VERSION ""

NS_ :

BS_:

BU_: OLDC EWP2 iBAU PSB EWP ESC EVP2 Dummy EVP1 SCU AAF eCALL H_U AEB IBOX LCA MCU SPAS CGW OBC TMU EPB SMK BCF MDPS CPD vDCM ACU vBDM AAF_2 CCM AAF_3 CLU ICSC LVR LDC CDM VCMS FCA IBU SCC PLC VCRM TCU EMS TPMS BMS NEMS LDW_LKA AAF_Tester DATC eCall VESS VCU ODS

BO_ 1301 CLU14: 8 CGW
 SG_ CF_Clu_ADrUNValueSet : 0|3@1+ (1,0) [0|7] ""  Dummy,vBDM
 SG_ CF_Clu_ADrLNValueSet : 3|3@1+ (1,0) [0|7] ""  Dummy
 SG_ CF_Clu_EscortHLNValueSet : 6|2@1+ (1,0) [0|3] ""  Dummy
 SG_ CF_Clu_DoorLSNValueSet : 8|3@1+ (1,0) [0|7] ""  Dummy
 SG_ CF_Clu_PSMNValueSet : 11|3@1+ (1,0) [0|7] ""  Dummy
 SG_ CF_Clu_TTUnlockNValueSet : 14|2@1+ (1,0) [0|3] ""  Dummy
 SG_ CF_Clu_ATTurnNValueSet : 16|2@1+ (1,0) [0|3] ""  Dummy
 SG_ CF_Clu_SCMNValueSet : 18|2@1+ (1,0) [0|3] ""  Dummy
 SG_ CF_Clu_WlightNValueSet : 20|2@1+ (1,0) [0|3] ""  Dummy
 SG_ CF_Clu_TempUnitNValueSet : 22|2@1+ (1,0) [0|3] ""  DATC,TMU
 SG_ CF_Clu_TrfChgSet : 27|2@1+ (1,0) [0|3] ""  Dummy
 SG_ CF_Clu_OTTurnNValueSet : 29|3@1+ (1,0) [0|7] ""  Dummy
 SG_ CF_Clu_LcaNValueSet : 32|2@1+ (1,0) [0|3] ""  Dummy
 SG_ CF_Clu_RctaNValueSet : 34|2@1+ (1,0) [0|3] ""  Dummy
 SG_ CF_Clu_RcwNValueSet : 36|2@1+ (1,0) [0|3] ""  Dummy
 SG_ CF_Clu_EcsOffNValueSet : 38|3@1+ (1,0) [0|3] ""  iBAU
 SG_ CF_Clu_SccNaviCrvNValueSet : 41|2@1+ (1,0) [0|3] ""  Dummy
 SG_ CF_Clu_SccNaviCamNValueSet : 43|2@1+ (1,0) [0|3] ""  Dummy
 SG_ CF_Clu_SccAebNValueSet : 45|2@1+ (1,0) [0|3] ""  Dummy
 SG_ CF_Clu_LkasModeNValueSet : 47|2@1+ (1,0) [0|3] ""  Dummy
 SG_ CF_Clu_FcwNValueSet : 51|2@1+ (1,0) [0|3] ""  Dummy
 SG_ CF_Clu_PasSpkrLvNValueSet : 53|3@1+ (1,0) [0|7] ""  Dummy
 SG_ CF_Clu_SccDrvModeNValueSet : 56|3@1+ (1,0) [0|7] ""  Dummy
 SG_ CF_Clu_HAnBNValueSet : 59|2@1+ (1,0) [0|3] ""  Dummy
 SG_ CF_Clu_HfreeTrunkTgNValueSet : 61|3@1+ (1,0) [0|7] ""  Dummy

BO_ 1031 VCMS12: 8 VCMS
 SG_ CR_Cms_EVmaxPower : 48|16@1+ (10,0) [0|655350] "W"  BMS

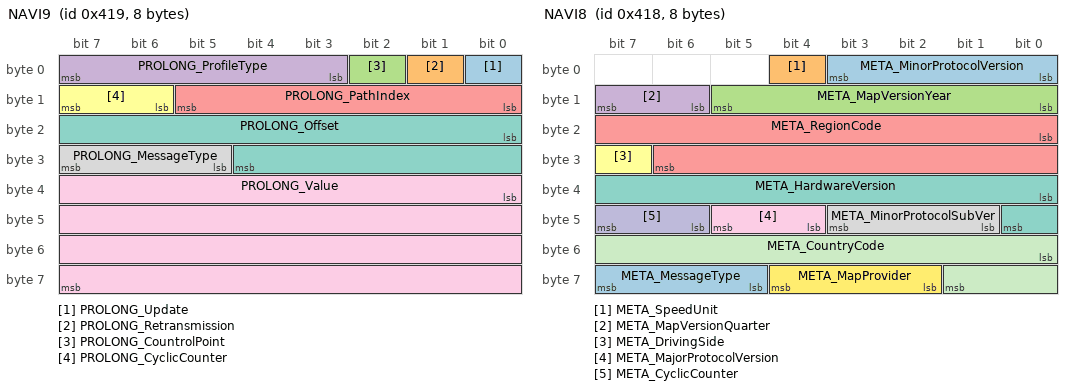
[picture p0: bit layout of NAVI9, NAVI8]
BO_ 1049 NAVI9: 8 CGW
 SG_ PROLONG_Update : 0|1@1+ (1,0) [0|1] ""  VCU
 SG_ PROLONG_Retransmission : 1|1@1+ (1,0) [0|1] ""  VCU
 SG_ PROLONG_CountrolPoint : 2|1@1+ (1,0) [0|1] ""  VCU
 SG_ PROLONG_ProfileType : 3|5@1+ (1,0) [0|31] ""  VCU
 SG_ PROLONG_PathIndex : 8|6@1+ (1,0) [0|63] ""  VCU
 SG_ PROLONG_CyclicCounter : 14|2@1+ (1,0) [0|3] ""  VCU
 SG_ PROLONG_Offset : 16|13@1+ (1,0) [0|8191] ""  VCU
 SG_ PROLONG_MessageType : 29|3@1+ (1,0) [0|7] ""  VCU
 SG_ PROLONG_Value : 32|32@1+ (1,0) [0|4294967295] ""  VCU

BO_ 1048 NAVI8: 8 CGW
 SG_ META_MinorProtocolVersion : 0|4@1+ (1,0) [0|0] ""  VCU
 SG_ META_SpeedUnit : 4|1@1+ (1,0) [0|0] ""  VCU
 SG_ META_MapVersionYear : 8|6@1+ (1,0) [0|0] ""  VCU
 SG_ META_MapVersionQuarter : 14|2@1+ (1,0) [0|0] ""  VCU
 SG_ META_RegionCode : 16|15@1+ (1,0) [0|0] ""  VCU
 SG_ META_DrivingSide : 31|1@1+ (1,0) [0|0] ""  VCU
 SG_ META_HardwareVersion : 32|9@1+ (1,0) [0|0] ""  VCU
 SG_ META_MinorProtocolSubVer : 41|3@1+ (1,0) [0|0] ""  VCU
 SG_ META_MajorProtocolVersion : 44|2@1+ (1,0) [0|0] ""  VCU
 SG_ META_CyclicCounter : 46|2@1+ (1,0) [0|0] ""  VCU
 SG_ META_CountryCode : 48|10@1+ (1,0) [0|0] ""  VCU
 SG_ META_MapProvider : 58|3@1+ (1,0) [0|0] ""  VCU
 SG_ META_MessageType : 61|3@1+ (1,0) [0|0] ""  VCU

BO_ 1051 NAVI11: 8 CGW
 SG_ SEG_DirectionLanes : 0|3@1+ (1,0) [0|7] ""  VCU
 SG_ SEG_OppositeLanes : 3|2@1+ (1,0) [0|3] ""  VCU
 SG_ SEG_DividedRoad : 5|2@1+ (1,0) [0|3] ""  VCU
 SG_ SEG_SpeedLimitType : 8|3@1+ (1,0) [0|7] ""  VCU
 SG_ SEG_SpeedLimit : 11|5@1+ (1,0) [0|31] ""  VCU
 SG_ SEG_FormOfWay : 16|4@1+ (1,0) [0|15] ""  VCU
 SG_ SEG_ComplexIntersection : 20|2@1+ (1,0) [0|3] ""  VCU
 SG_ SEG_CalculatedRoute : 22|2@1+ (1,0) [0|3] ""  VCU
 SG_ SEG_FunctionalRoadClass : 24|3@1+ (1,0) [0|7] ""  VCU
 SG_ SEG_RelativeProbability : 27|5@1+ (3.333,0) [0|31] ""  VCU
 SG_ SEG_Update : 32|1@1+ (1,0) [0|1] ""  VCU
 SG_ SEG_Retransmission : 33|1@1+ (1,0) [0|1] ""  VCU
 SG_ SEG_BuiltUpArea : 34|2@1+ (1,0) [0|3] ""  VCU
 SG_ SEG_Bridge : 36|2@1+ (1,0) [0|3] ""  VCU
 SG_ SEG_Tunnel : 38|2@1+ (1,0) [0|3] ""  VCU
 SG_ SEG_PathIndex : 40|6@1+ (1,0) [0|63] ""  VCU
 SG_ SEG_CyclicCounter : 46|2@1+ (1,0) [0|3] ""  VCU
 SG_ SEG_Offset : 48|13@1+ (1,0) [0|8191] ""  VCU
 SG_ SEG_MessageType : 61|3@1+ (1,0) [0|7] ""  VCU

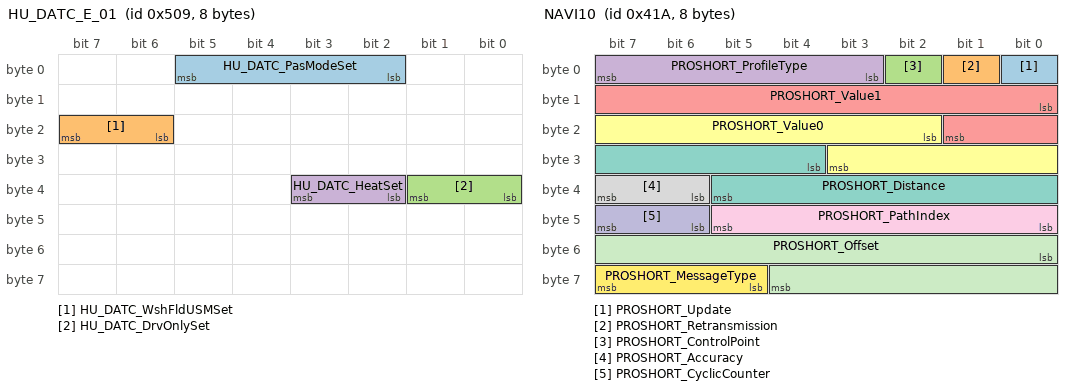
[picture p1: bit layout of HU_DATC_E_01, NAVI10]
BO_ 1289 HU_DATC_E_01: 8 CGW
 SG_ HU_DATC_PasModeSet : 2|4@1+ (1,0) [0|0] ""  DATC
 SG_ HU_DATC_WshFldUSMSet : 22|2@1+ (1,0) [0|3] ""  DATC
 SG_ HU_DATC_DrvOnlySet : 32|2@1+ (1,0) [0|0] ""  DATC
 SG_ HU_DATC_HeatSet : 34|2@1+ (1,0) [0|0] ""  DATC

BO_ 1050 NAVI10: 8 CGW
 SG_ PROSHORT_Update : 0|1@1+ (1,0) [0|1] ""  VCU
 SG_ PROSHORT_Retransmission : 1|1@1+ (1,0) [0|1] ""  VCU
 SG_ PROSHORT_ControlPoint : 2|1@1+ (1,0) [0|1] ""  VCU
 SG_ PROSHORT_ProfileType : 3|5@1+ (1,0) [0|31] ""  VCU
 SG_ PROSHORT_Value1 : 8|10@1+ (1,0) [0|1023] ""  VCU
 SG_ PROSHORT_Value0 : 18|10@1+ (1,0) [0|1023] ""  VCU
 SG_ PROSHORT_Distance : 28|10@1+ (1,0) [0|1023] ""  VCU
 SG_ PROSHORT_Accuracy : 38|2@1+ (1,0) [0|3] ""  VCU
 SG_ PROSHORT_PathIndex : 40|6@1+ (1,0) [0|63] ""  VCU
 SG_ PROSHORT_CyclicCounter : 46|2@1+ (1,0) [0|3] ""  VCU
 SG_ PROSHORT_Offset : 48|13@1+ (1,0) [0|8191] ""  VCU
 SG_ PROSHORT_MessageType : 61|3@1+ (1,0) [0|7] ""  VCU

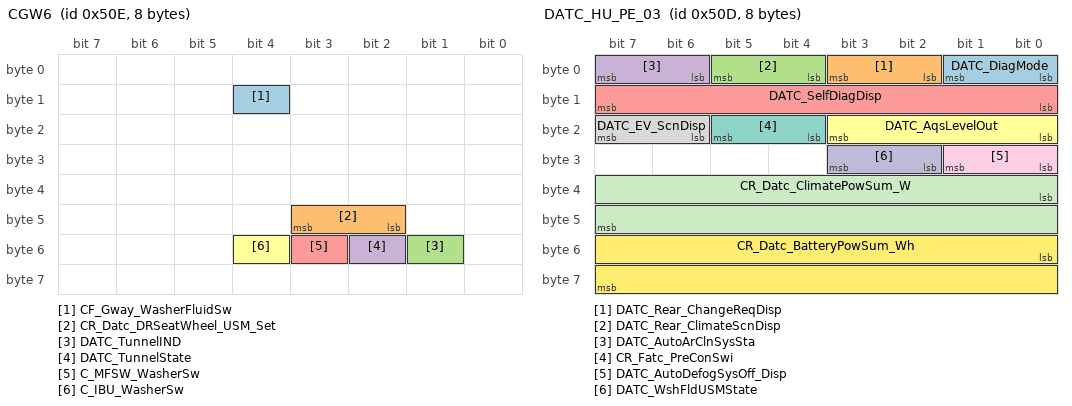
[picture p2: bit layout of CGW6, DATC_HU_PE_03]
BO_ 1294 CGW6: 8 CGW
 SG_ CF_Gway_WasherFluidSw : 12|1@1+ (1,0) [0|1] ""  H_U,vBDM
 SG_ CR_Datc_DRSeatWheel_USM_Set : 42|2@1+ (1,0) [0|3] ""  DATC
 SG_ DATC_TunnelIND : 49|1@1+ (1,0) [0|1] ""  DATC
 SG_ DATC_TunnelState : 50|1@1+ (1,0) [0|1] ""  DATC
 SG_ C_MFSW_WasherSw : 51|1@1+ (1,0) [0|1] ""  DATC
 SG_ C_IBU_WasherSw : 52|1@1+ (1,0) [0|1] ""  DATC

BO_ 1052 NAVI12: 8 CGW
 SG_ STUB_DirectionLanes : 0|3@1+ (1,0) [0|7] ""  VCU
 SG_ STUB_OppositeLanes : 3|2@1+ (1,0) [0|3] ""  VCU
 SG_ STUB_RightOfWay : 5|2@1+ (1,0) [0|3] ""  VCU
 SG_ STUB_LastStubAtOffset : 7|1@1+ (1,0) [0|1] ""  VCU
 SG_ STUB_TurnAngle : 8|8@1+ (1.417,0) [0|255] ""  VCU
 SG_ STUB_FormOfWay : 16|4@1+ (1,0) [0|15] ""  VCU
 SG_ STUB_ComplexIntersection : 20|2@1+ (1,0) [0|3] ""  VCU
 SG_ STUB_CalculatedRoute : 22|2@1+ (1,0) [0|3] ""  VCU
 SG_ STUB_FunctionalRoadClass : 24|3@1+ (1,0) [0|7] ""  VCU
 SG_ STUB_RelativeProbability : 27|5@1+ (3.333,0) [0|31] ""  VCU
 SG_ STUB_Update : 32|1@1+ (1,0) [0|1] ""  VCU
 SG_ STUB_Retransmission : 33|1@1+ (1,0) [0|1] ""  VCU
 SG_ STUB_SubPathIndex : 34|6@1+ (1,0) [0|63] ""  VCU
 SG_ STUB_PathIndex : 40|6@1+ (1,0) [0|63] ""  VCU
 SG_ STUB_CyclicCounter : 46|2@1+ (1,0) [0|3] ""  VCU
 SG_ STUB_Offset : 48|13@1+ (1,0) [0|8191] ""  VCU
 SG_ STUB_MessageType : 61|3@1+ (1,0) [0|7] ""  VCU

BO_ 1293 DATC_HU_PE_03: 8 DATC
 SG_ DATC_DiagMode : 0|2@1+ (1,0) [0|3] "flag"  CGW,TMU
 SG_ DATC_Rear_ChangeReqDisp : 2|2@1+ (1,0) [0|3] "flag"  CGW,TMU
 SG_ DATC_Rear_ClimateScnDisp : 4|2@1+ (1,0) [0|3] "flag"  CGW,TMU
 SG_ DATC_AutoArClnSysSta : 6|2@1+ (1,0) [0|3] ""  CGW
 SG_ DATC_SelfDiagDisp : 8|8@1+ (1,-1) [0|254] "flag"  CGW,TMU
 SG_ DATC_AqsLevelOut : 16|4@1+ (1,0) [0|3] "flag"  CGW,TMU
 SG_ CR_Fatc_PreConSwi : 20|2@1+ (1,0) [0|3] ""  CGW,TMU
 SG_ DATC_EV_ScnDisp : 22|2@1+ (1,0) [0|3] ""  CGW
 SG_ DATC_AutoDefogSysOff_Disp : 24|2@1+ (1,0) [0|3] ""  CGW
 SG_ DATC_WshFldUSMState : 26|2@1+ (1,0) [0|3] ""  CGW
 SG_ CR_Datc_ClimatePowSum_W : 32|16@1+ (1,0) [0|65534] "Wh"  CGW,TMU
 SG_ CR_Datc_BatteryPowSum_Wh : 48|16@1+ (1,0) [0|65534] "Wh"  CGW,TMU

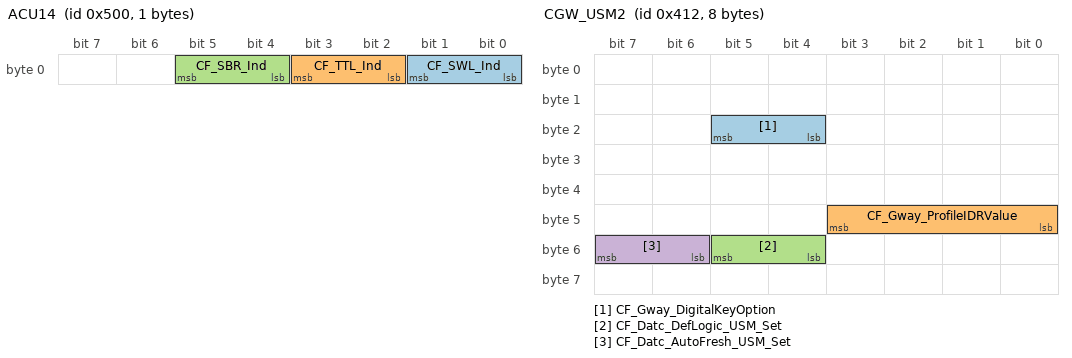
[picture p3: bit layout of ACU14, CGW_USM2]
BO_ 1280 ACU14: 1 ACU
 SG_ CF_SWL_Ind : 0|2@1+ (1,0) [0|3] ""  BMS
 SG_ CF_TTL_Ind : 2|2@1+ (1,0) [0|3] ""  BMS
 SG_ CF_SBR_Ind : 4|2@1+ (1,0) [0|3] ""  BMS

BO_ 1042 CGW_USM2: 8 CGW
 SG_ CF_Gway_DigitalKeyOption : 20|2@1+ (1,0) [0|0] ""  DATC
 SG_ CF_Gway_ProfileIDRValue : 40|4@1+ (1,0) [1|15] ""  DATC
 SG_ CF_Datc_DefLogic_USM_Set : 52|2@1+ (1,0) [0|3] ""  DATC
 SG_ CF_Datc_AutoFresh_USM_Set : 54|2@1+ (1,0) [0|3] ""  DATC

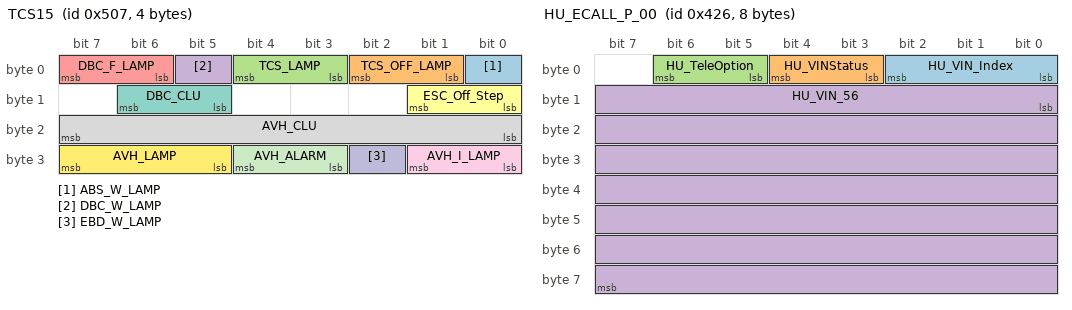
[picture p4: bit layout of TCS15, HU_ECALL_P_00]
BO_ 1287 TCS15: 4 iBAU
 SG_ ABS_W_LAMP : 0|1@1+ (1,0) [0|1] ""  CGW,H_U,NEMS,TMU,vBDM
 SG_ TCS_OFF_LAMP : 1|2@1+ (1,0) [0|1] ""  ACU,Dummy
 SG_ TCS_LAMP : 3|2@1+ (1,0) [0|3] ""  ACU,CGW,H_U,TMU,VCU
 SG_ DBC_W_LAMP : 5|1@1+ (1,0) [0|1] ""  CGW,H_U,TMU
 SG_ DBC_F_LAMP : 6|2@1+ (1,0) [0|3] ""  Dummy
 SG_ ESC_Off_Step : 8|2@1+ (1,0) [0|3] ""  Dummy
 SG_ DBC_CLU : 13|2@1+ (1,0) [0|3] ""  Dummy
 SG_ AVH_CLU : 16|8@1+ (1,0) [0|255] ""  Dummy
 SG_ AVH_I_LAMP : 24|2@1+ (1,0) [0|3] ""  Dummy
 SG_ EBD_W_LAMP : 26|1@1+ (1,0) [0|1] ""  CGW,H_U,TMU
 SG_ AVH_ALARM : 27|2@1+ (1,0) [0|3] ""  Dummy
 SG_ AVH_LAMP : 29|3@1+ (1,0) [0|7] ""  Dummy

BO_ 1044 MM_CGW1: 8 CGW
 SG_ CF_TMU_ICCB_InCurModeState : 0|2@1+ (1,0) [0|3] ""  OBC
 SG_ CF_TMU_EVSE_InCurModeState : 2|2@1+ (1,0) [0|3] ""  OBC

BO_ 852 LVR1: 8 LVR
 SG_ CF_Lvr_PButtonStatus : 0|2@1+ (1,0) [0|3] ""  CGW,VCU,vBDM
 SG_ CF_Lvr_RButtonStatus : 2|2@1+ (1,0) [0|3] ""  VCU
 SG_ CF_Lvr_NButtonStatus : 4|2@1+ (1,0) [0|3] ""  VCU
 SG_ CF_Lvr_DButtonStatus : 6|2@1+ (1,0) [0|3] ""  VCU
 SG_ CF_Lvr_UnLockButtonStatus : 8|2@1+ (1,0) [0|3] ""  VCU
 SG_ CF_Lvr_PRelStat : 10|2@1+ (1,0) [0|3] ""  SMK,VCU
 SG_ CF_Lvr_PosInf : 12|4@1+ (1,0) [0|15] ""  VCU
 SG_ CF_Lvr_PButtonStatus_Reversed : 16|2@1+ (1,0) [0|3] ""  VCU
 SG_ CF_Lvr_RButtonStatus_Reversed : 18|2@1+ (1,0) [0|3] ""  VCU
 SG_ CF_Lvr_NButtonStatus_Reversed : 20|2@1+ (1,0) [0|3] ""  VCU
 SG_ CF_Lvr_DButtonStatus_Reversed : 22|2@1+ (1,0) [0|3] ""  VCU
 SG_ CF_Lvr_UnLkButStatus_Reversed : 24|2@1+ (1,0) [0|3] ""  VCU
 SG_ CF_Lvr_PRelButStatus_Reversed : 26|2@1+ (1,0) [0|3] ""  VCU
 SG_ CF_Lvr_PosCpl : 28|4@1+ (1,0) [0|15] ""  VCU
 SG_ CF_Lvr_UnitStatus : 32|4@1+ (1,0) [0|0] ""  VCU
 SG_ CF_MoodLpColorRValue : 36|4@1+ (1,0) [0|0] ""  CGW
 SG_ CF_Lvr_IndicatorStatus : 40|8@1+ (1,0) [0|0] ""  VCU
 SG_ CF_Lvr_Wrn : 48|4@1+ (1,0) [0|7] ""  CGW,VCU
 SG_ CF_MoodLpBrightValue : 53|3@1+ (1,0) [0|0] ""  CGW
 SG_ CF_But_AC : 56|4@1+ (1,0) [0|15] ""  VCU
 SG_ CF_But_CS : 60|4@1+ (1,0) [0|15] ""  VCU

BO_ 1062 HU_ECALL_P_00: 8 CGW
 SG_ HU_VIN_Index : 0|3@1+ (1,0) [0|0] ""  BMS
 SG_ HU_VINStatus : 3|2@1+ (1,0) [0|0] ""  BMS
 SG_ HU_TeleOption : 5|2@1+ (1,0) [0|0] ""  BMS
 SG_ HU_VIN_56 : 8|56@1+ (1,0) [0|0] ""  BMS

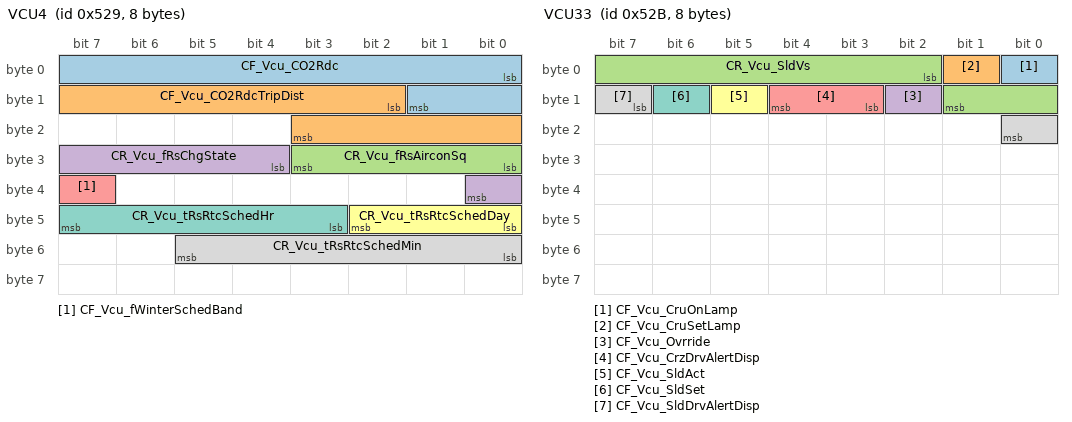
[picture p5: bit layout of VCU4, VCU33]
BO_ 1321 VCU4: 8 VCU
 SG_ CF_Vcu_CO2Rdc : 0|10@1+ (100,0) [0|102300] "g"  CGW
 SG_ CF_Vcu_CO2RdcTripDist : 10|10@1+ (1,0) [0|1023] "km"  CGW
 SG_ CR_Vcu_fRsAirconSq : 24|4@1+ (1,0) [0|0] ""  Dummy
 SG_ CR_Vcu_fRsChgState : 28|5@1+ (1,0) [0|0] ""  Dummy
 SG_ CF_Vcu_fWinterSchedBand : 39|1@1+ (1,0) [0|1] "flag"  BMS
 SG_ CR_Vcu_tRsRtcSchedDay : 40|3@1+ (1,0) [0|0] ""  Dummy
 SG_ CR_Vcu_tRsRtcSchedHr : 43|5@1+ (1,0) [0|0] ""  Dummy
 SG_ CR_Vcu_tRsRtcSchedMin : 48|6@1+ (1,0) [0|0] ""  Dummy

BO_ 1323 VCU33: 8 VCU
 SG_ CF_Vcu_CruOnLamp : 0|1@1+ (1,0) [0|1] ""  CGW,TMU,iBAU
 SG_ CF_Vcu_CruSetLamp : 1|1@1+ (1,0) [0|1] ""  CGW,TMU,iBAU
 SG_ CR_Vcu_SldVs : 2|8@1+ (1,0) [0|255] "km/h"  CGW,TMU,iBAU
 SG_ CF_Vcu_Ovrride : 10|1@1+ (1,0) [0|1] ""  CGW,TMU,iBAU
 SG_ CF_Vcu_CrzDrvAlertDisp : 11|2@1+ (1,0) [0|3] ""  CGW,TMU,iBAU
 SG_ CF_Vcu_SldAct : 13|1@1+ (1,0) [0|1] ""  CGW,TMU,iBAU
 SG_ CF_Vcu_SldSet : 14|1@1+ (1,0) [0|0] ""  CGW,TMU,iBAU
 SG_ CF_Vcu_SldDrvAlertDisp : 15|2@1+ (1,0) [0|3] ""  CGW,TMU,iBAU

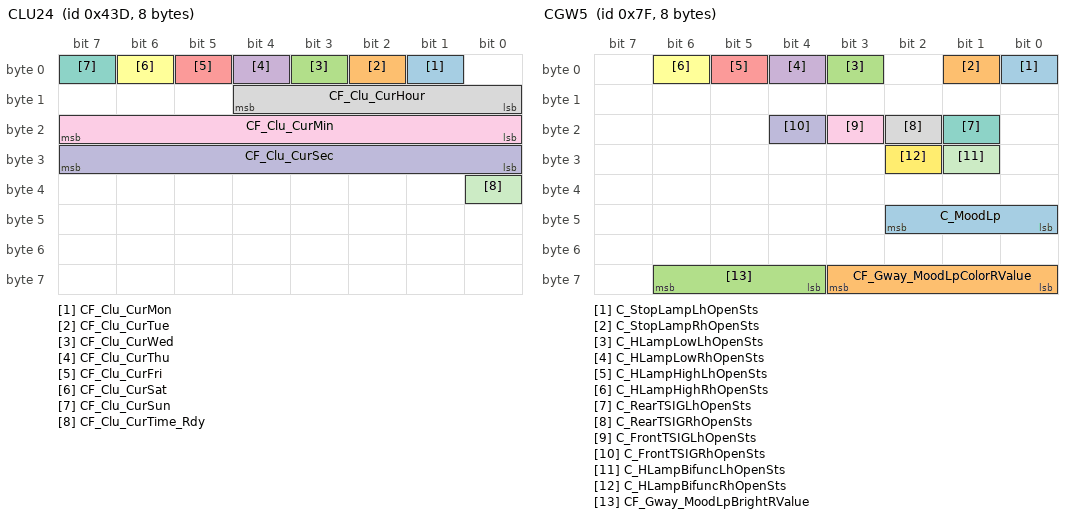
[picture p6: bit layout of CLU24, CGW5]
BO_ 1085 CLU24: 8 CGW
 SG_ CF_Clu_CurMon : 1|1@1+ (1,0) [0|1] ""  VCU
 SG_ CF_Clu_CurTue : 2|1@1+ (1,0) [0|1] ""  VCU
 SG_ CF_Clu_CurWed : 3|1@1+ (1,0) [0|1] ""  VCU
 SG_ CF_Clu_CurThu : 4|1@1+ (1,0) [0|1] ""  VCU
 SG_ CF_Clu_CurFri : 5|1@1+ (1,0) [0|1] ""  VCU
 SG_ CF_Clu_CurSat : 6|1@1+ (1,0) [0|1] ""  VCU
 SG_ CF_Clu_CurSun : 7|1@1+ (1,0) [0|1] ""  VCU
 SG_ CF_Clu_CurHour : 8|5@1+ (1,0) [0|23] "Hour"  VCU
 SG_ CF_Clu_CurMin : 16|8@1+ (1,0) [0|59] "min"  VCU
 SG_ CF_Clu_CurSec : 24|8@1+ (1,0) [0|59] "Sec"  VCU
 SG_ CF_Clu_CurTime_Rdy : 32|1@1+ (1,0) [0|1] "flag"  VCU

BO_ 1084 CLU23: 8 CGW
 SG_ CF_Clu_SchedChargNValueSet : 0|2@1+ (1,0) [0|2] ""  VCU
 SG_ CF_Clu_SchedClmtNValueSet : 2|2@1+ (1,0) [0|2] ""  VCU
 SG_ CF_Clu_SchedClmtDfrNValueSet : 4|2@1+ (1,0) [0|2] ""  VCU
 SG_ CF_Clu_BatteryHeatNValueSet : 6|2@1+ (1,0) [0|0] ""  VCU
 SG_ CF_Clu_DepartSunNValueSet : 8|2@1+ (1,0) [0|2] ""  VCU
 SG_ CF_Clu_DepartMonNValueSet : 10|2@1+ (1,0) [0|2] ""  VCU
 SG_ CF_Clu_SchedClmtTempNValueSet : 12|6@1+ (0.5,14) [15|32] "¡É"  VCU
 SG_ CF_Clu_DepartTueNValueSet : 18|2@1+ (1,0) [0|2] ""  VCU
 SG_ CF_Clu_DepartWedNValueSet : 20|2@1+ (1,0) [0|2] ""  VCU
 SG_ CF_Clu_DepartThuNValueSet : 22|2@1+ (1,0) [0|2] ""  VCU
 SG_ CF_Clu_DepartFriNValueSet : 24|2@1+ (1,0) [0|2] ""  VCU
 SG_ CF_Clu_DepartSatNValueSet : 26|2@1+ (1,0) [0|2] ""  VCU
 SG_ CF_Clu_DepartHourNValueSet : 28|5@1+ (1,0) [0|23] "Hour"  VCU
 SG_ CF_Clu_DepartMinNValueSet : 33|3@1+ (10,0) [0|50] "Min"  VCU
 SG_ CF_Clu_EVSE_InCurNValueSet : 36|2@1+ (1,0) [0|3] ""  OBC
 SG_ CF_Clu_ICCB_InCurNValueSet : 38|2@1+ (1,0) [0|3] ""  OBC
 SG_ CF_Clu_EcoRegenLvNValueSet : 40|2@1+ (1,0) [0|3] ""  VCU
 SG_ CF_Clu_NormalRegenLvNValueSet : 42|2@1+ (1,0) [0|3] ""  VCU
 SG_ CF_Clu_EconSTHourNValueSet : 44|5@1+ (1,0) [0|23] "Hour"  VCU
 SG_ CF_Clu_EconENDHourNValueSet : 49|5@1+ (1,0) [0|23] "Hour"  VCU

BO_ 127 CGW5: 8 CGW
 SG_ C_StopLampLhOpenSts : 0|1@1+ (1,0) [0|1] ""  H_U,vBDM
 SG_ C_StopLampRhOpenSts : 1|1@1+ (1,0) [0|1] ""  H_U,vBDM
 SG_ C_HLampLowLhOpenSts : 3|1@1+ (1,0) [0|1] ""  H_U,vBDM
 SG_ C_HLampLowRhOpenSts : 4|1@1+ (1,0) [0|1] ""  H_U,vBDM
 SG_ C_HLampHighLhOpenSts : 5|1@1+ (1,0) [0|1] ""  H_U,vBDM
 SG_ C_HLampHighRhOpenSts : 6|1@1+ (1,0) [0|1] ""  H_U,vBDM
 SG_ C_RearTSIGLhOpenSts : 17|1@1+ (1,0) [0|1] ""  H_U,vBDM
 SG_ C_RearTSIGRhOpenSts : 18|1@1+ (1,0) [0|1] ""  H_U,vBDM
 SG_ C_FrontTSIGLhOpenSts : 19|1@1+ (1,0) [0|1] ""  H_U,vBDM
 SG_ C_FrontTSIGRhOpenSts : 20|1@1+ (1,0) [0|1] ""  H_U,vBDM
 SG_ C_HLampBifuncLhOpenSts : 25|1@1+ (1,0) [0|1] ""  H_U,vBDM
 SG_ C_HLampBifuncRhOpenSts : 26|1@1+ (1,0) [0|1] ""  H_U,vBDM
 SG_ C_MoodLp : 40|3@1+ (1,0) [0|0] ""  LVR
 SG_ CF_Gway_MoodLpColorRValue : 56|4@1+ (1,0) [0|15] ""  LVR
 SG_ CF_Gway_MoodLpBrightRValue : 60|3@1+ (1,0) [0|7] ""  LVR

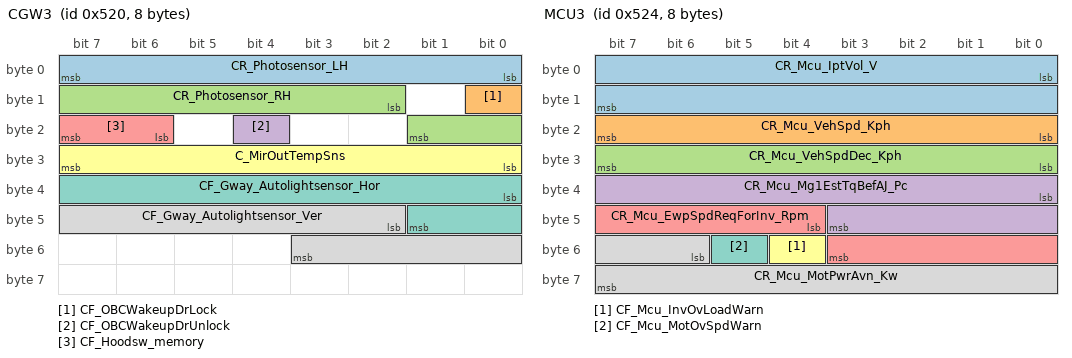
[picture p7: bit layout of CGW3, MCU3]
BO_ 1312 CGW3: 8 CGW
 SG_ CR_Photosensor_LH : 0|8@1+ (78.125,0) [0|19921.875] ""  DATC
 SG_ CF_OBCWakeupDrLock : 8|1@1+ (1,0) [0|1] ""  OBC
 SG_ CR_Photosensor_RH : 10|8@1+ (78.125,0) [0|19921.875] ""  DATC
 SG_ CF_OBCWakeupDrUnlock : 20|1@1+ (1,0) [0|1] ""  OBC
 SG_ CF_Hoodsw_memory : 22|2@1+ (1,0) [0|3] ""  Dummy
 SG_ C_MirOutTempSns : 24|8@1+ (0.5,-40) [-40|60] "¡É"  AAF,DATC
 SG_ CF_Gway_Autolightsensor_Hor : 32|10@1+ (1,0) [0|1023] ""  Dummy
 SG_ CF_Gway_Autolightsensor_Ver : 42|10@1+ (1,0) [0|1023] ""  Dummy

BO_ 1315 MCU2: 8 MCU
 SG_ CF_Mcu_Mg1Flt : 0|1@1+ (1,0) [0|1] ""  CGW,DATC,NEMS,TMU,VCU,iBAU
 SG_ CF_Mcu_Mg1Wrm : 1|1@1+ (1,0) [0|1] ""  CGW,TMU,VCU
 SG_ CF_Mcu_Mg1Ctrl : 2|1@1+ (1,0) [0|1] ""  CGW,NEMS,TMU,VCU
 SG_ CF_Mcu_Mg1Rdy : 3|1@1+ (1,0) [0|1] ""  AAF,AAF_2,AAF_3,ACU,BCF,BMS,CCM,CDM,CGW,CPD,DATC,Dummy,EWP,EWP2,H_U,IBU,LDC,LVR,OBC,ODS,PLC,SCU,SMK,TMU,VCU,VESS,eCall,iBAU,vBDM
 SG_ CF_Mcu_Mg1SvcLmp : 4|1@1+ (1,0) [0|1] ""  CGW,NEMS,TMU
 SG_ CF_Mcu_EwpOpReqToBMS : 5|1@1+ (1,0) [0|1] ""  BMS
 SG_ CF_Mcu_Mg1ActTest : 6|1@1+ (1,0) [0|1] ""  VCU
 SG_ CF_Mcu_Mg1AjActivate : 7|1@1+ (1,0) [0|1] ""  CGW,TMU,VCU
 SG_ CF_Mcu_Mg1RlyOffReq : 8|1@1+ (1,0) [0|1] ""  BMS,CGW,LDC,TMU,VCU
 SG_ CF_Mcu_HvIntlockReq : 9|1@1+ (1,0) [0|1] ""  BMS,DATC,LDC,OBC,VCU
 SG_ CF_Mcu_MotPwmOn : 10|1@1+ (1,0) [0|1] ""  BMS
 SG_ CF_Mcu_Mg1RsvCalReq : 11|1@1+ (1,0) [0|1] ""  VCU
 SG_ CF_Mcu_Mg1RsvCalStat : 12|3@1+ (1,0) [0|4] ""  VCU
 SG_ CF_Mcu_Mg1RsvCalNeeded : 15|1@1+ (1,0) [0|1] ""  CGW,TMU,VCU
 SG_ CR_Mcu_RotorTemp_C : 16|8@1+ (1,-40) [-40|215] "¡É"  VCU,iBAU
 SG_ CR_Mcu_Mg1IgbtTemp_C : 24|8@1+ (1,-40) [-40|215] "¡É"  AAF,CGW,LDC,TMU,VCU
 SG_ CR_Mcu_Mg1InvTemp_C : 32|8@1+ (1,-40) [-40|215] "¡É"  AAF,CGW,NEMS,OBC,TMU,VCU
 SG_ CR_Mcu_Mg1Temp_C : 40|8@1+ (1,-40) [-40|215] "¡É"  AAF,CGW,NEMS,TMU,VCU
 SG_ CR_Mcu_EwpSpdReq_Rpm : 48|8@1+ (20,0) [0|5000] "rpm"  BMS,CGW,EWP,OBC,TMU,VCU
 SG_ CF_Mcu_FatcLpChgInh : 56|1@1+ (1,0) [0|1] ""  BMS,DATC
 SG_ CF_Mcu_RadFanOprSts : 57|2@1+ (1,0) [0|2] ""  CGW,DATC,LDC,OBC,TMU
 SG_ CF_Mcu_EwpForcedOpSts : 59|1@1+ (1,0) [0|1] "flag"  BMS,DATC
 SG_ CF_Mcu_EwpCoolantDiagEnb : 60|1@1+ (1,0) [0|1] "flag"  BMS,EWP,EWP2,LDC
 SG_ CF_Mcu_EwpCoolantCluDisp : 61|1@1+ (1,0) [0|1] "flag"  BMS,CGW,LDC,TMU
 SG_ CF_Mcu_PgmRun2 : 62|2@1+ (1,0) [0|3] ""  VCU

BO_ 1316 MCU3: 8 MCU
 SG_ CR_Mcu_IptVol_V : 0|16@1+ (1,0) [0|65535] "V"  BMS,CGW,LDC,NEMS,OBC,TMU,VCU
 SG_ CR_Mcu_VehSpd_Kph : 16|8@1+ (1,0) [0|255] "kph"  AAF,ACU,BMS,CDM,CGW,DATC,IBU,LDC,OBC,ODS,SMK,TMU,VCU,VESS,vBDM
 SG_ CR_Mcu_VehSpdDec_Kph : 24|8@1+ (0.0078125,0) [0|0.99] "kph"  CDM,CGW,TMU,VESS
 SG_ CR_Mcu_Mg1EstTqBefAJ_Pc : 32|12@1- (0.048828125,0) [-100|99.951171875] "%"  VCU
 SG_ CR_Mcu_EwpSpdReqForInv_Rpm : 44|8@1+ (20,0) [0|5000] "rpm"  VCU
 SG_ CF_Mcu_InvOvLoadWarn : 52|1@1+ (1,0) [0|1] ""  CGW
 SG_ CF_Mcu_MotOvSpdWarn : 53|1@1+ (1,0) [0|1] ""  VCU
 SG_ CR_Mcu_MotPwrAvn_Kw : 54|10@1- (1,0) [-512|511] "kW"  AAF,CGW,LDC,TMU

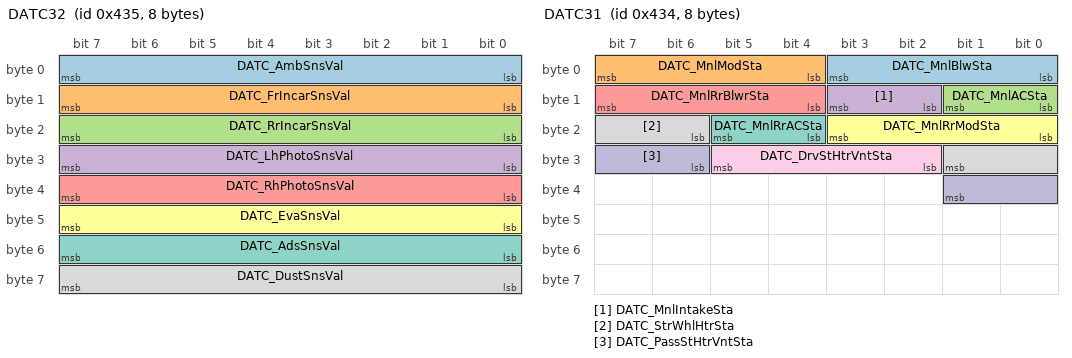
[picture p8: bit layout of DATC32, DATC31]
BO_ 1077 DATC32: 8 DATC
 SG_ DATC_AmbSnsVal : 0|8@1+ (0.5,-41) [-40|86.5] "¡É"  CGW,VCRM,vBDM
 SG_ DATC_FrIncarSnsVal : 8|8@1+ (0.5,-40) [-39.5|60] "¡É"  CGW,VCRM,vBDM
 SG_ DATC_RrIncarSnsVal : 16|8@1+ (0.5,-41) [-40|60] ""  CGW,VCRM,vBDM
 SG_ DATC_LhPhotoSnsVal : 24|8@1+ (0.02,0) [0|5] "V"  CGW,VCRM,vBDM
 SG_ DATC_RhPhotoSnsVal : 32|8@1+ (0.02,0) [0|5] "V"  CGW,VCRM,vBDM
 SG_ DATC_EvaSnsVal : 40|8@1+ (0.5,-40) [-40|60] "¡É"  CGW,VCRM,vBDM
 SG_ DATC_AdsSnsVal : 48|8@1+ (0.5,0) [0|5] ""  CGW,VCRM,vBDM
 SG_ DATC_DustSnsVal : 56|8@1+ (1,0) [0|250] ""  CGW,VCRM,vBDM

BO_ 1076 DATC31: 8 DATC
 SG_ DATC_MnlBlwSta : 0|4@1+ (1,0) [0|0] ""  CGW,VCRM,vBDM
 SG_ DATC_MnlModSta : 4|4@1+ (1,0) [0|0] ""  CGW,VCRM,vBDM
 SG_ DATC_MnlACSta : 8|2@1+ (1,0) [0|0] ""  CGW,VCRM,vBDM
 SG_ DATC_MnlIntakeSta : 10|2@1+ (1,0) [0|0] ""  CGW,VCRM,vBDM
 SG_ DATC_MnlRrBlwrSta : 12|4@1+ (1,0) [0|0] ""  CGW,VCRM,vBDM
 SG_ DATC_MnlRrModSta : 16|4@1+ (1,0) [0|0] ""  CGW,VCRM,vBDM
 SG_ DATC_MnlRrACSta : 20|2@1+ (1,0) [0|0] ""  CGW,VCRM,vBDM
 SG_ DATC_StrWhlHtrSta : 22|4@1+ (1,0) [0|0] ""  CGW,VCRM,vBDM
 SG_ DATC_DrvStHtrVntSta : 26|4@1+ (1,0) [0|0] ""  CGW,VCRM,vBDM
 SG_ DATC_PassStHtrVntSta : 30|4@1+ (1,0) [0|0] ""  CGW,VCRM,vBDM

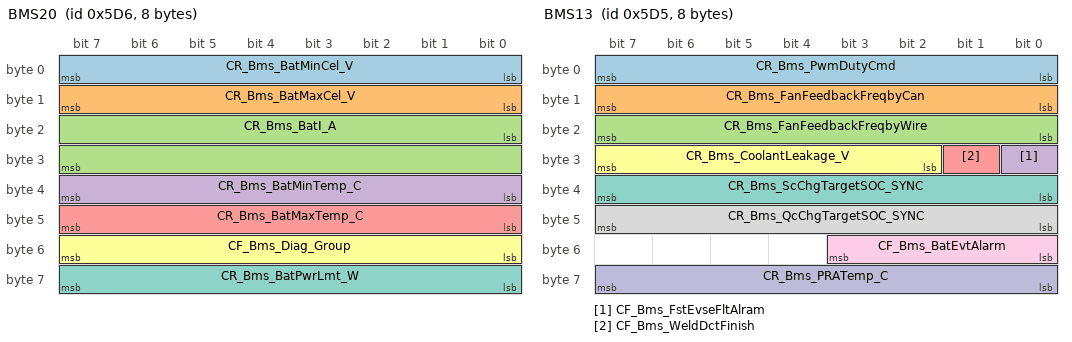
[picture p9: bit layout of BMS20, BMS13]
BO_ 1494 BMS20: 8 BMS
 SG_ CR_Bms_BatMinCel_V : 0|8@1+ (0.02,0) [0|5] "V"  CGW,TMU,vBDM
 SG_ CR_Bms_BatMaxCel_V : 8|8@1+ (0.02,0) [0|5] "V"  TMU
 SG_ CR_Bms_BatI_A : 16|16@1- (0.1,0) [-500|500] "A"  TMU
 SG_ CR_Bms_BatMinTemp_C : 32|8@1- (1,0) [-128|126] "¡É"  TMU
 SG_ CR_Bms_BatMaxTemp_C : 40|8@1- (1,0) [-128|126] "¡É"  TMU
 SG_ CF_Bms_Diag_Group : 48|8@1+ (1,0) [0|255] ""  TMU
 SG_ CR_Bms_BatPwrLmt_W : 56|8@1- (1,0) [-128|127] "W"  TMU

BO_ 1495 BMS21: 8 BMS
 SG_ CF_Bms_EvReady : 0|1@1+ (1,0) [0|1] "flag"  TMU
 SG_ CF_Bms_NoError : 1|1@1+ (1,0) [0|1] "flag"  TMU
 SG_ CF_Bms_Fail_Temp : 2|1@1+ (1,0) [0|1] "flag"  TMU
 SG_ CF_Bms_FAILED_EVShiftPosition : 3|1@1+ (1,0) [0|1] "flag"  TMU
 SG_ CF_Bms_Fail_Conlock : 4|1@1+ (1,0) [0|1] "flag"  TMU
 SG_ CF_Bms_Fail_Evmalf : 5|1@1+ (1,0) [0|1] "flag"  TMU
 SG_ CF_Bms_Fail_CurrDiff : 6|1@1+ (1,0) [0|1] "flag"  TMU
 SG_ CF_Bms_Fail_VoltRange : 7|1@1+ (1,0) [0|1] "flag"  TMU
 SG_ CF_Bms_Fail_ChgSysIncom : 8|1@1+ (1,0) [0|1] "flag"  TMU
 SG_ CF_Bms_ReadyToCharge : 9|1@1+ (1,0) [0|1] "flag"  TMU
 SG_ CF_Bms_ChgFinished : 10|1@1+ (1,0) [0|1] "flag"  CGW,H_U,TMU
 SG_ CF_Bms_PreparationStatusForPLC : 11|1@1+ (1,0) [0|1] "flag"  TMU
 SG_ CF_Bms_ReadyForCurDem : 12|1@1+ (1,0) [0|1] "flag"  TMU
 SG_ CF_Bms_IG3RlyOffEnable : 13|1@1+ (1,0) [0|1] "flag"  TMU
 SG_ CF_Bms_Charging_ST : 14|1@1+ (1,0) [0|1] ""  OBC,TMU
 SG_ CF_Bms_Lamp_Req : 15|1@1+ (1,0) [0|1] ""  CGW,H_U,TMU,vBDM
 SG_ CR_Bms_EVTargetCurrent : 16|16@1+ (0.1,0) [0|6553.5] "A"  TMU
 SG_ CF_Bms_BulkRemTime_Always : 32|16@1+ (1,0) [0|65535] "Sec"  CCM,CGW,vBDM
 SG_ CR_Bms_PLCChgFaultSubCode : 48|8@1+ (1,0) [1|255] ""  TMU
 SG_ CR_Bms_Chg_Curr_Req_Cha : 56|8@1+ (1,0) [0|255] "A"  TMU

BO_ 1492 IBOX_GW_PE_01: 8 CGW
 SG_ IBOX_IVRActivity : 0|2@1+ (1,0) [0|3] ""  DATC
 SG_ IBOX_PhoneActivity : 2|2@1+ (1,0) [0|3] ""  DATC

BO_ 1493 BMS13: 8 BMS
 SG_ CR_Bms_PwmDutyCmd : 0|8@1+ (1,0) [0|100] "%"  BCF
 SG_ CR_Bms_FanFeedbackFreqbyCan : 8|8@1+ (1,0) [0|255] ""  BCF
 SG_ CR_Bms_FanFeedbackFreqbyWire : 16|8@1+ (1,0) [0|255] ""  BCF
 SG_ CF_Bms_FstEvseFltAlram : 24|1@1+ (1,0) [0|1] "flag"  CLU
 SG_ CF_Bms_WeldDctFinish : 25|1@1+ (1,0) [0|1] "flag"  CCM
 SG_ CR_Bms_CoolantLeakage_V : 26|6@1+ (0.1,0) [0|6.3] "V"  Dummy
 SG_ CR_Bms_ScChgTargetSOC_SYNC : 32|8@1+ (0.5,0) [0|100] "%"  CGW,TMU,VCU
 SG_ CR_Bms_QcChgTargetSOC_SYNC : 40|8@1+ (0.5,0) [0|100] "%"  CGW,TMU
 SG_ CF_Bms_BatEvtAlarm : 48|4@1+ (1,0) [0|15] ""  CGW,H_U,MCU,VCU
 SG_ CR_Bms_PRATemp_C : 56|8@1- (2,0) [-256|252] "¡É"  CGW,Dummy,vBDM

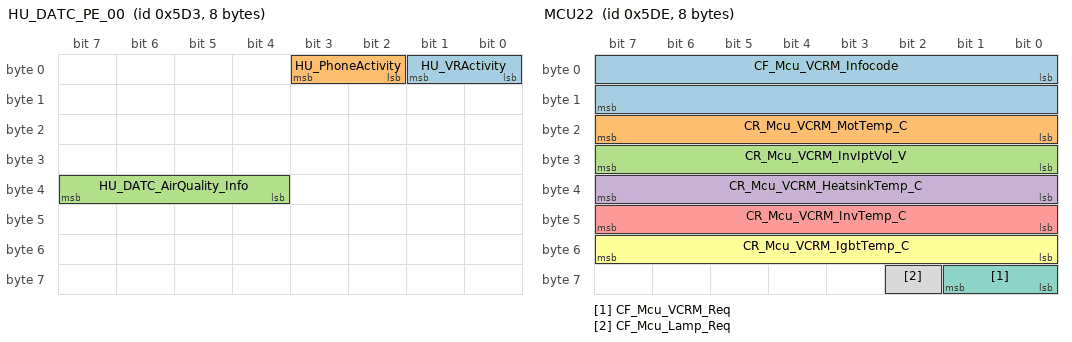
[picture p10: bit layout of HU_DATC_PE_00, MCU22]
BO_ 1491 HU_DATC_PE_00: 8 CGW
 SG_ HU_VRActivity : 0|2@1+ (1,0) [0|3] ""  DATC
 SG_ HU_PhoneActivity : 2|2@1+ (1,0) [0|3] ""  DATC
 SG_ HU_DATC_AirQuality_Info : 36|4@1+ (1,0) [0|0] ""  DATC

BO_ 1488 EV_CP1: 8 CGW
 SG_ CF_Clu_Odometer : 0|24@1+ (0.1,0) [0|1677721.5] "km"  AAF,BMS,H_U,IBU,LDC,MCU,NEMS,OBC,TMU,VCU,eCall
 SG_ CF_LKA_Opt_USM : 24|3@1+ (1,0) [0|7] ""  DATC

BO_ 1502 MCU22: 8 MCU
 SG_ CF_Mcu_VCRM_Infocode : 0|16@1+ (1,0) [0|65535] ""  TMU
 SG_ CR_Mcu_VCRM_MotTemp_C : 16|8@1+ (1,-40) [-40|215] "¡É"  TMU
 SG_ CR_Mcu_VCRM_InvIptVol_V : 24|8@1+ (3,0) [0|765] "V"  TMU
 SG_ CR_Mcu_VCRM_HeatsinkTemp_C : 32|8@1+ (1,-40) [-40|215] "¡É"  TMU
 SG_ CR_Mcu_VCRM_InvTemp_C : 40|8@1+ (1,-40) [-40|215] "¡É"  TMU
 SG_ CR_Mcu_VCRM_IgbtTemp_C : 48|8@1+ (1,-40) [-40|215] "¡É"  TMU
 SG_ CF_Mcu_VCRM_Req : 56|2@1+ (1,0) [0|3] ""  CGW,H_U,TMU,vBDM
 SG_ CF_Mcu_Lamp_Req : 58|1@1+ (1,0) [0|1] ""  CGW,H_U,TMU

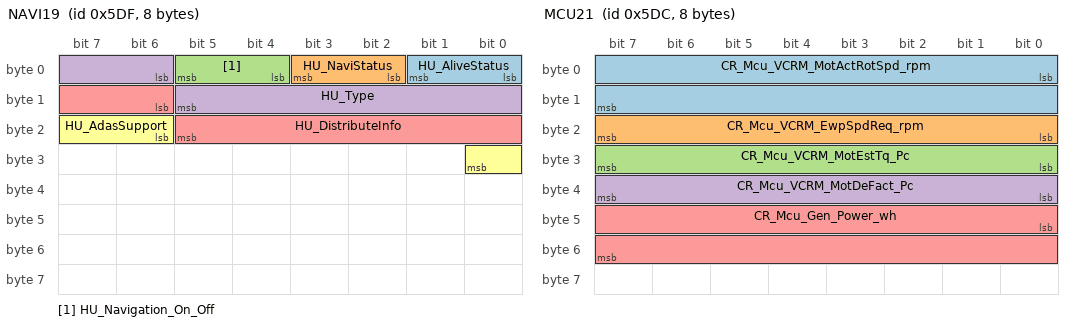
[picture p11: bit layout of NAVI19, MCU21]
BO_ 1503 NAVI19: 8 CGW
 SG_ HU_AliveStatus : 0|2@1+ (1,0) [0|1] ""  VCU
 SG_ HU_NaviStatus : 2|2@1+ (1,0) [0|0] ""  VCU
 SG_ HU_Navigation_On_Off : 4|2@1+ (1,0) [0|0] ""  VCU
 SG_ HU_Type : 6|8@1+ (1,0) [0|0] ""  OBC,VCU
 SG_ HU_DistributeInfo : 14|8@1+ (1,0) [0|0] ""  VCU
 SG_ HU_AdasSupport : 22|3@1+ (1,0) [0|0] ""  VCU

BO_ 1500 MCU21: 8 MCU
 SG_ CR_Mcu_VCRM_MotActRotSpd_rpm : 0|16@1- (1,0) [-32768|32767] "rpm"  CGW,TMU,vBDM
 SG_ CR_Mcu_VCRM_EwpSpdReq_rpm : 16|8@1+ (20,0) [0|5000] ""  TMU
 SG_ CR_Mcu_VCRM_MotEstTq_Pc : 24|8@1- (0.78125,0) [-100|99.21] "%"  TMU
 SG_ CR_Mcu_VCRM_MotDeFact_Pc : 32|8@1+ (0.3906,0) [0|99.61] "%"  TMU
 SG_ CR_Mcu_Gen_Power_wh : 40|16@1+ (1,0) [0|65534] "Wh"  CGW

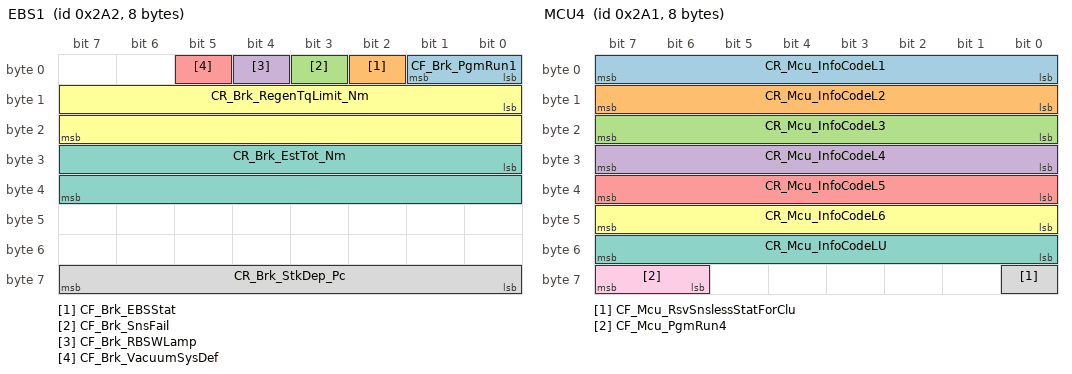
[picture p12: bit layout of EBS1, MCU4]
BO_ 674 EBS1: 8 iBAU
 SG_ CF_Brk_PgmRun1 : 0|2@1+ (1,0) [0|3] ""  TMU,VCU
 SG_ CF_Brk_EBSStat : 2|1@1+ (1,0) [0|1] ""  TMU,VCU
 SG_ CF_Brk_SnsFail : 3|1@1+ (1,0) [0|1] ""  CGW,TMU,VCU,vBDM
 SG_ CF_Brk_RBSWLamp : 4|1@1+ (1,0) [0|1] ""  CGW,TMU,VCU
 SG_ CF_Brk_VacuumSysDef : 5|1@1+ (1,0) [0|1] ""  TMU,VCU
 SG_ CR_Brk_RegenTqLimit_Nm : 8|16@1+ (1,0) [0|65535] "Nm"  TMU,VCU
 SG_ CR_Brk_EstTot_Nm : 24|16@1+ (1,0) [0|65535] "Nm"  MCU,TMU,VCU
 SG_ CR_Brk_StkDep_Pc : 56|8@1+ (0.39215,0) [0|100] "%"  CGW,MCU,NEMS,TMU,VCU

BO_ 673 MCU4: 8 MCU
 SG_ CR_Mcu_InfoCodeL1 : 0|8@1+ (1,0) [0|255] ""  CGW,VCU,vBDM
 SG_ CR_Mcu_InfoCodeL2 : 8|8@1+ (1,0) [0|255] ""  VCU
 SG_ CR_Mcu_InfoCodeL3 : 16|8@1+ (1,0) [0|255] ""  VCU
 SG_ CR_Mcu_InfoCodeL4 : 24|8@1+ (1,0) [0|255] ""  VCU
 SG_ CR_Mcu_InfoCodeL5 : 32|8@1+ (1,0) [0|255] ""  VCU
 SG_ CR_Mcu_InfoCodeL6 : 40|8@1+ (1,0) [0|255] ""  VCU
 SG_ CR_Mcu_InfoCodeLU : 48|8@1+ (1,0) [0|255] ""  VCU
 SG_ CF_Mcu_RsvSnslessStatForClu : 56|1@1+ (1,0) [0|1] "flag"  CGW
 SG_ CF_Mcu_PgmRun4 : 62|2@1+ (1,0) [0|3] ""  VCU

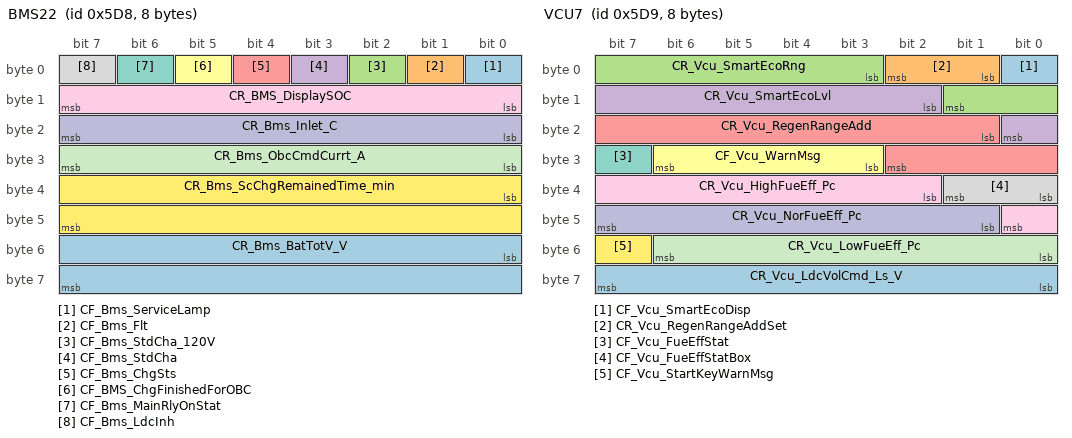
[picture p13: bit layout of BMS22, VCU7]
BO_ 1496 BMS22: 8 BMS
 SG_ CF_Bms_ServiceLamp : 0|1@1+ (1,0) [0|1] ""  TMU
 SG_ CF_Bms_Flt : 1|1@1+ (1,0) [0|1] ""  CGW,H_U,TMU,vBDM
 SG_ CF_Bms_StdCha_120V : 2|1@1+ (1,0) [0|1] "flag"  CGW,H_U,TMU
 SG_ CF_Bms_StdCha : 3|1@1+ (1,0) [0|1] ""  CGW,H_U,TMU
 SG_ CF_Bms_ChgSts : 4|1@1+ (1,0) [0|1] ""  CDM,CGW,DATC,H_U,TMU
 SG_ CF_BMS_ChgFinishedForOBC : 5|1@1+ (1,0) [0|1] ""  CGW,H_U,TMU
 SG_ CF_Bms_MainRlyOnStat : 6|1@1+ (1,0) [0|1] ""  TMU
 SG_ CF_Bms_LdcInh : 7|1@1+ (1,0) [0|1] ""  TMU
 SG_ CR_BMS_DisplaySOC : 8|8@1+ (0.5,0) [0|100] "%"  CDM,CGW,H_U,TMU
 SG_ CR_Bms_Inlet_C : 16|8@1- (1,0) [-128|127] "¡É"  TMU
 SG_ CR_Bms_ObcCmdCurrt_A : 24|8@1+ (0.1,0) [0|25] "A"  TMU
 SG_ CR_Bms_ScChgRemainedTime_min : 32|16@1+ (1,0) [0|65535] "min"  CGW,H_U,TMU
 SG_ CR_Bms_BatTotV_V : 48|16@1+ (0.1,0) [0|500] "V"  TMU

BO_ 1497 VCU7: 8 VCU
 SG_ CF_Vcu_SmartEcoDisp : 0|1@1+ (1,0) [0|1] ""  CGW,vBDM
 SG_ CR_Vcu_RegenRangeAddSet : 1|2@1+ (1,0) [0|3] ""  CGW
 SG_ CR_Vcu_SmartEcoRng : 3|7@1+ (1,0) [0|100] "%"  CGW
 SG_ CR_Vcu_SmartEcoLvl : 10|7@1+ (1,0) [0|100] "%"  CGW
 SG_ CR_Vcu_RegenRangeAdd : 17|10@1+ (10,0) [0|10230] "m"  CGW
 SG_ CF_Vcu_WarnMsg : 27|4@1+ (1,0) [0|15] ""  CGW
 SG_ CF_Vcu_FueEffStat : 31|1@1+ (1,0) [0|1] ""  CGW
 SG_ CF_Vcu_FueEffStatBox : 32|2@1+ (1,0) [0|3] ""  CGW
 SG_ CR_Vcu_HighFueEff_Pc : 34|7@1+ (1,0) [0|100] "%"  CGW
 SG_ CR_Vcu_NorFueEff_Pc : 41|7@1+ (1,0) [0|100] "%"  CGW
 SG_ CR_Vcu_LowFueEff_Pc : 48|7@1+ (1,0) [0|100] "%"  CGW
 SG_ CF_Vcu_StartKeyWarnMsg : 55|1@1+ (1,0) [0|1] ""  CGW
 SG_ CR_Vcu_LdcVolCmd_Ls_V : 56|8@1+ (0.1,0) [12.5|15.1] ""  OLDC

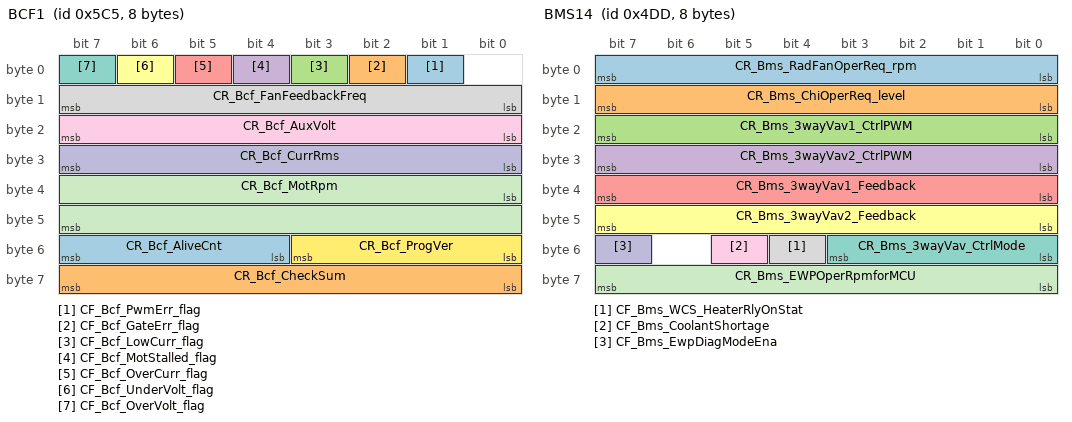
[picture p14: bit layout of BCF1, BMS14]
BO_ 1477 BCF1: 8 BCF
 SG_ CF_Bcf_PwmErr_flag : 1|1@1+ (1,0) [0|1] ""  BMS
 SG_ CF_Bcf_GateErr_flag : 2|1@1+ (1,0) [0|1] ""  BMS
 SG_ CF_Bcf_LowCurr_flag : 3|1@1+ (1,0) [0|1] ""  BMS
 SG_ CF_Bcf_MotStalled_flag : 4|1@1+ (1,0) [0|1] ""  BMS
 SG_ CF_Bcf_OverCurr_flag : 5|1@1+ (1,0) [0|1] ""  BMS
 SG_ CF_Bcf_UnderVolt_flag : 6|1@1+ (1,0) [0|1] ""  BMS
 SG_ CF_Bcf_OverVolt_flag : 7|1@1+ (1,0) [0|1] ""  BMS
 SG_ CR_Bcf_FanFeedbackFreq : 8|8@1+ (1,0) [0|255] ""  BMS
 SG_ CR_Bcf_AuxVolt : 16|8@1+ (0.1,0) [0|25.3] "V"  BMS
 SG_ CR_Bcf_CurrRms : 24|8@1+ (0.1,0) [0|25.4] "A"  BMS
 SG_ CR_Bcf_MotRpm : 32|16@1+ (1,0) [0|65534] "rpm"  BMS
 SG_ CR_Bcf_ProgVer : 48|4@1+ (1,0) [0|15] ""  BMS
 SG_ CR_Bcf_AliveCnt : 52|4@1+ (1,0) [0|15] ""  BMS
 SG_ CR_Bcf_CheckSum : 56|8@1+ (1,0) [0|255] ""  BMS

BO_ 1474 CLU22: 8 CGW
 SG_ CF_Clu_InletAutoLockNValueSet : 8|3@1+ (1,0) [0|7] ""  OBC

BO_ 1245 BMS14: 8 BMS
 SG_ CR_Bms_RadFanOperReq_rpm : 0|8@1+ (20,0) [0|5000] "rpm"  CGW,MCU,vBDM
 SG_ CR_Bms_ChiOperReq_level : 8|8@1+ (20,0) [0|5000] "rpm"  AAF,DATC
 SG_ CR_Bms_3wayVav1_CtrlPWM : 16|8@1+ (1,0) [0|100] "%"  Dummy
 SG_ CR_Bms_3wayVav2_CtrlPWM : 24|8@1+ (1,0) [0|100] "%"  Dummy
 SG_ CR_Bms_3wayVav1_Feedback : 32|8@1+ (0.1,0) [0|25.4] "V"  Dummy
 SG_ CR_Bms_3wayVav2_Feedback : 40|8@1+ (0.1,0) [0|25.4] "V"  Dummy
 SG_ CR_Bms_3wayVav_CtrlMode : 48|4@1+ (1,0) [0|1] ""  AAF,DATC,Dummy
 SG_ CF_Bms_WCS_HeaterRlyOnStat : 52|1@1+ (1,0) [0|1] ""  CGW,Dummy
 SG_ CF_Bms_CoolantShortage : 53|1@1+ (1,0) [0|1] ""  CGW
 SG_ CF_Bms_EwpDiagModeEna : 55|1@1+ (1,0) [0|1] "flag"  Dummy,EWP2
 SG_ CR_Bms_EWPOperRpmforMCU : 56|8@1+ (20,0) [0|5000] "rpm"  MCU,VCU

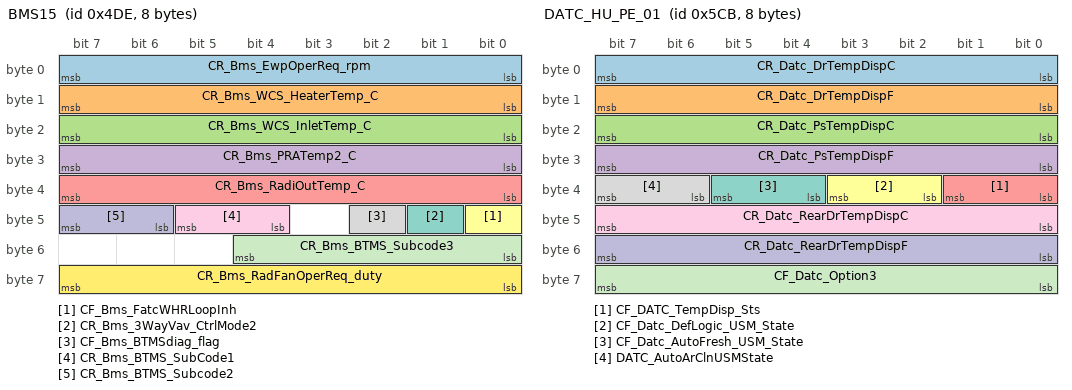
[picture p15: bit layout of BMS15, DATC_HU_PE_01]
BO_ 1246 BMS15: 8 BMS
 SG_ CR_Bms_EwpOperReq_rpm : 0|8@1+ (20,0) [0|5000] "rpm"  EWP2
 SG_ CR_Bms_WCS_HeaterTemp_C : 8|8@1- (1,0) [-128|126] "¡É"  Dummy
 SG_ CR_Bms_WCS_InletTemp_C : 16|8@1- (1,0) [-128|126] "¡É"  CGW,Dummy,vBDM
 SG_ CR_Bms_PRATemp2_C : 24|8@1- (2,0) [-256|252] "¡É"  Dummy
 SG_ CR_Bms_RadiOutTemp_C : 32|8@1- (1,0) [-128|126] "¡É"  DATC,Dummy
 SG_ CF_Bms_FatcWHRLoopInh : 40|1@1+ (1,0) [0|1] "flag"  DATC
 SG_ CR_Bms_3WayVav_CtrlMode2 : 41|1@1+ (1,0) [0|1] ""  Dummy,MCU,OBC
 SG_ CF_Bms_BTMSdiag_flag : 42|1@1+ (1,0) [0|1] "flag"  MCU,VCU
 SG_ CR_Bms_BTMS_SubCode1 : 44|2@1+ (1,0) [0|3] ""  Dummy
 SG_ CR_Bms_BTMS_Subcode2 : 46|2@1+ (1,0) [0|3] ""  Dummy
 SG_ CR_Bms_BTMS_Subcode3 : 48|5@1+ (1,0) [0|31] ""  Dummy
 SG_ CR_Bms_RadFanOperReq_duty : 56|8@1+ (1,0) [0|100] "%"  MCU,VCU

BO_ 1484 DATC_HU_PE_02: 8 DATC
 SG_ DATC_ModeDisp : 0|4@1+ (1,0) [0|15] "flag"  CGW,TMU
 SG_ DATC_TempUnit : 4|2@1+ (1,0) [0|3] "flag"  CGW,H_U,TMU,VCU
 SG_ DATC_SepzoneDisp : 6|2@1+ (1,0) [0|3] "flag"  CGW,TMU
 SG_ DATC_AutoDisp : 8|2@1+ (1,0) [0|3] "flag"  CGW,TMU,VCU
 SG_ DATC_IntakeDisp : 10|2@1+ (1,0) [0|3] "flag"  CGW,TMU
 SG_ DATC_ChangeReqDisp : 12|2@1+ (1,0) [0|3] "flag"  CGW,TMU
 SG_ CF_Datc_Text_PopupReq : 14|2@1+ (1,0) [0|3] ""  CGW
 SG_ DATC_AcDisp : 16|2@1+ (1,0) [0|3] "flag"  CGW,TMU,VCU
 SG_ DATC_AqsDisp : 18|2@1+ (1,0) [0|3] "flag"  CGW,TMU
 SG_ DATC_ClimateScnDisp : 20|2@1+ (1,0) [0|3] "flag"  CGW,TMU
 SG_ DATC_AirCleaningSystemStatus : 22|2@1+ (1,0) [0|3] ""  CGW
 SG_ DATC_SyncDisp : 24|2@1+ (1,0) [0|3] "flag"  CGW,TMU
 SG_ CF_Datc_BlowerAutoDisp : 26|2@1+ (1,0) [0|3] ""  CGW
 SG_ DATC_OpSts : 28|3@1+ (1,0) [0|7] "flag"  CGW,TMU
 SG_ DATC_RearManual : 32|2@1+ (1,0) [0|3] "flag"  CGW,TMU
 SG_ DATC_HeatDisp : 34|2@1+ (1,0) [0|3] "flag"  CGW,TMU,VCU
 SG_ DATC_FrDefLed : 36|2@1+ (1,0) [0|3] "flag"  CGW,H_U,TMU,VCU
 SG_ CF_Datc_ModAutoDisp : 38|2@1+ (1,0) [0|3] ""  CGW
 SG_ DATC_AutoDefogBlink : 40|2@1+ (1,0) [0|3] "flag"  CGW,TMU
 SG_ CF_Datc_IntakeStatus : 42|2@1+ (1,0) [0|3] ""  CGW
 SG_ DATC_IonClean : 44|2@1+ (1,0) [0|3] "flag"  CGW,TMU
 SG_ DATC_CO2Warning : 46|2@1+ (1,0) [0|3] "flag"  CGW,TMU
 SG_ DATC_SubBlowerDisp : 48|4@1+ (1,0) [0|15] "flag"  CGW,TMU
 SG_ DATC_BeepReq : 52|4@1+ (1,0) [0|15] "flag"  CGW,TMU
 SG_ DATC_MainBlowerDisp : 56|4@1+ (1,0) [0|15] "flag"  CGW,H_U,TMU,VCU
 SG_ DATC_PsModeDisp : 60|4@1+ (1,0) [0|15] "flag"  CGW,TMU

BO_ 1483 DATC_HU_PE_01: 8 DATC
 SG_ CR_Datc_DrTempDispC : 0|8@1+ (0.5,14) [15|32] "¡É"  CGW,H_U,TMU,VCU,vBDM
 SG_ CR_Datc_DrTempDispF : 8|8@1+ (1,56) [58|90] "¢µ"  CGW,H_U,TMU,VCU
 SG_ CR_Datc_PsTempDispC : 16|8@1+ (0.5,14) [15|32] "¡É"  CGW,TMU
 SG_ CR_Datc_PsTempDispF : 24|8@1+ (1,56) [58|90] "¢µ"  CGW,TMU
 SG_ CF_DATC_TempDisp_Sts : 32|2@1+ (1,0) [0|3] ""  CGW,H_U,TMU
 SG_ CF_Datc_DefLogic_USM_State : 34|2@1+ (1,0) [0|3] ""  CGW
 SG_ CF_Datc_AutoFresh_USM_State : 36|2@1+ (1,0) [0|3] ""  CGW
 SG_ DATC_AutoArClnUSMState : 38|2@1+ (1,0) [0|3] ""  CGW
 SG_ CR_Datc_RearDrTempDispC : 40|8@1+ (0.5,14) [15|32] "¡É"  CGW,TMU
 SG_ CR_Datc_RearDrTempDispF : 48|8@1+ (1,56) [58|90] "¢µ"  CGW,TMU
 SG_ CF_Datc_Option3 : 56|8@1+ (1,0) [0|255] ""  CGW

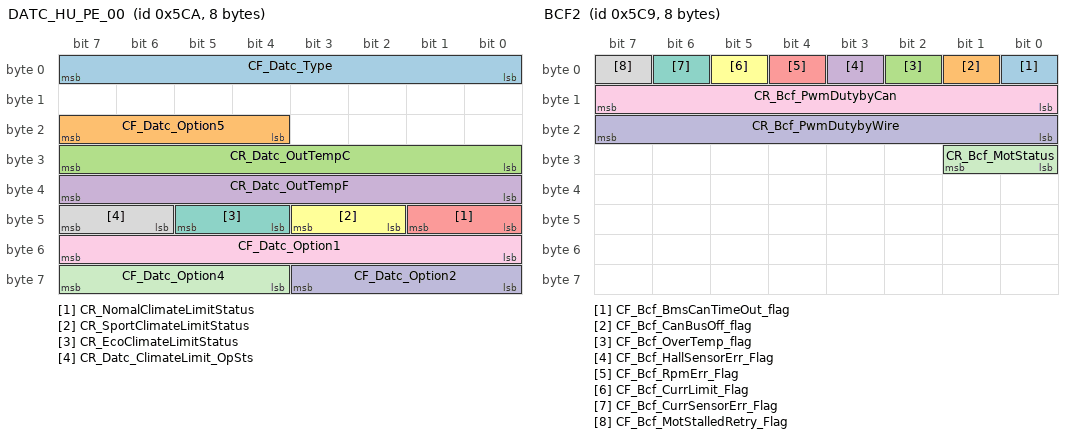
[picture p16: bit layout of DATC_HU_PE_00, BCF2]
BO_ 1482 DATC_HU_PE_00: 8 DATC
 SG_ CF_Datc_Type : 0|8@1+ (1,0) [0|255] "flag"  CGW,TMU
 SG_ CF_Datc_Option5 : 20|4@1+ (1,0) [0|0] ""  CGW
 SG_ CR_Datc_OutTempC : 24|8@1+ (0.5,-41) [-41|86.5] "¡É"  CGW,TMU
 SG_ CR_Datc_OutTempF : 32|8@1+ (1,-42) [-42|213] "¡É"  CGW,TMU
 SG_ CR_NomalClimateLimitStatus : 40|2@1+ (1,0) [0|3] ""  CGW,VCU
 SG_ CR_SportClimateLimitStatus : 42|2@1+ (1,0) [0|3] ""  CGW,VCU
 SG_ CR_EcoClimateLimitStatus : 44|2@1+ (1,0) [0|3] ""  CGW,VCU
 SG_ CR_Datc_ClimateLimit_OpSts : 46|2@1+ (1,0) [0|3] ""  CGW,VCU
 SG_ CF_Datc_Option1 : 48|8@1+ (1,0) [0|255] "flag"  CGW,TMU
 SG_ CF_Datc_Option2 : 56|4@1+ (1,0) [0|15] "flag"  CGW,TMU
 SG_ CF_Datc_Option4 : 60|4@1+ (1,0) [0|0] ""  CGW

BO_ 1481 BCF2: 8 BCF
 SG_ CF_Bcf_BmsCanTimeOut_flag : 0|1@1+ (1,0) [0|1] ""  BMS
 SG_ CF_Bcf_CanBusOff_flag : 1|1@1+ (1,0) [0|1] ""  BMS
 SG_ CF_Bcf_OverTemp_flag : 2|1@1+ (1,0) [0|1] ""  BMS
 SG_ CF_Bcf_HallSensorErr_Flag : 3|1@1+ (1,0) [0|1] ""  BMS
 SG_ CF_Bcf_RpmErr_Flag : 4|1@1+ (1,0) [0|1] ""  BMS
 SG_ CF_Bcf_CurrLimit_Flag : 5|1@1+ (1,0) [0|1] ""  BMS
 SG_ CF_Bcf_CurrSensorErr_Flag : 6|1@1+ (1,0) [0|1] ""  BMS
 SG_ CF_Bcf_MotStalledRetry_Flag : 7|1@1+ (1,0) [0|1] ""  BMS
 SG_ CR_Bcf_PwmDutybyCan : 8|8@1+ (1,0) [0|100] "%"  BMS
 SG_ CR_Bcf_PwmDutybyWire : 16|8@1+ (1,0) [0|100] "%"  BMS
 SG_ CR_Bcf_MotStatus : 24|2@1+ (1,0) [0|3] ""  BMS

BO_ 1525 DATC1: 8 DATC
 SG_ CF_Datc_AcnReqSwi : 0|1@1+ (1,0) [0|1] ""  AAF,TMU,VCU
 SG_ CF_Datc_BlrOn : 1|1@1+ (1,0) [0|1] ""  BMS,CGW,LDC,TMU,VCU,vBDM
 SG_ CF_Datc_PtcOnReq : 2|1@1+ (1,0) [0|1] ""  TMU,VCU
 SG_ CF_Datc_AcnCompOperStat : 5|1@1+ (1,0) [0|1] ""  LDC,MCU,TMU,VCU
 SG_ CF_Datc_PTCOperStat : 6|1@1+ (1,0) [0|1] ""  LDC,TMU,VCU
 SG_ CF_Datc_BlwrMax : 7|1@1+ (1,0) [0|1] ""  LDC,TMU
 SG_ CR_Datc_AcnComMaxReq_W : 8|6@1+ (200,0) [0|8000] "W"  TMU,VCU
 SG_ CR_Datc_AcnCompPwrCon_W : 14|10@1+ (10,0) [0|8000] "W"  AAF,CGW,TMU,VCU
 SG_ CR_Datc_AptVal_PSI : 24|8@1+ (2,0) [0|508] "PSI"  AAF,MCU,TMU
 SG_ CF_Datc_MsgCnt : 32|4@1+ (1,0) [0|15] ""  TMU,VCU
 SG_ CF_Datc_AcnCompFlt : 36|1@1+ (1,0) [0|1] ""  CGW,H_U,TMU,VCU
 SG_ CF_Datc_PTCFlt : 37|1@1+ (1,0) [0|1] ""  CGW,H_U,TMU,VCU
 SG_ CF_Datc_WaterValve_Status : 38|1@1+ (1,0) [0|1] ""  MCU,TMU
 SG_ CF_Datc_CompType : 40|2@1+ (1,0) [0|3] ""  TMU,VCU
 SG_ CF_Datc_HvIntlockReq : 42|1@1+ (1,0) [0|1] ""  BMS,LDC,MCU,OBC,TMU
 SG_ CF_Datc_HeatPumpType : 43|1@1+ (1,0) [0|1] ""  TMU,VCU
 SG_ CF_Datc_PTCType : 44|2@1+ (1,0) [0|3] ""  TMU,VCU
 SG_ CF_Datc_HVCompInterlock : 46|1@1+ (1,0) [0|1] ""  MCU,TMU,VCU
 SG_ CF_Datc_HVPtcInterlock : 47|1@1+ (1,0) [0|1] ""  MCU,TMU,VCU
 SG_ CR_Datc_OutTempSnr_C : 48|8@1+ (0.5,-40) [-40|60] "¡É"  BMS,CGW,LDC,OBC,TMU,iBAU
 SG_ CF_Datc_ChkSum : 56|8@1+ (1,0) [0|255] ""  TMU,VCU

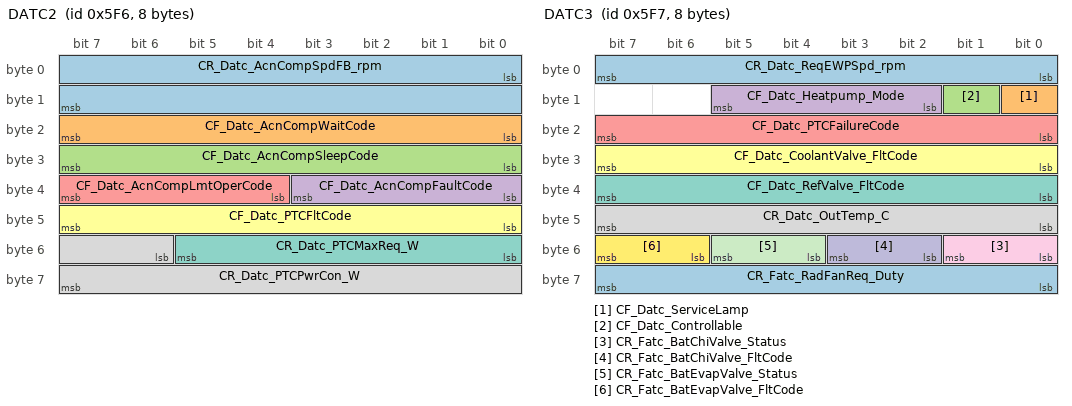
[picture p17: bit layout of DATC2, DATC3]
BO_ 1526 DATC2: 8 DATC
 SG_ CR_Datc_AcnCompSpdFB_rpm : 0|16@1+ (1,0) [0|65535] "rpm"  BMS,CGW,VCU,vBDM
 SG_ CF_Datc_AcnCompWaitCode : 16|8@1+ (1,0) [0|254] ""  VCU
 SG_ CF_Datc_AcnCompSleepCode : 24|8@1+ (1,0) [0|254] ""  VCU
 SG_ CF_Datc_AcnCompFaultCode : 32|4@1+ (1,0) [0|14] ""  VCU
 SG_ CF_Datc_AcnCompLmtOperCode : 36|4@1+ (1,0) [0|14] ""  VCU
 SG_ CF_Datc_PTCFltCode : 40|8@1+ (1,0) [0|254] ""  VCU
 SG_ CR_Datc_PTCMaxReq_W : 48|6@1+ (200,0) [0|10000] "W"  VCU
 SG_ CR_Datc_PTCPwrCon_W : 54|10@1+ (10,0) [0|10000] "W"  CGW,TMU,VCU

BO_ 1252 EWP2: 8 EWP2
 SG_ CF_Ewp_FltStatus : 0|1@1+ (1,0) [0|1] "flag"  BMS,MCU,VCU
 SG_ CF_Ewp_ProtectMode : 1|1@1+ (1,0) [0|1] "flag"  BMS
 SG_ CR_Ewp_ActRotSpd_rpm : 8|8@1+ (20,0) [0|5000] "rpm"  BMS,MCU,VCU
 SG_ CF_EWP_Version : 16|8@1+ (1,0) [0|255] ""  BMS,CGW,vBDM
 SG_ Eeprom_Pop_Up_Short : 24|1@1+ (1,0) [0|1] ""  BMS
 SG_ Eeprom_Pop_Up_Gduv : 25|1@1+ (1,0) [0|1] ""  BMS
 SG_ Eeprom_Pop_Up_Phase_Open : 26|1@1+ (1,0) [0|1] ""  BMS
 SG_ Eeprom_Pop_Up_Stalled : 27|1@1+ (1,0) [0|1] ""  BMS
 SG_ Eeprom_Pop_Up_Lc : 28|1@1+ (1,0) [0|1] ""  BMS
 SG_ Eeprom_Pop_Up_Oc : 29|1@1+ (1,0) [0|1] ""  BMS
 SG_ Eeprom_Pop_Up_Lv : 30|1@1+ (1,0) [0|1] ""  BMS
 SG_ Eeprom_Pop_Up_Hv : 31|1@1+ (1,0) [0|1] ""  BMS
 SG_ CF_PWM_Duty_Ratio : 32|8@1+ (1,0) [0|100] "%"  BMS
 SG_ CF_Current_RMS : 40|8@1+ (0.1,0) [0|25.5] "A"  BMS
 SG_ CF_Short_Ouput_Circuit : 48|1@1+ (1,0) [0|1] ""  BMS
 SG_ CF_Gduv : 49|1@1+ (1,0) [0|1] ""  BMS
 SG_ CF_Low_Current : 56|1@1+ (1,0) [0|1] ""  BMS
 SG_ CF_Over_Current : 57|1@1+ (1,0) [0|1] ""  BMS
 SG_ CF_Low_Voltage : 58|1@1+ (1,0) [0|1] ""  BMS
 SG_ CF_High_Voltage : 59|1@1+ (1,0) [0|1] ""  BMS
 SG_ CF_Speed_Error : 60|1@1+ (1,0) [0|1] "flag"  BMS

BO_ 1527 DATC3: 8 DATC
 SG_ CR_Datc_ReqEWPSpd_rpm : 0|8@1+ (30,0) [0|7620] "rpm"  EWP,MCU,TMU,VCU
 SG_ CF_Datc_ServiceLamp : 8|1@1+ (1,0) [0|1] ""  CGW,TMU
 SG_ CF_Datc_Controllable : 9|1@1+ (1,0) [0|1] ""  CGW,TMU,VCU
 SG_ CF_Datc_Heatpump_Mode : 10|4@1+ (1,0) [0|15] ""  AAF,TMU,VCU
 SG_ CF_Datc_PTCFailureCode : 16|8@1+ (1,0) [0|254] ""  TMU,VCU
 SG_ CF_Datc_CoolantValve_FltCode : 24|8@1+ (1,0) [0|254] ""  BMS,MCU,TMU,VCU
 SG_ CF_Datc_RefValve_FltCode : 32|8@1+ (1,0) [0|254] ""  TMU,VCU
 SG_ CR_Datc_OutTemp_C : 40|8@1+ (0.5,-40) [-40|60] "¡É"  AAF,CGW,EWP,MCU,TMU,VCU,iBAU,vBDM
 SG_ CR_Fatc_BatChiValve_Status : 48|2@1+ (1,0) [0|3] ""  BMS
 SG_ CR_Fatc_BatChiValve_FltCode : 50|2@1+ (1,0) [0|3] ""  BMS
 SG_ CR_Fatc_BatEvapValve_Status : 52|2@1+ (1,0) [0|3] ""  BMS
 SG_ CR_Fatc_BatEvapValve_FltCode : 54|2@1+ (1,0) [0|3] ""  BMS
 SG_ CR_Fatc_RadFanReq_Duty : 56|8@1+ (1,0) [0|100] "%"  MCU,TMU,VCU

CM_ BO_ 1301 "[E] On Event";
CM_ SG_ 1301 CF_Clu_TrfChgSet "When this signal change, the message (CLU4) is sent 3 times.";
CM_ SG_ 1301 CF_Clu_LkasModeNValueSet "Request to set LKAS control mode";
CM_ BO_ 1031 "[P] Periodic";
CM_ BO_ 1049 "[E] On Event";
CM_ BO_ 1048 "[E] On Event";
CM_ BO_ 1051 "[E] On Event";
CM_ BO_ 1289 "[E] On Event";
CM_ BO_ 1050 "[E] On Event";
CM_ BO_ 1294 "[PE] Periodic and On Event";
CM_ BO_ 1052 "[E] On Event";
CM_ BO_ 1293 "[PE] Periodic and On Event";
CM_ SG_ 1293 DATC_DiagMode "This signal is for ¡°Gateway¡± applied vehicles only.";
CM_ SG_ 1293 DATC_Rear_ChangeReqDisp "This signal is for ¡°Gateway¡± applied vehicles only.";
CM_ SG_ 1293 DATC_Rear_ClimateScnDisp "This signal is for ¡°Gateway¡± applied vehicles only.";
CM_ SG_ 1293 DATC_SelfDiagDisp "This signal is for ¡°Gateway¡± applied vehicles only.";
CM_ SG_ 1293 DATC_AqsLevelOut "This signal is for ¡°Gateway¡± applied vehicles only.";
CM_ BO_ 1280 "[P] Periodic";
CM_ BO_ 1042 "[PE] Periodic and On Event";
CM_ BO_ 1287 "[P] Periodic";
CM_ SG_ 1287 AVH_CLU "This message is for ¡°EPB (Electric Parking Brake)¡± system applied vehicle only.";
CM_ SG_ 1287 AVH_I_LAMP "This message is for ¡°EPB (Electric Parking Brake)¡± system applied vehicle only.";
CM_ SG_ 1287 AVH_ALARM "This message is for ¡°EPB (Electric Parking Brake)¡± system applied vehicle only.";
CM_ SG_ 1287 AVH_LAMP "This message is for ¡°EPB (Electric Parking Brake)¡± system applied vehicle only.";
CM_ BO_ 1044 "[PE] Periodic and On Event";
CM_ BO_ 852 "[P] Periodic";
CM_ SG_ 852 CF_But_CS "Checksum=10H-(Least significant nibbles of (Byte0 + Byte1 + Byte2 + Byte3+ Byte4 + Byte5 + Byte6 + Byte7) + Most significant nibbles of(Byte0 + Byte1 + Byte2 + Byte3 + Byte4 + Byte5 + Byte6))";
CM_ BO_ 1062 "[P] Periodic";
CM_ SG_ 1062 HU_VIN_Index "19.02.08_";
CM_ SG_ 1062 HU_VINStatus "19.02.08_";
CM_ SG_ 1062 HU_TeleOption "19.02.08_";
CM_ SG_ 1062 HU_VIN_56 "19.02.08_";
CM_ BO_ 1321 "[P] Periodic";
CM_ BO_ 1323 "[P] Periodic";
CM_ BO_ 1085 "[P] Periodic";
CM_ BO_ 1084 "[E] On Event";
CM_ BO_ 127 "[PE] Periodic and On Event";
CM_ BO_ 1312 "[P] Periodic";
CM_ SG_ 1312 CF_OBCWakeupDrLock "This signal is for OBC wake-up, When ICU Lock event";
CM_ SG_ 1312 CF_OBCWakeupDrUnlock "This signal is for OBC wake-up, When ICU Unlock event";
CM_ BO_ 1315 "[P] Periodic";
CM_ BO_ 1316 "[P] Periodic";
CM_ BO_ 1077 "[P] Periodic";
CM_ BO_ 1076 "[P] Periodic";
CM_ BO_ 1494 "[P] Periodic";
CM_ BO_ 1495 "[P] Periodic";
CM_ BO_ 1492 "[PE] Periodic and On Event";
CM_ BO_ 1493 "[P] Periodic";
CM_ BO_ 1491 "[PE] Periodic and On Event";
CM_ BO_ 1488 "[P] Periodic";
CM_ SG_ 1488 CF_Clu_Odometer "This signal is same as another one in CLU12 message on C-CAN. It means this signal is indirectly routed from C-CAN to P-CAN through Gateway unit.";
CM_ SG_ 1488 CF_LKA_Opt_USM "This message is for LDW/LKA system";
CM_ BO_ 1502 "[P] Periodic";
CM_ BO_ 1503 "[PE] Periodic and On Event";
CM_ SG_ 1503 HU_AliveStatus "Alive Status";
CM_ BO_ 1500 "[P] Periodic";
CM_ BO_ 674 "[P] Periodic";
CM_ BO_ 673 "[P] Periodic";
CM_ BO_ 1496 "[P] Periodic";
CM_ BO_ 1497 "[P] Periodic";
CM_ BO_ 1477 "[P] Periodic";
CM_ BO_ 1474 "[E] On Event";
CM_ BO_ 1245 "[P] Periodic";
CM_ BO_ 1246 "[P] Periodic";
CM_ BO_ 1484 "[PE] Periodic and On Event";
CM_ SG_ 1484 DATC_ModeDisp "This signal is for ¡°Gateway¡± applied vehicles only.";
CM_ SG_ 1484 DATC_TempUnit "This signal is for ¡°Gateway¡± applied vehicles only.";
CM_ SG_ 1484 DATC_SepzoneDisp "This signal is for ¡°Gateway¡± applied vehicles only.";
CM_ SG_ 1484 DATC_AutoDisp "This signal is for ¡°Gateway¡± applied vehicles only.";
CM_ SG_ 1484 DATC_IntakeDisp "This signal is for ¡°Gateway¡± applied vehicles only.";
CM_ SG_ 1484 DATC_ChangeReqDisp "This signal is for ¡°Gateway¡± applied vehicles only.";
CM_ SG_ 1484 DATC_AcDisp "This signal is for ¡°Gateway¡± applied vehicles only.";
CM_ SG_ 1484 DATC_AqsDisp "This signal is for ¡°Gateway¡± applied vehicles only.";
CM_ SG_ 1484 DATC_ClimateScnDisp "This signal is for ¡°Gateway¡± applied vehicles only.";
CM_ SG_ 1484 DATC_AirCleaningSystemStatus "Air Cleaning System Operate Status";
CM_ SG_ 1484 DATC_SyncDisp "This signal is for ¡°Gateway¡± applied vehicles only.";
CM_ SG_ 1484 DATC_OpSts "This signal is for ¡°Gateway¡± applied vehicles only.";
CM_ SG_ 1484 DATC_RearManual "This signal is for ¡°Gateway¡± applied vehicles only.";
CM_ SG_ 1484 DATC_HeatDisp "This signal is for ¡°Gateway¡± applied vehicles only.";
CM_ SG_ 1484 DATC_FrDefLed "This signal is for ¡°Gateway¡± applied vehicles only.";
CM_ SG_ 1484 DATC_AutoDefogBlink "This signal is for ¡°Gateway¡± applied vehicles only.";
CM_ SG_ 1484 CF_Datc_IntakeStatus "This signal is for ¡°IPM (Gateway)¡± applied vehicles only.";
CM_ SG_ 1484 DATC_IonClean "This signal is for ¡°Gateway¡± applied vehicles only.";
CM_ SG_ 1484 DATC_CO2Warning "This signal is for ¡°Gateway¡± applied vehicles only.";
CM_ SG_ 1484 DATC_SubBlowerDisp "This signal is for ¡°Gateway¡± applied vehicles only.";
CM_ SG_ 1484 DATC_BeepReq "This signal is for ¡°Gateway¡± applied vehicles only.";
CM_ SG_ 1484 DATC_MainBlowerDisp "This signal is for ¡°Gateway¡± applied vehicles only.";
CM_ SG_ 1484 DATC_PsModeDisp "This signal is for ¡°Gateway¡± applied vehicles only.";
CM_ BO_ 1483 "[PE] Periodic and On Event";
CM_ SG_ 1483 CR_Datc_DrTempDispC "This signal is for ¡°Gateway¡± applied vehicles only.";
CM_ SG_ 1483 CR_Datc_DrTempDispF "This signal is for ¡°Gateway¡± applied vehicles only.";
CM_ SG_ 1483 CR_Datc_PsTempDispC "This signal is for ¡°Gateway¡± applied vehicles only.";
CM_ SG_ 1483 CR_Datc_PsTempDispF "This signal is for ¡°Gateway¡± applied vehicles only.";
CM_ SG_ 1483 CF_DATC_TempDisp_Sts "This signal is for ¡°IPM (Gateway)¡± applied vehicles only.";
CM_ SG_ 1483 CR_Datc_RearDrTempDispC "This signal is for ¡°Gateway¡± applied vehicles only.";
CM_ SG_ 1483 CR_Datc_RearDrTempDispF "This signal is for ¡°Gateway¡± applied vehicles only.";
CM_ BO_ 1482 "[PE] Periodic and On Event";
CM_ SG_ 1482 CR_Datc_OutTempC "This signal is for ¡°Gateway¡± applied vehicles only.";
CM_ SG_ 1482 CR_Datc_OutTempF "This signal is for ¡°Gateway¡± applied vehicles only.";
CM_ BO_ 1481 "[P] Periodic";
CM_ BO_ 1525 "[P] Periodic";
CM_ BO_ 1526 "[P] Periodic";
CM_ BO_ 1252 "[P] Periodic";
CM_ BO_ 1527 "[P] Periodic";
BA_DEF_ SG_  "GenSigEnvVarType" ENUM  "Int","Float","Undef";
BA_DEF_ SG_  "GenSigEVName" STRING ;
BA_DEF_ SG_  "GenSigInactiveValue" INT 0 65535;
BA_DEF_ SG_  "GenSigSendType" ENUM  "Cyclic","OnWrite","OnWriteWithRepetition","OnChange","OnChangeWithRepetition","IfActive","IfActiveWithRepetition","NoSigSendType";
BA_DEF_ SG_  "GenSigStartValue" INT 0 1215752192;
BA_DEF_ SG_  "GwSigLatencyTime" INT 0 65535;
BA_DEF_ SG_  "GwSigMissingSourceType" ENUM  "Undef","OldValue","DefaultValue","InitialValue";
BA_DEF_ SG_  "SignalCategory" HEX 10 15;
BA_DEF_ BO_  "GenMsgCycleTime" INT 0 2000;
BA_DEF_ BO_  "GenMsgCycleTimeFast" INT 0 500;
BA_DEF_ BO_  "GenMsgDelayTime" INT 0 20;
BA_DEF_ BO_  "GenMsgILSupport" ENUM  "No","Yes";
BA_DEF_ BO_  "GenMsgNrOfRepetition" INT 0 3;
BA_DEF_ BO_  "GenMsgSendType" ENUM  "Cyclic","not_used","not_used","not_used","not_used","not_used","not_used","not_used","NoMsgSendType";
BA_DEF_ BO_  "GenMsgStartDelayTime" INT 0 2000;
BA_DEF_REL_ BU_SG_REL_  "GenSigTimeoutTime" INT 0 7000;
BA_DEF_DEF_  "GenSigEnvVarType" "Undef";
BA_DEF_DEF_  "GenSigEVName" "@Signame";
BA_DEF_DEF_  "GenSigInactiveValue" 0;
BA_DEF_DEF_  "GenSigSendType" "NoSigSendType";
BA_DEF_DEF_  "GenSigStartValue" 0;
BA_DEF_DEF_  "GwSigLatencyTime" 40;
BA_DEF_DEF_  "GwSigMissingSourceType" "Undef";
BA_DEF_DEF_  "SignalCategory" 12;
BA_DEF_DEF_  "GenMsgCycleTime" 10;
BA_DEF_DEF_  "GenMsgCycleTimeFast" 40;
BA_DEF_DEF_  "GenMsgDelayTime" 20;
BA_DEF_DEF_  "GenMsgILSupport" "Yes";
BA_DEF_DEF_  "GenMsgNrOfRepetition" 0;
BA_DEF_DEF_  "GenMsgSendType" "Cyclic";
BA_DEF_DEF_  "GenMsgStartDelayTime" 0;
BA_DEF_DEF_REL_ "GenSigTimeoutTime" 500;
BA_ "GenMsgNrOfRepetition" BO_ 1301 3;
BA_ "GenMsgCycleTime" BO_ 1301 0;
BA_ "GenMsgSendType" BO_ 1301 8;
BA_ "GenMsgCycleTime" BO_ 1031 200;
BA_ "GenMsgNrOfRepetition" BO_ 1049 3;
BA_ "GenMsgCycleTime" BO_ 1049 0;
BA_ "GenMsgSendType" BO_ 1049 8;
BA_ "GenMsgNrOfRepetition" BO_ 1048 3;
BA_ "GenMsgCycleTime" BO_ 1048 0;
BA_ "GenMsgSendType" BO_ 1048 8;
BA_ "GenMsgNrOfRepetition" BO_ 1051 3;
BA_ "GenMsgCycleTime" BO_ 1051 0;
BA_ "GenMsgSendType" BO_ 1051 8;
BA_ "GenMsgNrOfRepetition" BO_ 1289 3;
BA_ "GenMsgCycleTime" BO_ 1289 0;
BA_ "GenMsgSendType" BO_ 1289 8;
BA_ "GenMsgNrOfRepetition" BO_ 1050 3;
BA_ "GenMsgCycleTime" BO_ 1050 0;
BA_ "GenMsgSendType" BO_ 1050 8;
BA_ "GenMsgNrOfRepetition" BO_ 1294 3;
BA_ "GenMsgCycleTime" BO_ 1294 200;
BA_ "GenMsgNrOfRepetition" BO_ 1052 3;
BA_ "GenMsgCycleTime" BO_ 1052 0;
BA_ "GenMsgSendType" BO_ 1052 8;
BA_ "GenMsgNrOfRepetition" BO_ 1293 3;
BA_ "GenMsgCycleTime" BO_ 1293 200;
BA_ "GenMsgCycleTime" BO_ 1280 100;
BA_ "GenMsgNrOfRepetition" BO_ 1042 3;
BA_ "GenMsgCycleTime" BO_ 1042 200;
BA_ "GenMsgCycleTime" BO_ 1287 100;
BA_ "GenMsgCycleTime" BO_ 1044 200;
BA_ "GenMsgCycleTime" BO_ 1062 1000;
BA_ "GenMsgCycleTime" BO_ 1321 200;
BA_ "GenMsgCycleTime" BO_ 1323 100;
BA_ "GenMsgCycleTime" BO_ 1085 200;
BA_ "GenMsgNrOfRepetition" BO_ 1084 3;
BA_ "GenMsgCycleTime" BO_ 1084 0;
BA_ "GenMsgSendType" BO_ 1084 8;
BA_ "GenMsgNrOfRepetition" BO_ 127 3;
BA_ "GenMsgCycleTime" BO_ 127 1000;
BA_ "GenMsgCycleTime" BO_ 1312 100;
BA_ "GenMsgCycleTime" BO_ 1077 1000;
BA_ "GenMsgCycleTime" BO_ 1076 1000;
BA_ "GenMsgCycleTime" BO_ 1494 100;
BA_ "GenMsgCycleTime" BO_ 1495 100;
BA_ "GenMsgNrOfRepetition" BO_ 1492 3;
BA_ "GenMsgCycleTime" BO_ 1492 1000;
BA_ "GenMsgCycleTime" BO_ 1493 100;
BA_ "GenMsgNrOfRepetition" BO_ 1491 3;
BA_ "GenMsgCycleTime" BO_ 1491 1000;
BA_ "GenMsgCycleTime" BO_ 1488 1000;
BA_ "GenMsgCycleTime" BO_ 1502 1000;
BA_ "GenMsgNrOfRepetition" BO_ 1503 3;
BA_ "GenMsgCycleTime" BO_ 1503 200;
BA_ "GenMsgCycleTime" BO_ 1500 1000;
BA_ "GenMsgCycleTime" BO_ 673 100;
BA_ "GenMsgCycleTime" BO_ 1496 100;
BA_ "GenMsgCycleTime" BO_ 1497 100;
BA_ "GenMsgCycleTime" BO_ 1477 100;
BA_ "GenMsgNrOfRepetition" BO_ 1474 3;
BA_ "GenMsgCycleTime" BO_ 1474 0;
BA_ "GenMsgSendType" BO_ 1474 8;
BA_ "GenMsgCycleTime" BO_ 1245 100;
BA_ "GenMsgCycleTime" BO_ 1246 100;
BA_ "GenMsgNrOfRepetition" BO_ 1484 3;
BA_ "GenMsgCycleTime" BO_ 1484 1000;
BA_ "GenMsgNrOfRepetition" BO_ 1483 3;
BA_ "GenMsgCycleTime" BO_ 1483 1000;
BA_ "GenMsgNrOfRepetition" BO_ 1482 3;
BA_ "GenMsgCycleTime" BO_ 1482 1000;
BA_ "GenMsgCycleTime" BO_ 1481 100;
BA_ "GenMsgCycleTime" BO_ 1525 100;
BA_ "GenMsgCycleTime" BO_ 1526 100;
BA_ "GenMsgCycleTime" BO_ 1252 100;
BA_ "GenMsgCycleTime" BO_ 1527 100;
BA_ "GenSigSendType" SG_ 1301 CF_Clu_ADrUNValueSet 4;
BA_ "GenSigSendType" SG_ 1301 CF_Clu_ADrLNValueSet 4;
BA_ "GenSigSendType" SG_ 1301 CF_Clu_EscortHLNValueSet 4;
BA_ "GenSigSendType" SG_ 1301 CF_Clu_DoorLSNValueSet 4;
BA_ "GenSigSendType" SG_ 1301 CF_Clu_PSMNValueSet 4;
BA_ "GenSigSendType" SG_ 1301 CF_Clu_TTUnlockNValueSet 4;
BA_ "GenSigSendType" SG_ 1301 CF_Clu_ATTurnNValueSet 4;
BA_ "GenSigSendType" SG_ 1301 CF_Clu_SCMNValueSet 4;
BA_ "GenSigSendType" SG_ 1301 CF_Clu_WlightNValueSet 4;
BA_ "GenSigSendType" SG_ 1301 CF_Clu_TempUnitNValueSet 4;
BA_ "GenSigSendType" SG_ 1301 CF_Clu_TrfChgSet 4;
BA_ "GenSigSendType" SG_ 1301 CF_Clu_OTTurnNValueSet 4;
BA_ "GenSigSendType" SG_ 1301 CF_Clu_LcaNValueSet 4;
BA_ "GenSigSendType" SG_ 1301 CF_Clu_RctaNValueSet 4;
BA_ "GenSigSendType" SG_ 1301 CF_Clu_RcwNValueSet 4;
BA_ "GenSigSendType" SG_ 1301 CF_Clu_EcsOffNValueSet 4;
BA_ "GenSigSendType" SG_ 1301 CF_Clu_SccNaviCrvNValueSet 4;
BA_ "GenSigSendType" SG_ 1301 CF_Clu_SccNaviCamNValueSet 4;
BA_ "GenSigSendType" SG_ 1301 CF_Clu_SccAebNValueSet 4;
BA_ "GenSigSendType" SG_ 1301 CF_Clu_LkasModeNValueSet 4;
BA_ "GenSigSendType" SG_ 1301 CF_Clu_FcwNValueSet 4;
BA_ "GenSigSendType" SG_ 1301 CF_Clu_PasSpkrLvNValueSet 4;
BA_ "GenSigSendType" SG_ 1301 CF_Clu_SccDrvModeNValueSet 4;
BA_ "GenSigSendType" SG_ 1301 CF_Clu_HAnBNValueSet 4;
BA_ "GenSigSendType" SG_ 1301 CF_Clu_HfreeTrunkTgNValueSet 4;
BA_ "GenSigSendType" SG_ 1049 PROLONG_Update 4;
BA_ "GenSigSendType" SG_ 1049 PROLONG_Retransmission 4;
BA_ "GenSigSendType" SG_ 1049 PROLONG_CountrolPoint 4;
BA_ "GenSigSendType" SG_ 1049 PROLONG_ProfileType 4;
BA_ "GenSigSendType" SG_ 1049 PROLONG_PathIndex 4;
BA_ "GenSigSendType" SG_ 1049 PROLONG_CyclicCounter 4;
BA_ "GenSigStartValue" SG_ 1049 PROLONG_Offset 8191;
BA_ "GenSigSendType" SG_ 1049 PROLONG_Offset 4;
BA_ "GenSigStartValue" SG_ 1049 PROLONG_MessageType 7;
BA_ "GenSigSendType" SG_ 1049 PROLONG_MessageType 4;
BA_ "GenSigSendType" SG_ 1049 PROLONG_Value 4;
BA_ "GenSigSendType" SG_ 1048 META_MinorProtocolVersion 4;
BA_ "GenSigSendType" SG_ 1048 META_SpeedUnit 4;
BA_ "GenSigStartValue" SG_ 1048 META_MapVersionYear 63;
BA_ "GenSigSendType" SG_ 1048 META_MapVersionYear 4;
BA_ "GenSigSendType" SG_ 1048 META_MapVersionQuarter 4;
BA_ "GenSigStartValue" SG_ 1048 META_RegionCode 2047;
BA_ "GenSigSendType" SG_ 1048 META_RegionCode 4;
BA_ "GenSigSendType" SG_ 1048 META_DrivingSide 4;
BA_ "GenSigStartValue" SG_ 1048 META_HardwareVersion 511;
BA_ "GenSigSendType" SG_ 1048 META_HardwareVersion 4;
BA_ "GenSigSendType" SG_ 1048 META_MinorProtocolSubVer 4;
BA_ "GenSigSendType" SG_ 1048 META_MajorProtocolVersion 4;
BA_ "GenSigSendType" SG_ 1048 META_CyclicCounter 4;
BA_ "GenSigStartValue" SG_ 1048 META_CountryCode 1023;
BA_ "GenSigSendType" SG_ 1048 META_CountryCode 4;
BA_ "GenSigStartValue" SG_ 1048 META_MapProvider 7;
BA_ "GenSigSendType" SG_ 1048 META_MapProvider 4;
BA_ "GenSigStartValue" SG_ 1048 META_MessageType 7;
BA_ "GenSigSendType" SG_ 1048 META_MessageType 4;
BA_ "GenSigStartValue" SG_ 1051 SEG_DirectionLanes 7;
BA_ "GenSigSendType" SG_ 1051 SEG_DirectionLanes 4;
BA_ "GenSigStartValue" SG_ 1051 SEG_OppositeLanes 3;
BA_ "GenSigSendType" SG_ 1051 SEG_OppositeLanes 4;
BA_ "GenSigStartValue" SG_ 1051 SEG_DividedRoad 3;
BA_ "GenSigSendType" SG_ 1051 SEG_DividedRoad 4;
BA_ "GenSigStartValue" SG_ 1051 SEG_SpeedLimitType 7;
BA_ "GenSigSendType" SG_ 1051 SEG_SpeedLimitType 4;
BA_ "GenSigStartValue" SG_ 1051 SEG_SpeedLimit 31;
BA_ "GenSigSendType" SG_ 1051 SEG_SpeedLimit 4;
BA_ "GenSigStartValue" SG_ 1051 SEG_FormOfWay 15;
BA_ "GenSigSendType" SG_ 1051 SEG_FormOfWay 4;
BA_ "GenSigStartValue" SG_ 1051 SEG_ComplexIntersection 3;
BA_ "GenSigSendType" SG_ 1051 SEG_ComplexIntersection 4;
BA_ "GenSigStartValue" SG_ 1051 SEG_CalculatedRoute 3;
BA_ "GenSigSendType" SG_ 1051 SEG_CalculatedRoute 4;
BA_ "GenSigStartValue" SG_ 1051 SEG_FunctionalRoadClass 7;
BA_ "GenSigSendType" SG_ 1051 SEG_FunctionalRoadClass 4;
BA_ "GenSigStartValue" SG_ 1051 SEG_RelativeProbability 31;
BA_ "GenSigSendType" SG_ 1051 SEG_RelativeProbability 4;
BA_ "GenSigSendType" SG_ 1051 SEG_Update 4;
BA_ "GenSigSendType" SG_ 1051 SEG_Retransmission 4;
BA_ "GenSigSendType" SG_ 1051 SEG_BuiltUpArea 4;
BA_ "GenSigStartValue" SG_ 1051 SEG_Bridge 3;
BA_ "GenSigSendType" SG_ 1051 SEG_Bridge 4;
BA_ "GenSigStartValue" SG_ 1051 SEG_Tunnel 3;
BA_ "GenSigSendType" SG_ 1051 SEG_Tunnel 4;
BA_ "GenSigSendType" SG_ 1051 SEG_PathIndex 4;
BA_ "GenSigSendType" SG_ 1051 SEG_CyclicCounter 4;
BA_ "GenSigStartValue" SG_ 1051 SEG_Offset 8191;
BA_ "GenSigSendType" SG_ 1051 SEG_Offset 4;
BA_ "GenSigStartValue" SG_ 1051 SEG_MessageType 7;
BA_ "GenSigSendType" SG_ 1051 SEG_MessageType 4;
BA_ "GenSigStartValue" SG_ 1289 HU_DATC_PasModeSet 15;
BA_ "GenSigSendType" SG_ 1289 HU_DATC_PasModeSet 4;
BA_ "GenSigSendType" SG_ 1289 HU_DATC_WshFldUSMSet 4;
BA_ "GenSigStartValue" SG_ 1289 HU_DATC_DrvOnlySet 3;
BA_ "GenSigSendType" SG_ 1289 HU_DATC_DrvOnlySet 4;
BA_ "GenSigStartValue" SG_ 1289 HU_DATC_HeatSet 3;
BA_ "GenSigSendType" SG_ 1289 HU_DATC_HeatSet 4;
BA_ "GenSigSendType" SG_ 1050 PROSHORT_Update 4;
BA_ "GenSigSendType" SG_ 1050 PROSHORT_Retransmission 4;
BA_ "GenSigSendType" SG_ 1050 PROSHORT_ControlPoint 4;
BA_ "GenSigSendType" SG_ 1050 PROSHORT_ProfileType 4;
BA_ "GenSigSendType" SG_ 1050 PROSHORT_Value1 4;
BA_ "GenSigStartValue" SG_ 1050 PROSHORT_Value0 1023;
BA_ "GenSigSendType" SG_ 1050 PROSHORT_Value0 4;
BA_ "GenSigStartValue" SG_ 1050 PROSHORT_Distance 1023;
BA_ "GenSigSendType" SG_ 1050 PROSHORT_Distance 4;
BA_ "GenSigStartValue" SG_ 1050 PROSHORT_Accuracy 3;
BA_ "GenSigSendType" SG_ 1050 PROSHORT_Accuracy 4;
BA_ "GenSigSendType" SG_ 1050 PROSHORT_PathIndex 4;
BA_ "GenSigSendType" SG_ 1050 PROSHORT_CyclicCounter 4;
BA_ "GenSigStartValue" SG_ 1050 PROSHORT_Offset 8191;
BA_ "GenSigSendType" SG_ 1050 PROSHORT_Offset 4;
BA_ "GenSigStartValue" SG_ 1050 PROSHORT_MessageType 7;
BA_ "GenSigSendType" SG_ 1050 PROSHORT_MessageType 4;
BA_ "GenSigSendType" SG_ 1294 CF_Gway_WasherFluidSw 4;
BA_ "GenSigSendType" SG_ 1294 CR_Datc_DRSeatWheel_USM_Set 4;
BA_ "GenSigSendType" SG_ 1294 DATC_TunnelIND 4;
BA_ "GenSigSendType" SG_ 1294 DATC_TunnelState 4;
BA_ "GenSigSendType" SG_ 1294 C_MFSW_WasherSw 4;
BA_ "GenSigSendType" SG_ 1294 C_IBU_WasherSw 4;
BA_ "GenSigStartValue" SG_ 1052 STUB_DirectionLanes 7;
BA_ "GenSigSendType" SG_ 1052 STUB_DirectionLanes 4;
BA_ "GenSigStartValue" SG_ 1052 STUB_OppositeLanes 3;
BA_ "GenSigSendType" SG_ 1052 STUB_OppositeLanes 4;
BA_ "GenSigStartValue" SG_ 1052 STUB_RightOfWay 3;
BA_ "GenSigSendType" SG_ 1052 STUB_RightOfWay 4;
BA_ "GenSigSendType" SG_ 1052 STUB_LastStubAtOffset 4;
BA_ "GenSigStartValue" SG_ 1052 STUB_TurnAngle 255;
BA_ "GenSigSendType" SG_ 1052 STUB_TurnAngle 4;
BA_ "GenSigStartValue" SG_ 1052 STUB_FormOfWay 15;
BA_ "GenSigSendType" SG_ 1052 STUB_FormOfWay 4;
BA_ "GenSigStartValue" SG_ 1052 STUB_ComplexIntersection 3;
BA_ "GenSigSendType" SG_ 1052 STUB_ComplexIntersection 4;
BA_ "GenSigStartValue" SG_ 1052 STUB_CalculatedRoute 3;
BA_ "GenSigSendType" SG_ 1052 STUB_CalculatedRoute 4;
BA_ "GenSigStartValue" SG_ 1052 STUB_FunctionalRoadClass 7;
BA_ "GenSigSendType" SG_ 1052 STUB_FunctionalRoadClass 4;
BA_ "GenSigStartValue" SG_ 1052 STUB_RelativeProbability 31;
BA_ "GenSigSendType" SG_ 1052 STUB_RelativeProbability 4;
BA_ "GenSigSendType" SG_ 1052 STUB_Update 4;
BA_ "GenSigSendType" SG_ 1052 STUB_Retransmission 4;
BA_ "GenSigSendType" SG_ 1052 STUB_SubPathIndex 4;
BA_ "GenSigSendType" SG_ 1052 STUB_PathIndex 4;
BA_ "GenSigSendType" SG_ 1052 STUB_CyclicCounter 4;
BA_ "GenSigStartValue" SG_ 1052 STUB_Offset 8191;
BA_ "GenSigSendType" SG_ 1052 STUB_Offset 4;
BA_ "GenSigStartValue" SG_ 1052 STUB_MessageType 7;
BA_ "GenSigSendType" SG_ 1052 STUB_MessageType 4;
BA_ "GenSigSendType" SG_ 1293 DATC_DiagMode 4;
BA_ "GenSigSendType" SG_ 1293 DATC_Rear_ChangeReqDisp 4;
BA_ "GenSigSendType" SG_ 1293 DATC_Rear_ClimateScnDisp 4;
BA_ "GenSigStartValue" SG_ 1293 DATC_AutoArClnSysSta 3;
BA_ "GenSigSendType" SG_ 1293 DATC_AutoArClnSysSta 4;
BA_ "GenSigSendType" SG_ 1293 DATC_SelfDiagDisp 4;
BA_ "GenSigSendType" SG_ 1293 DATC_AqsLevelOut 4;
BA_ "GenSigSendType" SG_ 1293 CR_Fatc_PreConSwi 4;
BA_ "GenSigStartValue" SG_ 1293 DATC_EV_ScnDisp 3;
BA_ "GenSigSendType" SG_ 1293 DATC_EV_ScnDisp 4;
BA_ "GenSigStartValue" SG_ 1293 DATC_AutoDefogSysOff_Disp 3;
BA_ "GenSigSendType" SG_ 1293 DATC_AutoDefogSysOff_Disp 4;
BA_ "GenSigSendType" SG_ 1293 DATC_WshFldUSMState 4;
BA_ "GenSigSendType" SG_ 1293 CR_Datc_ClimatePowSum_W 4;
BA_ "GenSigSendType" SG_ 1293 CR_Datc_BatteryPowSum_Wh 4;
BA_ "GenSigSendType" SG_ 1042 CF_Gway_DigitalKeyOption 4;
BA_ "GenSigSendType" SG_ 1042 CF_Gway_ProfileIDRValue 4;
BA_ "GenSigStartValue" SG_ 1042 CF_Datc_DefLogic_USM_Set 3;
BA_ "GenSigSendType" SG_ 1042 CF_Datc_DefLogic_USM_Set 4;
BA_ "GenSigStartValue" SG_ 1042 CF_Datc_AutoFresh_USM_Set 3;
BA_ "GenSigSendType" SG_ 1042 CF_Datc_AutoFresh_USM_Set 4;
BA_ "GenSigSendType" SG_ 1044 CF_TMU_ICCB_InCurModeState 3;
BA_ "GenSigSendType" SG_ 1044 CF_TMU_EVSE_InCurModeState 3;
BA_ "GenSigStartValue" SG_ 852 CF_Lvr_PButtonStatus_Reversed 3;
BA_ "GenSigStartValue" SG_ 852 CF_Lvr_RButtonStatus_Reversed 3;
BA_ "GenSigStartValue" SG_ 852 CF_Lvr_NButtonStatus_Reversed 3;
BA_ "GenSigStartValue" SG_ 852 CF_Lvr_DButtonStatus_Reversed 3;
BA_ "GenSigStartValue" SG_ 852 CF_Lvr_UnLkButStatus_Reversed 3;
BA_ "GenSigStartValue" SG_ 852 CF_Lvr_PRelButStatus_Reversed 3;
BA_ "GenSigStartValue" SG_ 1062 HU_VIN_Index 7;
BA_ "GenSigStartValue" SG_ 1062 HU_VINStatus 3;
BA_ "GenSigStartValue" SG_ 1062 HU_TeleOption 3;
BA_ "GenSigSendType" SG_ 1084 CF_Clu_SchedChargNValueSet 4;
BA_ "GenSigSendType" SG_ 1084 CF_Clu_SchedClmtNValueSet 4;
BA_ "GenSigSendType" SG_ 1084 CF_Clu_SchedClmtDfrNValueSet 4;
BA_ "GenSigStartValue" SG_ 1084 CF_Clu_BatteryHeatNValueSet 3;
BA_ "GenSigSendType" SG_ 1084 CF_Clu_BatteryHeatNValueSet 3;
BA_ "GenSigSendType" SG_ 1084 CF_Clu_DepartSunNValueSet 4;
BA_ "GenSigSendType" SG_ 1084 CF_Clu_DepartMonNValueSet 4;
BA_ "GenSigSendType" SG_ 1084 CF_Clu_SchedClmtTempNValueSet 4;
BA_ "GenSigSendType" SG_ 1084 CF_Clu_DepartTueNValueSet 4;
BA_ "GenSigSendType" SG_ 1084 CF_Clu_DepartWedNValueSet 4;
BA_ "GenSigSendType" SG_ 1084 CF_Clu_DepartThuNValueSet 4;
BA_ "GenSigSendType" SG_ 1084 CF_Clu_DepartFriNValueSet 4;
BA_ "GenSigSendType" SG_ 1084 CF_Clu_DepartSatNValueSet 4;
BA_ "GenSigSendType" SG_ 1084 CF_Clu_DepartHourNValueSet 4;
BA_ "GenSigSendType" SG_ 1084 CF_Clu_DepartMinNValueSet 4;
BA_ "GenSigSendType" SG_ 1084 CF_Clu_EVSE_InCurNValueSet 3;
BA_ "GenSigSendType" SG_ 1084 CF_Clu_ICCB_InCurNValueSet 3;
BA_ "GenSigStartValue" SG_ 1084 CF_Clu_EcoRegenLvNValueSet 3;
BA_ "GenSigSendType" SG_ 1084 CF_Clu_EcoRegenLvNValueSet 4;
BA_ "GenSigStartValue" SG_ 1084 CF_Clu_NormalRegenLvNValueSet 3;
BA_ "GenSigSendType" SG_ 1084 CF_Clu_NormalRegenLvNValueSet 4;
BA_ "GenSigSendType" SG_ 1084 CF_Clu_EconSTHourNValueSet 4;
BA_ "GenSigSendType" SG_ 1084 CF_Clu_EconENDHourNValueSet 4;
BA_ "GenSigSendType" SG_ 127 C_StopLampLhOpenSts 4;
BA_ "GenSigSendType" SG_ 127 C_StopLampRhOpenSts 4;
BA_ "GenSigSendType" SG_ 127 C_HLampLowLhOpenSts 4;
BA_ "GenSigSendType" SG_ 127 C_HLampLowRhOpenSts 4;
BA_ "GenSigSendType" SG_ 127 C_HLampHighLhOpenSts 4;
BA_ "GenSigSendType" SG_ 127 C_HLampHighRhOpenSts 4;
BA_ "GenSigSendType" SG_ 127 C_RearTSIGLhOpenSts 4;
BA_ "GenSigSendType" SG_ 127 C_RearTSIGRhOpenSts 4;
BA_ "GenSigSendType" SG_ 127 C_FrontTSIGLhOpenSts 4;
BA_ "GenSigSendType" SG_ 127 C_FrontTSIGRhOpenSts 4;
BA_ "GenSigSendType" SG_ 127 C_HLampBifuncLhOpenSts 4;
BA_ "GenSigSendType" SG_ 127 C_HLampBifuncRhOpenSts 4;
BA_ "GenSigSendType" SG_ 127 C_MoodLp 4;
BA_ "GenSigSendType" SG_ 127 CF_Gway_MoodLpColorRValue 4;
BA_ "GenSigSendType" SG_ 127 CF_Gway_MoodLpBrightRValue 4;
BA_ "GenSigStartValue" SG_ 1076 DATC_MnlBlwSta 15;
BA_ "GenSigStartValue" SG_ 1076 DATC_MnlModSta 15;
BA_ "GenSigStartValue" SG_ 1076 DATC_MnlACSta 3;
BA_ "GenSigStartValue" SG_ 1076 DATC_MnlIntakeSta 3;
BA_ "GenSigStartValue" SG_ 1076 DATC_MnlRrBlwrSta 15;
BA_ "GenSigStartValue" SG_ 1076 DATC_MnlRrModSta 15;
BA_ "GenSigStartValue" SG_ 1076 DATC_MnlRrACSta 3;
BA_ "GenSigStartValue" SG_ 1076 DATC_StrWhlHtrSta 15;
BA_ "GenSigStartValue" SG_ 1076 DATC_DrvStHtrVntSta 15;
BA_ "GenSigStartValue" SG_ 1076 DATC_PassStHtrVntSta 15;
BA_ "GenSigStartValue" SG_ 1494 CR_Bms_BatMinCel_V 3;
BA_ "GenSigStartValue" SG_ 1494 CR_Bms_BatMaxCel_V 3;
BA_ "GenSigStartValue" SG_ 1492 IBOX_IVRActivity 3;
BA_ "GenSigSendType" SG_ 1492 IBOX_IVRActivity 4;
BA_ "GenSigStartValue" SG_ 1492 IBOX_PhoneActivity 3;
BA_ "GenSigSendType" SG_ 1492 IBOX_PhoneActivity 4;
BA_ "GenSigStartValue" SG_ 1491 HU_VRActivity 3;
BA_ "GenSigSendType" SG_ 1491 HU_VRActivity 4;
BA_ "GenSigStartValue" SG_ 1491 HU_PhoneActivity 3;
BA_ "GenSigSendType" SG_ 1491 HU_PhoneActivity 4;
BA_ "GenSigStartValue" SG_ 1491 HU_DATC_AirQuality_Info 15;
BA_ "GenSigSendType" SG_ 1491 HU_DATC_AirQuality_Info 4;
BA_ "GenSigStartValue" SG_ 1503 HU_AliveStatus 3;
BA_ "GenSigSendType" SG_ 1503 HU_AliveStatus 4;
BA_ "GenSigStartValue" SG_ 1503 HU_NaviStatus 3;
BA_ "GenSigSendType" SG_ 1503 HU_NaviStatus 4;
BA_ "GenSigStartValue" SG_ 1503 HU_Navigation_On_Off 3;
BA_ "GenSigSendType" SG_ 1503 HU_Navigation_On_Off 4;
BA_ "GenSigStartValue" SG_ 1503 HU_Type 255;
BA_ "GenSigSendType" SG_ 1503 HU_Type 4;
BA_ "GenSigStartValue" SG_ 1503 HU_DistributeInfo 255;
BA_ "GenSigSendType" SG_ 1503 HU_DistributeInfo 4;
BA_ "GenSigStartValue" SG_ 1503 HU_AdasSupport 7;
BA_ "GenSigSendType" SG_ 1503 HU_AdasSupport 4;
BA_ "GenSigSendType" SG_ 1474 CF_Clu_InletAutoLockNValueSet 4;
BA_ "GenSigStartValue" SG_ 1484 DATC_ModeDisp 15;
BA_ "GenSigSendType" SG_ 1484 DATC_ModeDisp 4;
BA_ "GenSigStartValue" SG_ 1484 DATC_TempUnit 3;
BA_ "GenSigSendType" SG_ 1484 DATC_TempUnit 4;
BA_ "GenSigStartValue" SG_ 1484 DATC_SepzoneDisp 3;
BA_ "GenSigSendType" SG_ 1484 DATC_SepzoneDisp 4;
BA_ "GenSigStartValue" SG_ 1484 DATC_AutoDisp 3;
BA_ "GenSigSendType" SG_ 1484 DATC_AutoDisp 4;
BA_ "GenSigStartValue" SG_ 1484 DATC_IntakeDisp 3;
BA_ "GenSigSendType" SG_ 1484 DATC_IntakeDisp 4;
BA_ "GenSigStartValue" SG_ 1484 DATC_ChangeReqDisp 3;
BA_ "GenSigSendType" SG_ 1484 DATC_ChangeReqDisp 4;
BA_ "GenSigSendType" SG_ 1484 CF_Datc_Text_PopupReq 4;
BA_ "GenSigStartValue" SG_ 1484 DATC_AcDisp 3;
BA_ "GenSigSendType" SG_ 1484 DATC_AcDisp 4;
BA_ "GenSigStartValue" SG_ 1484 DATC_AqsDisp 3;
BA_ "GenSigSendType" SG_ 1484 DATC_AqsDisp 4;
BA_ "GenSigStartValue" SG_ 1484 DATC_ClimateScnDisp 3;
BA_ "GenSigSendType" SG_ 1484 DATC_ClimateScnDisp 4;
BA_ "GenSigStartValue" SG_ 1484 DATC_AirCleaningSystemStatus 3;
BA_ "GenSigSendType" SG_ 1484 DATC_AirCleaningSystemStatus 4;
BA_ "GenSigStartValue" SG_ 1484 DATC_SyncDisp 3;
BA_ "GenSigSendType" SG_ 1484 DATC_SyncDisp 4;
BA_ "GenSigSendType" SG_ 1484 CF_Datc_BlowerAutoDisp 4;
BA_ "GenSigStartValue" SG_ 1484 DATC_OpSts 7;
BA_ "GenSigSendType" SG_ 1484 DATC_OpSts 4;
BA_ "GenSigStartValue" SG_ 1484 DATC_RearManual 3;
BA_ "GenSigSendType" SG_ 1484 DATC_RearManual 4;
BA_ "GenSigStartValue" SG_ 1484 DATC_HeatDisp 3;
BA_ "GenSigSendType" SG_ 1484 DATC_HeatDisp 4;
BA_ "GenSigStartValue" SG_ 1484 DATC_FrDefLed 3;
BA_ "GenSigSendType" SG_ 1484 DATC_FrDefLed 4;
BA_ "GenSigSendType" SG_ 1484 CF_Datc_ModAutoDisp 4;
BA_ "GenSigSendType" SG_ 1484 DATC_AutoDefogBlink 4;
BA_ "GenSigSendType" SG_ 1484 CF_Datc_IntakeStatus 4;
BA_ "GenSigStartValue" SG_ 1484 DATC_IonClean 3;
BA_ "GenSigSendType" SG_ 1484 DATC_IonClean 4;
BA_ "GenSigStartValue" SG_ 1484 DATC_CO2Warning 3;
BA_ "GenSigSendType" SG_ 1484 DATC_CO2Warning 4;
BA_ "GenSigStartValue" SG_ 1484 DATC_SubBlowerDisp 15;
BA_ "GenSigSendType" SG_ 1484 DATC_SubBlowerDisp 4;
BA_ "GenSigSendType" SG_ 1484 DATC_BeepReq 4;
BA_ "GenSigStartValue" SG_ 1484 DATC_MainBlowerDisp 15;
BA_ "GenSigSendType" SG_ 1484 DATC_MainBlowerDisp 4;
BA_ "GenSigStartValue" SG_ 1484 DATC_PsModeDisp 15;
BA_ "GenSigSendType" SG_ 1484 DATC_PsModeDisp 4;
BA_ "GenSigSendType" SG_ 1483 CR_Datc_DrTempDispC 4;
BA_ "GenSigSendType" SG_ 1483 CR_Datc_DrTempDispF 4;
BA_ "GenSigSendType" SG_ 1483 CR_Datc_PsTempDispC 4;
BA_ "GenSigSendType" SG_ 1483 CR_Datc_PsTempDispF 4;
BA_ "GenSigSendType" SG_ 1483 CF_DATC_TempDisp_Sts 4;
BA_ "GenSigStartValue" SG_ 1483 CF_Datc_DefLogic_USM_State 3;
BA_ "GenSigSendType" SG_ 1483 CF_Datc_DefLogic_USM_State 4;
BA_ "GenSigStartValue" SG_ 1483 CF_Datc_AutoFresh_USM_State 3;
BA_ "GenSigSendType" SG_ 1483 CF_Datc_AutoFresh_USM_State 4;
BA_ "GenSigStartValue" SG_ 1483 DATC_AutoArClnUSMState 3;
BA_ "GenSigSendType" SG_ 1483 DATC_AutoArClnUSMState 4;
BA_ "GenSigSendType" SG_ 1483 CR_Datc_RearDrTempDispC 4;
BA_ "GenSigSendType" SG_ 1483 CR_Datc_RearDrTempDispF 4;
BA_ "GenSigSendType" SG_ 1483 CF_Datc_Option3 4;
BA_ "GenSigSendType" SG_ 1482 CF_Datc_Type 4;
BA_ "GenSigSendType" SG_ 1482 CF_Datc_Option5 4;
BA_ "GenSigSendType" SG_ 1482 CR_Datc_OutTempC 4;
BA_ "GenSigSendType" SG_ 1482 CR_Datc_OutTempF 4;
BA_ "GenSigStartValue" SG_ 1482 CR_NomalClimateLimitStatus 3;
BA_ "GenSigSendType" SG_ 1482 CR_NomalClimateLimitStatus 4;
BA_ "GenSigStartValue" SG_ 1482 CR_SportClimateLimitStatus 3;
BA_ "GenSigSendType" SG_ 1482 CR_SportClimateLimitStatus 4;
BA_ "GenSigStartValue" SG_ 1482 CR_EcoClimateLimitStatus 3;
BA_ "GenSigSendType" SG_ 1482 CR_EcoClimateLimitStatus 4;
BA_ "GenSigStartValue" SG_ 1482 CR_Datc_ClimateLimit_OpSts 3;
BA_ "GenSigSendType" SG_ 1482 CR_Datc_ClimateLimit_OpSts 4;
BA_ "GenSigSendType" SG_ 1482 CF_Datc_Option1 4;
BA_ "GenSigSendType" SG_ 1482 CF_Datc_Option2 4;
BA_ "GenSigSendType" SG_ 1482 CF_Datc_Option4 4;
BA_ "GenSigStartValue" SG_ 1252 CF_EWP_Version 33;
BA_ "GenSigStartValue" SG_ 1527 CF_Datc_Heatpump_Mode 15;
BA_ "GenSigStartValue" SG_ 1527 CR_Fatc_BatChiValve_Status 3;
BA_ "GenSigStartValue" SG_ 1527 CR_Fatc_BatChiValve_FltCode 3;
BA_ "GenSigStartValue" SG_ 1527 CR_Fatc_BatEvapValve_Status 3;
BA_ "GenSigStartValue" SG_ 1527 CR_Fatc_BatEvapValve_FltCode 3;
BA_REL_ "GenSigTimeoutTime" BU_SG_REL_ Dummy SG_ 1301 CF_Clu_ADrUNValueSet 0;
BA_REL_ "GenSigTimeoutTime" BU_SG_REL_ vBDM SG_ 1301 CF_Clu_ADrUNValueSet 0;
BA_REL_ "GenSigTimeoutTime" BU_SG_REL_ Dummy SG_ 1301 CF_Clu_ADrLNValueSet 0;
BA_REL_ "GenSigTimeoutTime" BU_SG_REL_ Dummy SG_ 1301 CF_Clu_EscortHLNValueSet 0;
BA_REL_ "GenSigTimeoutTime" BU_SG_REL_ Dummy SG_ 1301 CF_Clu_DoorLSNValueSet 0;
BA_REL_ "GenSigTimeoutTime" BU_SG_REL_ Dummy SG_ 1301 CF_Clu_PSMNValueSet 0;
BA_REL_ "GenSigTimeoutTime" BU_SG_REL_ Dummy SG_ 1301 CF_Clu_TTUnlockNValueSet 0;
BA_REL_ "GenSigTimeoutTime" BU_SG_REL_ Dummy SG_ 1301 CF_Clu_ATTurnNValueSet 0;
BA_REL_ "GenSigTimeoutTime" BU_SG_REL_ Dummy SG_ 1301 CF_Clu_SCMNValueSet 0;
BA_REL_ "GenSigTimeoutTime" BU_SG_REL_ Dummy SG_ 1301 CF_Clu_WlightNValueSet 0;
BA_REL_ "GenSigTimeoutTime" BU_SG_REL_ DATC SG_ 1301 CF_Clu_TempUnitNValueSet 0;
BA_REL_ "GenSigTimeoutTime" BU_SG_REL_ TMU SG_ 1301 CF_Clu_TempUnitNValueSet 0;
BA_REL_ "GenSigTimeoutTime" BU_SG_REL_ Dummy SG_ 1301 CF_Clu_TrfChgSet 0;
BA_REL_ "GenSigTimeoutTime" BU_SG_REL_ Dummy SG_ 1301 CF_Clu_OTTurnNValueSet 0;
BA_REL_ "GenSigTimeoutTime" BU_SG_REL_ Dummy SG_ 1301 CF_Clu_LcaNValueSet 0;
BA_REL_ "GenSigTimeoutTime" BU_SG_REL_ Dummy SG_ 1301 CF_Clu_RctaNValueSet 0;
BA_REL_ "GenSigTimeoutTime" BU_SG_REL_ Dummy SG_ 1301 CF_Clu_RcwNValueSet 0;
BA_REL_ "GenSigTimeoutTime" BU_SG_REL_ iBAU SG_ 1301 CF_Clu_EcsOffNValueSet 0;
BA_REL_ "GenSigTimeoutTime" BU_SG_REL_ Dummy SG_ 1301 CF_Clu_SccNaviCrvNValueSet 0;
BA_REL_ "GenSigTimeoutTime" BU_SG_REL_ Dummy SG_ 1301 CF_Clu_SccNaviCamNValueSet 0;
BA_REL_ "GenSigTimeoutTime" BU_SG_REL_ Dummy SG_ 1301 CF_Clu_SccAebNValueSet 0;
BA_REL_ "GenSigTimeoutTime" BU_SG_REL_ Dummy SG_ 1301 CF_Clu_LkasModeNValueSet 0;
BA_REL_ "GenSigTimeoutTime" BU_SG_REL_ Dummy SG_ 1301 CF_Clu_FcwNValueSet 0;
BA_REL_ "GenSigTimeoutTime" BU_SG_REL_ Dummy SG_ 1301 CF_Clu_PasSpkrLvNValueSet 0;
BA_REL_ "GenSigTimeoutTime" BU_SG_REL_ Dummy SG_ 1301 CF_Clu_SccDrvModeNValueSet 0;
BA_REL_ "GenSigTimeoutTime" BU_SG_REL_ Dummy SG_ 1301 CF_Clu_HAnBNValueSet 0;
BA_REL_ "GenSigTimeoutTime" BU_SG_REL_ Dummy SG_ 1301 CF_Clu_HfreeTrunkTgNValueSet 0;
BA_REL_ "GenSigTimeoutTime" BU_SG_REL_ BMS SG_ 1031 CR_Cms_EVmaxPower 0;
BA_REL_ "GenSigTimeoutTime" BU_SG_REL_ VCU SG_ 1049 PROLONG_Update 0;
BA_REL_ "GenSigTimeoutTime" BU_SG_REL_ VCU SG_ 1049 PROLONG_Retransmission 0;
BA_REL_ "GenSigTimeoutTime" BU_SG_REL_ VCU SG_ 1049 PROLONG_CountrolPoint 0;
BA_REL_ "GenSigTimeoutTime" BU_SG_REL_ VCU SG_ 1049 PROLONG_ProfileType 0;
BA_REL_ "GenSigTimeoutTime" BU_SG_REL_ VCU SG_ 1049 PROLONG_PathIndex 0;
BA_REL_ "GenSigTimeoutTime" BU_SG_REL_ VCU SG_ 1049 PROLONG_CyclicCounter 0;
BA_REL_ "GenSigTimeoutTime" BU_SG_REL_ VCU SG_ 1049 PROLONG_Offset 0;
BA_REL_ "GenSigTimeoutTime" BU_SG_REL_ VCU SG_ 1049 PROLONG_MessageType 0;
BA_REL_ "GenSigTimeoutTime" BU_SG_REL_ VCU SG_ 1049 PROLONG_Value 0;
BA_REL_ "GenSigTimeoutTime" BU_SG_REL_ VCU SG_ 1048 META_MinorProtocolVersion 0;
BA_REL_ "GenSigTimeoutTime" BU_SG_REL_ VCU SG_ 1048 META_SpeedUnit 0;
BA_REL_ "GenSigTimeoutTime" BU_SG_REL_ VCU SG_ 1048 META_MapVersionYear 0;
BA_REL_ "GenSigTimeoutTime" BU_SG_REL_ VCU SG_ 1048 META_MapVersionQuarter 0;
BA_REL_ "GenSigTimeoutTime" BU_SG_REL_ VCU SG_ 1048 META_RegionCode 0;
BA_REL_ "GenSigTimeoutTime" BU_SG_REL_ VCU SG_ 1048 META_DrivingSide 0;
BA_REL_ "GenSigTimeoutTime" BU_SG_REL_ VCU SG_ 1048 META_HardwareVersion 0;
BA_REL_ "GenSigTimeoutTime" BU_SG_REL_ VCU SG_ 1048 META_MinorProtocolSubVer 0;
BA_REL_ "GenSigTimeoutTime" BU_SG_REL_ VCU SG_ 1048 META_MajorProtocolVersion 0;
BA_REL_ "GenSigTimeoutTime" BU_SG_REL_ VCU SG_ 1048 META_CyclicCounter 0;
BA_REL_ "GenSigTimeoutTime" BU_SG_REL_ VCU SG_ 1048 META_CountryCode 0;
BA_REL_ "GenSigTimeoutTime" BU_SG_REL_ VCU SG_ 1048 META_MapProvider 0;
BA_REL_ "GenSigTimeoutTime" BU_SG_REL_ VCU SG_ 1048 META_MessageType 0;
BA_REL_ "GenSigTimeoutTime" BU_SG_REL_ VCU SG_ 1051 SEG_DirectionLanes 0;
BA_REL_ "GenSigTimeoutTime" BU_SG_REL_ VCU SG_ 1051 SEG_OppositeLanes 0;
BA_REL_ "GenSigTimeoutTime" BU_SG_REL_ VCU SG_ 1051 SEG_DividedRoad 0;
BA_REL_ "GenSigTimeoutTime" BU_SG_REL_ VCU SG_ 1051 SEG_SpeedLimitType 0;
BA_REL_ "GenSigTimeoutTime" BU_SG_REL_ VCU SG_ 1051 SEG_SpeedLimit 0;
BA_REL_ "GenSigTimeoutTime" BU_SG_REL_ VCU SG_ 1051 SEG_FormOfWay 0;
BA_REL_ "GenSigTimeoutTime" BU_SG_REL_ VCU SG_ 1051 SEG_ComplexIntersection 0;
BA_REL_ "GenSigTimeoutTime" BU_SG_REL_ VCU SG_ 1051 SEG_CalculatedRoute 0;
BA_REL_ "GenSigTimeoutTime" BU_SG_REL_ VCU SG_ 1051 SEG_FunctionalRoadClass 0;
BA_REL_ "GenSigTimeoutTime" BU_SG_REL_ VCU SG_ 1051 SEG_RelativeProbability 0;
BA_REL_ "GenSigTimeoutTime" BU_SG_REL_ VCU SG_ 1051 SEG_Update 0;
BA_REL_ "GenSigTimeoutTime" BU_SG_REL_ VCU SG_ 1051 SEG_Retransmission 0;
BA_REL_ "GenSigTimeoutTime" BU_SG_REL_ VCU SG_ 1051 SEG_BuiltUpArea 0;
BA_REL_ "GenSigTimeoutTime" BU_SG_REL_ VCU SG_ 1051 SEG_Bridge 0;
BA_REL_ "GenSigTimeoutTime" BU_SG_REL_ VCU SG_ 1051 SEG_Tunnel 0;
BA_REL_ "GenSigTimeoutTime" BU_SG_REL_ VCU SG_ 1051 SEG_PathIndex 0;
BA_REL_ "GenSigTimeoutTime" BU_SG_REL_ VCU SG_ 1051 SEG_CyclicCounter 0;
BA_REL_ "GenSigTimeoutTime" BU_SG_REL_ VCU SG_ 1051 SEG_Offset 0;
BA_REL_ "GenSigTimeoutTime" BU_SG_REL_ VCU SG_ 1051 SEG_MessageType 0;
BA_REL_ "GenSigTimeoutTime" BU_SG_REL_ DATC SG_ 1289 HU_DATC_PasModeSet 0;
BA_REL_ "GenSigTimeoutTime" BU_SG_REL_ DATC SG_ 1289 HU_DATC_WshFldUSMSet 0;
BA_REL_ "GenSigTimeoutTime" BU_SG_REL_ DATC SG_ 1289 HU_DATC_DrvOnlySet 0;
BA_REL_ "GenSigTimeoutTime" BU_SG_REL_ DATC SG_ 1289 HU_DATC_HeatSet 0;
BA_REL_ "GenSigTimeoutTime" BU_SG_REL_ VCU SG_ 1050 PROSHORT_Update 0;
BA_REL_ "GenSigTimeoutTime" BU_SG_REL_ VCU SG_ 1050 PROSHORT_Retransmission 0;
BA_REL_ "GenSigTimeoutTime" BU_SG_REL_ VCU SG_ 1050 PROSHORT_ControlPoint 0;
BA_REL_ "GenSigTimeoutTime" BU_SG_REL_ VCU SG_ 1050 PROSHORT_ProfileType 0;
BA_REL_ "GenSigTimeoutTime" BU_SG_REL_ VCU SG_ 1050 PROSHORT_Value1 0;
BA_REL_ "GenSigTimeoutTime" BU_SG_REL_ VCU SG_ 1050 PROSHORT_Value0 0;
BA_REL_ "GenSigTimeoutTime" BU_SG_REL_ VCU SG_ 1050 PROSHORT_Distance 0;
BA_REL_ "GenSigTimeoutTime" BU_SG_REL_ VCU SG_ 1050 PROSHORT_Accuracy 0;
BA_REL_ "GenSigTimeoutTime" BU_SG_REL_ VCU SG_ 1050 PROSHORT_PathIndex 0;
BA_REL_ "GenSigTimeoutTime" BU_SG_REL_ VCU SG_ 1050 PROSHORT_CyclicCounter 0;
BA_REL_ "GenSigTimeoutTime" BU_SG_REL_ VCU SG_ 1050 PROSHORT_Offset 0;
BA_REL_ "GenSigTimeoutTime" BU_SG_REL_ VCU SG_ 1050 PROSHORT_MessageType 0;
BA_REL_ "GenSigTimeoutTime" BU_SG_REL_ DATC SG_ 1294 CR_Datc_DRSeatWheel_USM_Set 1000;
BA_REL_ "GenSigTimeoutTime" BU_SG_REL_ DATC SG_ 1294 DATC_TunnelIND 0;
BA_REL_ "GenSigTimeoutTime" BU_SG_REL_ DATC SG_ 1294 DATC_TunnelState 0;
BA_REL_ "GenSigTimeoutTime" BU_SG_REL_ DATC SG_ 1294 C_MFSW_WasherSw 1500;
BA_REL_ "GenSigTimeoutTime" BU_SG_REL_ DATC SG_ 1294 C_IBU_WasherSw 1500;
BA_REL_ "GenSigTimeoutTime" BU_SG_REL_ VCU SG_ 1052 STUB_DirectionLanes 0;
BA_REL_ "GenSigTimeoutTime" BU_SG_REL_ VCU SG_ 1052 STUB_OppositeLanes 0;
BA_REL_ "GenSigTimeoutTime" BU_SG_REL_ VCU SG_ 1052 STUB_RightOfWay 0;
BA_REL_ "GenSigTimeoutTime" BU_SG_REL_ VCU SG_ 1052 STUB_LastStubAtOffset 0;
BA_REL_ "GenSigTimeoutTime" BU_SG_REL_ VCU SG_ 1052 STUB_TurnAngle 0;
BA_REL_ "GenSigTimeoutTime" BU_SG_REL_ VCU SG_ 1052 STUB_FormOfWay 0;
BA_REL_ "GenSigTimeoutTime" BU_SG_REL_ VCU SG_ 1052 STUB_ComplexIntersection 0;
BA_REL_ "GenSigTimeoutTime" BU_SG_REL_ VCU SG_ 1052 STUB_CalculatedRoute 0;
BA_REL_ "GenSigTimeoutTime" BU_SG_REL_ VCU SG_ 1052 STUB_FunctionalRoadClass 0;
BA_REL_ "GenSigTimeoutTime" BU_SG_REL_ VCU SG_ 1052 STUB_RelativeProbability 0;
BA_REL_ "GenSigTimeoutTime" BU_SG_REL_ VCU SG_ 1052 STUB_Update 0;
BA_REL_ "GenSigTimeoutTime" BU_SG_REL_ VCU SG_ 1052 STUB_Retransmission 0;
BA_REL_ "GenSigTimeoutTime" BU_SG_REL_ VCU SG_ 1052 STUB_SubPathIndex 0;
BA_REL_ "GenSigTimeoutTime" BU_SG_REL_ VCU SG_ 1052 STUB_PathIndex 0;
BA_REL_ "GenSigTimeoutTime" BU_SG_REL_ VCU SG_ 1052 STUB_CyclicCounter 0;
BA_REL_ "GenSigTimeoutTime" BU_SG_REL_ VCU SG_ 1052 STUB_Offset 0;
BA_REL_ "GenSigTimeoutTime" BU_SG_REL_ VCU SG_ 1052 STUB_MessageType 0;
BA_REL_ "GenSigTimeoutTime" BU_SG_REL_ CGW SG_ 1293 DATC_DiagMode 1000;
BA_REL_ "GenSigTimeoutTime" BU_SG_REL_ TMU SG_ 1293 DATC_DiagMode 1000;
BA_REL_ "GenSigTimeoutTime" BU_SG_REL_ CGW SG_ 1293 DATC_Rear_ChangeReqDisp 1000;
BA_REL_ "GenSigTimeoutTime" BU_SG_REL_ TMU SG_ 1293 DATC_Rear_ChangeReqDisp 1000;
BA_REL_ "GenSigTimeoutTime" BU_SG_REL_ CGW SG_ 1293 DATC_Rear_ClimateScnDisp 1000;
BA_REL_ "GenSigTimeoutTime" BU_SG_REL_ TMU SG_ 1293 DATC_Rear_ClimateScnDisp 1000;
BA_REL_ "GenSigTimeoutTime" BU_SG_REL_ CGW SG_ 1293 DATC_AutoArClnSysSta 1500;
BA_REL_ "GenSigTimeoutTime" BU_SG_REL_ CGW SG_ 1293 DATC_SelfDiagDisp 1000;
BA_REL_ "GenSigTimeoutTime" BU_SG_REL_ TMU SG_ 1293 DATC_SelfDiagDisp 1000;
BA_REL_ "GenSigTimeoutTime" BU_SG_REL_ CGW SG_ 1293 DATC_AqsLevelOut 1000;
BA_REL_ "GenSigTimeoutTime" BU_SG_REL_ TMU SG_ 1293 DATC_AqsLevelOut 1000;
BA_REL_ "GenSigTimeoutTime" BU_SG_REL_ CGW SG_ 1293 CR_Fatc_PreConSwi 1000;
BA_REL_ "GenSigTimeoutTime" BU_SG_REL_ TMU SG_ 1293 CR_Fatc_PreConSwi 1000;
BA_REL_ "GenSigTimeoutTime" BU_SG_REL_ CGW SG_ 1293 DATC_EV_ScnDisp 1000;
BA_REL_ "GenSigTimeoutTime" BU_SG_REL_ CGW SG_ 1293 DATC_AutoDefogSysOff_Disp 1000;
BA_REL_ "GenSigTimeoutTime" BU_SG_REL_ CGW SG_ 1293 DATC_WshFldUSMState 1500;
BA_REL_ "GenSigTimeoutTime" BU_SG_REL_ CGW SG_ 1293 CR_Datc_ClimatePowSum_W 1000;
BA_REL_ "GenSigTimeoutTime" BU_SG_REL_ TMU SG_ 1293 CR_Datc_ClimatePowSum_W 1000;
BA_REL_ "GenSigTimeoutTime" BU_SG_REL_ CGW SG_ 1293 CR_Datc_BatteryPowSum_Wh 1000;
BA_REL_ "GenSigTimeoutTime" BU_SG_REL_ TMU SG_ 1293 CR_Datc_BatteryPowSum_Wh 1000;
BA_REL_ "GenSigTimeoutTime" BU_SG_REL_ BMS SG_ 1280 CF_SWL_Ind 1000;
BA_REL_ "GenSigTimeoutTime" BU_SG_REL_ BMS SG_ 1280 CF_TTL_Ind 1000;
BA_REL_ "GenSigTimeoutTime" BU_SG_REL_ BMS SG_ 1280 CF_SBR_Ind 1000;
BA_REL_ "GenSigTimeoutTime" BU_SG_REL_ DATC SG_ 1042 CF_Gway_DigitalKeyOption 1500;
BA_REL_ "GenSigTimeoutTime" BU_SG_REL_ DATC SG_ 1042 CF_Gway_ProfileIDRValue 1500;
BA_REL_ "GenSigTimeoutTime" BU_SG_REL_ DATC SG_ 1042 CF_Datc_DefLogic_USM_Set 5000;
BA_REL_ "GenSigTimeoutTime" BU_SG_REL_ DATC SG_ 1042 CF_Datc_AutoFresh_USM_Set 5000;
BA_REL_ "GenSigTimeoutTime" BU_SG_REL_ Dummy SG_ 1287 DBC_CLU 0;
BA_REL_ "GenSigTimeoutTime" BU_SG_REL_ OBC SG_ 1044 CF_TMU_ICCB_InCurModeState 2000;
BA_REL_ "GenSigTimeoutTime" BU_SG_REL_ OBC SG_ 1044 CF_TMU_EVSE_InCurModeState 2000;
BA_REL_ "GenSigTimeoutTime" BU_SG_REL_ CGW SG_ 852 CF_MoodLpColorRValue 0;
BA_REL_ "GenSigTimeoutTime" BU_SG_REL_ CGW SG_ 852 CF_MoodLpBrightValue 0;
BA_REL_ "GenSigTimeoutTime" BU_SG_REL_ BMS SG_ 1062 HU_VIN_Index 3500;
BA_REL_ "GenSigTimeoutTime" BU_SG_REL_ BMS SG_ 1062 HU_VINStatus 3500;
BA_REL_ "GenSigTimeoutTime" BU_SG_REL_ BMS SG_ 1062 HU_TeleOption 3500;
BA_REL_ "GenSigTimeoutTime" BU_SG_REL_ BMS SG_ 1062 HU_VIN_56 3500;
BA_REL_ "GenSigTimeoutTime" BU_SG_REL_ CGW SG_ 1321 CF_Vcu_CO2Rdc 2000;
BA_REL_ "GenSigTimeoutTime" BU_SG_REL_ CGW SG_ 1321 CF_Vcu_CO2RdcTripDist 2000;
BA_REL_ "GenSigTimeoutTime" BU_SG_REL_ Dummy SG_ 1321 CR_Vcu_fRsAirconSq 0;
BA_REL_ "GenSigTimeoutTime" BU_SG_REL_ Dummy SG_ 1321 CR_Vcu_fRsChgState 0;
BA_REL_ "GenSigTimeoutTime" BU_SG_REL_ BMS SG_ 1321 CF_Vcu_fWinterSchedBand 0;
BA_REL_ "GenSigTimeoutTime" BU_SG_REL_ Dummy SG_ 1321 CR_Vcu_tRsRtcSchedDay 0;
BA_REL_ "GenSigTimeoutTime" BU_SG_REL_ Dummy SG_ 1321 CR_Vcu_tRsRtcSchedHr 0;
BA_REL_ "GenSigTimeoutTime" BU_SG_REL_ Dummy SG_ 1321 CR_Vcu_tRsRtcSchedMin 0;
BA_REL_ "GenSigTimeoutTime" BU_SG_REL_ CGW SG_ 1323 CF_Vcu_CruOnLamp 2000;
BA_REL_ "GenSigTimeoutTime" BU_SG_REL_ TMU SG_ 1323 CF_Vcu_CruOnLamp 2000;
BA_REL_ "GenSigTimeoutTime" BU_SG_REL_ iBAU SG_ 1323 CF_Vcu_CruOnLamp 2000;
BA_REL_ "GenSigTimeoutTime" BU_SG_REL_ CGW SG_ 1323 CF_Vcu_CruSetLamp 2000;
BA_REL_ "GenSigTimeoutTime" BU_SG_REL_ TMU SG_ 1323 CF_Vcu_CruSetLamp 2000;
BA_REL_ "GenSigTimeoutTime" BU_SG_REL_ iBAU SG_ 1323 CF_Vcu_CruSetLamp 2000;
BA_REL_ "GenSigTimeoutTime" BU_SG_REL_ CGW SG_ 1323 CR_Vcu_SldVs 2000;
BA_REL_ "GenSigTimeoutTime" BU_SG_REL_ TMU SG_ 1323 CR_Vcu_SldVs 2000;
BA_REL_ "GenSigTimeoutTime" BU_SG_REL_ iBAU SG_ 1323 CR_Vcu_SldVs 2000;
BA_REL_ "GenSigTimeoutTime" BU_SG_REL_ CGW SG_ 1323 CF_Vcu_Ovrride 2000;
BA_REL_ "GenSigTimeoutTime" BU_SG_REL_ TMU SG_ 1323 CF_Vcu_Ovrride 2000;
BA_REL_ "GenSigTimeoutTime" BU_SG_REL_ iBAU SG_ 1323 CF_Vcu_Ovrride 2000;
BA_REL_ "GenSigTimeoutTime" BU_SG_REL_ CGW SG_ 1323 CF_Vcu_CrzDrvAlertDisp 2000;
BA_REL_ "GenSigTimeoutTime" BU_SG_REL_ TMU SG_ 1323 CF_Vcu_CrzDrvAlertDisp 2000;
BA_REL_ "GenSigTimeoutTime" BU_SG_REL_ iBAU SG_ 1323 CF_Vcu_CrzDrvAlertDisp 2000;
BA_REL_ "GenSigTimeoutTime" BU_SG_REL_ CGW SG_ 1323 CF_Vcu_SldAct 2000;
BA_REL_ "GenSigTimeoutTime" BU_SG_REL_ TMU SG_ 1323 CF_Vcu_SldAct 2000;
BA_REL_ "GenSigTimeoutTime" BU_SG_REL_ iBAU SG_ 1323 CF_Vcu_SldAct 2000;
BA_REL_ "GenSigTimeoutTime" BU_SG_REL_ CGW SG_ 1323 CF_Vcu_SldSet 2000;
BA_REL_ "GenSigTimeoutTime" BU_SG_REL_ TMU SG_ 1323 CF_Vcu_SldSet 2000;
BA_REL_ "GenSigTimeoutTime" BU_SG_REL_ iBAU SG_ 1323 CF_Vcu_SldSet 2000;
BA_REL_ "GenSigTimeoutTime" BU_SG_REL_ CGW SG_ 1323 CF_Vcu_SldDrvAlertDisp 2000;
BA_REL_ "GenSigTimeoutTime" BU_SG_REL_ TMU SG_ 1323 CF_Vcu_SldDrvAlertDisp 2000;
BA_REL_ "GenSigTimeoutTime" BU_SG_REL_ iBAU SG_ 1323 CF_Vcu_SldDrvAlertDisp 2000;
BA_REL_ "GenSigTimeoutTime" BU_SG_REL_ VCU SG_ 1085 CF_Clu_CurMon 1500;
BA_REL_ "GenSigTimeoutTime" BU_SG_REL_ VCU SG_ 1085 CF_Clu_CurTue 1500;
BA_REL_ "GenSigTimeoutTime" BU_SG_REL_ VCU SG_ 1085 CF_Clu_CurWed 1500;
BA_REL_ "GenSigTimeoutTime" BU_SG_REL_ VCU SG_ 1085 CF_Clu_CurThu 1500;
BA_REL_ "GenSigTimeoutTime" BU_SG_REL_ VCU SG_ 1085 CF_Clu_CurFri 1500;
BA_REL_ "GenSigTimeoutTime" BU_SG_REL_ VCU SG_ 1085 CF_Clu_CurSat 1500;
BA_REL_ "GenSigTimeoutTime" BU_SG_REL_ VCU SG_ 1085 CF_Clu_CurSun 1500;
BA_REL_ "GenSigTimeoutTime" BU_SG_REL_ VCU SG_ 1085 CF_Clu_CurHour 1500;
BA_REL_ "GenSigTimeoutTime" BU_SG_REL_ VCU SG_ 1085 CF_Clu_CurMin 1500;
BA_REL_ "GenSigTimeoutTime" BU_SG_REL_ VCU SG_ 1085 CF_Clu_CurSec 1500;
BA_REL_ "GenSigTimeoutTime" BU_SG_REL_ VCU SG_ 1085 CF_Clu_CurTime_Rdy 0;
BA_REL_ "GenSigTimeoutTime" BU_SG_REL_ VCU SG_ 1084 CF_Clu_SchedChargNValueSet 0;
BA_REL_ "GenSigTimeoutTime" BU_SG_REL_ VCU SG_ 1084 CF_Clu_SchedClmtNValueSet 0;
BA_REL_ "GenSigTimeoutTime" BU_SG_REL_ VCU SG_ 1084 CF_Clu_SchedClmtDfrNValueSet 0;
BA_REL_ "GenSigTimeoutTime" BU_SG_REL_ VCU SG_ 1084 CF_Clu_BatteryHeatNValueSet 0;
BA_REL_ "GenSigTimeoutTime" BU_SG_REL_ VCU SG_ 1084 CF_Clu_DepartSunNValueSet 0;
BA_REL_ "GenSigTimeoutTime" BU_SG_REL_ VCU SG_ 1084 CF_Clu_DepartMonNValueSet 0;
BA_REL_ "GenSigTimeoutTime" BU_SG_REL_ VCU SG_ 1084 CF_Clu_SchedClmtTempNValueSet 0;
BA_REL_ "GenSigTimeoutTime" BU_SG_REL_ VCU SG_ 1084 CF_Clu_DepartTueNValueSet 0;
BA_REL_ "GenSigTimeoutTime" BU_SG_REL_ VCU SG_ 1084 CF_Clu_DepartWedNValueSet 0;
BA_REL_ "GenSigTimeoutTime" BU_SG_REL_ VCU SG_ 1084 CF_Clu_DepartThuNValueSet 0;
BA_REL_ "GenSigTimeoutTime" BU_SG_REL_ VCU SG_ 1084 CF_Clu_DepartFriNValueSet 0;
BA_REL_ "GenSigTimeoutTime" BU_SG_REL_ VCU SG_ 1084 CF_Clu_DepartSatNValueSet 0;
BA_REL_ "GenSigTimeoutTime" BU_SG_REL_ VCU SG_ 1084 CF_Clu_DepartHourNValueSet 0;
BA_REL_ "GenSigTimeoutTime" BU_SG_REL_ VCU SG_ 1084 CF_Clu_DepartMinNValueSet 0;
BA_REL_ "GenSigTimeoutTime" BU_SG_REL_ OBC SG_ 1084 CF_Clu_EVSE_InCurNValueSet 0;
BA_REL_ "GenSigTimeoutTime" BU_SG_REL_ OBC SG_ 1084 CF_Clu_ICCB_InCurNValueSet 0;
BA_REL_ "GenSigTimeoutTime" BU_SG_REL_ VCU SG_ 1084 CF_Clu_EcoRegenLvNValueSet 0;
BA_REL_ "GenSigTimeoutTime" BU_SG_REL_ VCU SG_ 1084 CF_Clu_NormalRegenLvNValueSet 0;
BA_REL_ "GenSigTimeoutTime" BU_SG_REL_ VCU SG_ 1084 CF_Clu_EconSTHourNValueSet 0;
BA_REL_ "GenSigTimeoutTime" BU_SG_REL_ VCU SG_ 1084 CF_Clu_EconENDHourNValueSet 0;
BA_REL_ "GenSigTimeoutTime" BU_SG_REL_ H_U SG_ 127 C_StopLampLhOpenSts 5000;
BA_REL_ "GenSigTimeoutTime" BU_SG_REL_ vBDM SG_ 127 C_StopLampLhOpenSts 5000;
BA_REL_ "GenSigTimeoutTime" BU_SG_REL_ H_U SG_ 127 C_StopLampRhOpenSts 5000;
BA_REL_ "GenSigTimeoutTime" BU_SG_REL_ vBDM SG_ 127 C_StopLampRhOpenSts 5000;
BA_REL_ "GenSigTimeoutTime" BU_SG_REL_ H_U SG_ 127 C_HLampLowLhOpenSts 5000;
BA_REL_ "GenSigTimeoutTime" BU_SG_REL_ vBDM SG_ 127 C_HLampLowLhOpenSts 5000;
BA_REL_ "GenSigTimeoutTime" BU_SG_REL_ H_U SG_ 127 C_HLampLowRhOpenSts 5000;
BA_REL_ "GenSigTimeoutTime" BU_SG_REL_ vBDM SG_ 127 C_HLampLowRhOpenSts 5000;
BA_REL_ "GenSigTimeoutTime" BU_SG_REL_ H_U SG_ 127 C_HLampHighLhOpenSts 5000;
BA_REL_ "GenSigTimeoutTime" BU_SG_REL_ vBDM SG_ 127 C_HLampHighLhOpenSts 5000;
BA_REL_ "GenSigTimeoutTime" BU_SG_REL_ H_U SG_ 127 C_HLampHighRhOpenSts 5000;
BA_REL_ "GenSigTimeoutTime" BU_SG_REL_ vBDM SG_ 127 C_HLampHighRhOpenSts 5000;
BA_REL_ "GenSigTimeoutTime" BU_SG_REL_ H_U SG_ 127 C_RearTSIGLhOpenSts 5000;
BA_REL_ "GenSigTimeoutTime" BU_SG_REL_ vBDM SG_ 127 C_RearTSIGLhOpenSts 5000;
BA_REL_ "GenSigTimeoutTime" BU_SG_REL_ H_U SG_ 127 C_RearTSIGRhOpenSts 5000;
BA_REL_ "GenSigTimeoutTime" BU_SG_REL_ vBDM SG_ 127 C_RearTSIGRhOpenSts 5000;
BA_REL_ "GenSigTimeoutTime" BU_SG_REL_ H_U SG_ 127 C_FrontTSIGLhOpenSts 5000;
BA_REL_ "GenSigTimeoutTime" BU_SG_REL_ vBDM SG_ 127 C_FrontTSIGLhOpenSts 5000;
BA_REL_ "GenSigTimeoutTime" BU_SG_REL_ H_U SG_ 127 C_FrontTSIGRhOpenSts 5000;
BA_REL_ "GenSigTimeoutTime" BU_SG_REL_ vBDM SG_ 127 C_FrontTSIGRhOpenSts 5000;
BA_REL_ "GenSigTimeoutTime" BU_SG_REL_ H_U SG_ 127 C_HLampBifuncLhOpenSts 5000;
BA_REL_ "GenSigTimeoutTime" BU_SG_REL_ vBDM SG_ 127 C_HLampBifuncLhOpenSts 5000;
BA_REL_ "GenSigTimeoutTime" BU_SG_REL_ H_U SG_ 127 C_HLampBifuncRhOpenSts 5000;
BA_REL_ "GenSigTimeoutTime" BU_SG_REL_ vBDM SG_ 127 C_HLampBifuncRhOpenSts 5000;
BA_REL_ "GenSigTimeoutTime" BU_SG_REL_ LVR SG_ 127 C_MoodLp 1500;
BA_REL_ "GenSigTimeoutTime" BU_SG_REL_ LVR SG_ 127 CF_Gway_MoodLpColorRValue 0;
BA_REL_ "GenSigTimeoutTime" BU_SG_REL_ LVR SG_ 127 CF_Gway_MoodLpBrightRValue 0;
BA_REL_ "GenSigTimeoutTime" BU_SG_REL_ OBC SG_ 1312 CF_OBCWakeupDrUnlock 0;
BA_REL_ "GenSigTimeoutTime" BU_SG_REL_ AAF SG_ 1312 C_MirOutTempSns 1000;
BA_REL_ "GenSigTimeoutTime" BU_SG_REL_ DATC SG_ 1312 C_MirOutTempSns 1000;
BA_REL_ "GenSigTimeoutTime" BU_SG_REL_ Dummy SG_ 1312 CF_Gway_Autolightsensor_Hor 1500;
BA_REL_ "GenSigTimeoutTime" BU_SG_REL_ Dummy SG_ 1312 CF_Gway_Autolightsensor_Ver 1500;
BA_REL_ "GenSigTimeoutTime" BU_SG_REL_ CGW SG_ 1077 DATC_AmbSnsVal 5000;
BA_REL_ "GenSigTimeoutTime" BU_SG_REL_ VCRM SG_ 1077 DATC_AmbSnsVal 5000;
BA_REL_ "GenSigTimeoutTime" BU_SG_REL_ vBDM SG_ 1077 DATC_AmbSnsVal 5000;
BA_REL_ "GenSigTimeoutTime" BU_SG_REL_ CGW SG_ 1077 DATC_FrIncarSnsVal 5000;
BA_REL_ "GenSigTimeoutTime" BU_SG_REL_ VCRM SG_ 1077 DATC_FrIncarSnsVal 5000;
BA_REL_ "GenSigTimeoutTime" BU_SG_REL_ vBDM SG_ 1077 DATC_FrIncarSnsVal 5000;
BA_REL_ "GenSigTimeoutTime" BU_SG_REL_ CGW SG_ 1077 DATC_RrIncarSnsVal 5000;
BA_REL_ "GenSigTimeoutTime" BU_SG_REL_ VCRM SG_ 1077 DATC_RrIncarSnsVal 5000;
BA_REL_ "GenSigTimeoutTime" BU_SG_REL_ vBDM SG_ 1077 DATC_RrIncarSnsVal 5000;
BA_REL_ "GenSigTimeoutTime" BU_SG_REL_ CGW SG_ 1077 DATC_LhPhotoSnsVal 5000;
BA_REL_ "GenSigTimeoutTime" BU_SG_REL_ VCRM SG_ 1077 DATC_LhPhotoSnsVal 5000;
BA_REL_ "GenSigTimeoutTime" BU_SG_REL_ vBDM SG_ 1077 DATC_LhPhotoSnsVal 5000;
BA_REL_ "GenSigTimeoutTime" BU_SG_REL_ CGW SG_ 1077 DATC_RhPhotoSnsVal 5000;
BA_REL_ "GenSigTimeoutTime" BU_SG_REL_ VCRM SG_ 1077 DATC_RhPhotoSnsVal 5000;
BA_REL_ "GenSigTimeoutTime" BU_SG_REL_ vBDM SG_ 1077 DATC_RhPhotoSnsVal 5000;
BA_REL_ "GenSigTimeoutTime" BU_SG_REL_ CGW SG_ 1077 DATC_EvaSnsVal 5000;
BA_REL_ "GenSigTimeoutTime" BU_SG_REL_ VCRM SG_ 1077 DATC_EvaSnsVal 5000;
BA_REL_ "GenSigTimeoutTime" BU_SG_REL_ vBDM SG_ 1077 DATC_EvaSnsVal 5000;
BA_REL_ "GenSigTimeoutTime" BU_SG_REL_ CGW SG_ 1077 DATC_AdsSnsVal 5000;
BA_REL_ "GenSigTimeoutTime" BU_SG_REL_ VCRM SG_ 1077 DATC_AdsSnsVal 5000;
BA_REL_ "GenSigTimeoutTime" BU_SG_REL_ vBDM SG_ 1077 DATC_AdsSnsVal 5000;
BA_REL_ "GenSigTimeoutTime" BU_SG_REL_ CGW SG_ 1077 DATC_DustSnsVal 5000;
BA_REL_ "GenSigTimeoutTime" BU_SG_REL_ VCRM SG_ 1077 DATC_DustSnsVal 5000;
BA_REL_ "GenSigTimeoutTime" BU_SG_REL_ vBDM SG_ 1077 DATC_DustSnsVal 5000;
BA_REL_ "GenSigTimeoutTime" BU_SG_REL_ CGW SG_ 1076 DATC_MnlBlwSta 5000;
BA_REL_ "GenSigTimeoutTime" BU_SG_REL_ VCRM SG_ 1076 DATC_MnlBlwSta 5000;
BA_REL_ "GenSigTimeoutTime" BU_SG_REL_ vBDM SG_ 1076 DATC_MnlBlwSta 5000;
BA_REL_ "GenSigTimeoutTime" BU_SG_REL_ CGW SG_ 1076 DATC_MnlModSta 5000;
BA_REL_ "GenSigTimeoutTime" BU_SG_REL_ VCRM SG_ 1076 DATC_MnlModSta 5000;
BA_REL_ "GenSigTimeoutTime" BU_SG_REL_ vBDM SG_ 1076 DATC_MnlModSta 5000;
BA_REL_ "GenSigTimeoutTime" BU_SG_REL_ CGW SG_ 1076 DATC_MnlACSta 5000;
BA_REL_ "GenSigTimeoutTime" BU_SG_REL_ VCRM SG_ 1076 DATC_MnlACSta 5000;
BA_REL_ "GenSigTimeoutTime" BU_SG_REL_ vBDM SG_ 1076 DATC_MnlACSta 5000;
BA_REL_ "GenSigTimeoutTime" BU_SG_REL_ CGW SG_ 1076 DATC_MnlIntakeSta 5000;
BA_REL_ "GenSigTimeoutTime" BU_SG_REL_ VCRM SG_ 1076 DATC_MnlIntakeSta 5000;
BA_REL_ "GenSigTimeoutTime" BU_SG_REL_ vBDM SG_ 1076 DATC_MnlIntakeSta 5000;
BA_REL_ "GenSigTimeoutTime" BU_SG_REL_ CGW SG_ 1076 DATC_MnlRrBlwrSta 5000;
BA_REL_ "GenSigTimeoutTime" BU_SG_REL_ VCRM SG_ 1076 DATC_MnlRrBlwrSta 5000;
BA_REL_ "GenSigTimeoutTime" BU_SG_REL_ vBDM SG_ 1076 DATC_MnlRrBlwrSta 5000;
BA_REL_ "GenSigTimeoutTime" BU_SG_REL_ CGW SG_ 1076 DATC_MnlRrModSta 5000;
BA_REL_ "GenSigTimeoutTime" BU_SG_REL_ VCRM SG_ 1076 DATC_MnlRrModSta 5000;
BA_REL_ "GenSigTimeoutTime" BU_SG_REL_ vBDM SG_ 1076 DATC_MnlRrModSta 5000;
BA_REL_ "GenSigTimeoutTime" BU_SG_REL_ CGW SG_ 1076 DATC_MnlRrACSta 5000;
BA_REL_ "GenSigTimeoutTime" BU_SG_REL_ VCRM SG_ 1076 DATC_MnlRrACSta 5000;
BA_REL_ "GenSigTimeoutTime" BU_SG_REL_ vBDM SG_ 1076 DATC_MnlRrACSta 5000;
BA_REL_ "GenSigTimeoutTime" BU_SG_REL_ CGW SG_ 1076 DATC_StrWhlHtrSta 5000;
BA_REL_ "GenSigTimeoutTime" BU_SG_REL_ VCRM SG_ 1076 DATC_StrWhlHtrSta 5000;
BA_REL_ "GenSigTimeoutTime" BU_SG_REL_ vBDM SG_ 1076 DATC_StrWhlHtrSta 5000;
BA_REL_ "GenSigTimeoutTime" BU_SG_REL_ CGW SG_ 1076 DATC_DrvStHtrVntSta 5000;
BA_REL_ "GenSigTimeoutTime" BU_SG_REL_ VCRM SG_ 1076 DATC_DrvStHtrVntSta 5000;
BA_REL_ "GenSigTimeoutTime" BU_SG_REL_ vBDM SG_ 1076 DATC_DrvStHtrVntSta 5000;
BA_REL_ "GenSigTimeoutTime" BU_SG_REL_ CGW SG_ 1076 DATC_PassStHtrVntSta 5000;
BA_REL_ "GenSigTimeoutTime" BU_SG_REL_ VCRM SG_ 1076 DATC_PassStHtrVntSta 5000;
BA_REL_ "GenSigTimeoutTime" BU_SG_REL_ vBDM SG_ 1076 DATC_PassStHtrVntSta 5000;
BA_REL_ "GenSigTimeoutTime" BU_SG_REL_ CGW SG_ 1494 CR_Bms_BatMinCel_V 2000;
BA_REL_ "GenSigTimeoutTime" BU_SG_REL_ TMU SG_ 1494 CR_Bms_BatMinCel_V 2000;
BA_REL_ "GenSigTimeoutTime" BU_SG_REL_ vBDM SG_ 1494 CR_Bms_BatMinCel_V 2000;
BA_REL_ "GenSigTimeoutTime" BU_SG_REL_ TMU SG_ 1494 CR_Bms_BatMaxCel_V 2000;
BA_REL_ "GenSigTimeoutTime" BU_SG_REL_ TMU SG_ 1494 CR_Bms_BatI_A 2000;
BA_REL_ "GenSigTimeoutTime" BU_SG_REL_ TMU SG_ 1494 CR_Bms_BatMinTemp_C 2000;
BA_REL_ "GenSigTimeoutTime" BU_SG_REL_ TMU SG_ 1494 CR_Bms_BatMaxTemp_C 2000;
BA_REL_ "GenSigTimeoutTime" BU_SG_REL_ TMU SG_ 1494 CF_Bms_Diag_Group 2000;
BA_REL_ "GenSigTimeoutTime" BU_SG_REL_ TMU SG_ 1494 CR_Bms_BatPwrLmt_W 2000;
BA_REL_ "GenSigTimeoutTime" BU_SG_REL_ TMU SG_ 1495 CF_Bms_EvReady 2000;
BA_REL_ "GenSigTimeoutTime" BU_SG_REL_ TMU SG_ 1495 CF_Bms_NoError 2000;
BA_REL_ "GenSigTimeoutTime" BU_SG_REL_ TMU SG_ 1495 CF_Bms_Fail_Temp 2000;
BA_REL_ "GenSigTimeoutTime" BU_SG_REL_ TMU SG_ 1495 CF_Bms_FAILED_EVShiftPosition 2000;
BA_REL_ "GenSigTimeoutTime" BU_SG_REL_ TMU SG_ 1495 CF_Bms_Fail_Conlock 2000;
BA_REL_ "GenSigTimeoutTime" BU_SG_REL_ TMU SG_ 1495 CF_Bms_Fail_Evmalf 2000;
BA_REL_ "GenSigTimeoutTime" BU_SG_REL_ TMU SG_ 1495 CF_Bms_Fail_CurrDiff 2000;
BA_REL_ "GenSigTimeoutTime" BU_SG_REL_ TMU SG_ 1495 CF_Bms_Fail_VoltRange 2000;
BA_REL_ "GenSigTimeoutTime" BU_SG_REL_ TMU SG_ 1495 CF_Bms_Fail_ChgSysIncom 2000;
BA_REL_ "GenSigTimeoutTime" BU_SG_REL_ TMU SG_ 1495 CF_Bms_ReadyToCharge 2000;
BA_REL_ "GenSigTimeoutTime" BU_SG_REL_ CGW SG_ 1495 CF_Bms_ChgFinished 2000;
BA_REL_ "GenSigTimeoutTime" BU_SG_REL_ H_U SG_ 1495 CF_Bms_ChgFinished 2000;
BA_REL_ "GenSigTimeoutTime" BU_SG_REL_ TMU SG_ 1495 CF_Bms_ChgFinished 2000;
BA_REL_ "GenSigTimeoutTime" BU_SG_REL_ TMU SG_ 1495 CF_Bms_PreparationStatusForPLC 2000;
BA_REL_ "GenSigTimeoutTime" BU_SG_REL_ TMU SG_ 1495 CF_Bms_ReadyForCurDem 2000;
BA_REL_ "GenSigTimeoutTime" BU_SG_REL_ TMU SG_ 1495 CF_Bms_IG3RlyOffEnable 2000;
BA_REL_ "GenSigTimeoutTime" BU_SG_REL_ OBC SG_ 1495 CF_Bms_Charging_ST 0;
BA_REL_ "GenSigTimeoutTime" BU_SG_REL_ TMU SG_ 1495 CF_Bms_Charging_ST 0;
BA_REL_ "GenSigTimeoutTime" BU_SG_REL_ CGW SG_ 1495 CF_Bms_Lamp_Req 10000;
BA_REL_ "GenSigTimeoutTime" BU_SG_REL_ H_U SG_ 1495 CF_Bms_Lamp_Req 10000;
BA_REL_ "GenSigTimeoutTime" BU_SG_REL_ TMU SG_ 1495 CF_Bms_Lamp_Req 10000;
BA_REL_ "GenSigTimeoutTime" BU_SG_REL_ vBDM SG_ 1495 CF_Bms_Lamp_Req 10000;
BA_REL_ "GenSigTimeoutTime" BU_SG_REL_ TMU SG_ 1495 CR_Bms_EVTargetCurrent 2000;
BA_REL_ "GenSigTimeoutTime" BU_SG_REL_ CCM SG_ 1495 CF_Bms_BulkRemTime_Always 2000;
BA_REL_ "GenSigTimeoutTime" BU_SG_REL_ CGW SG_ 1495 CF_Bms_BulkRemTime_Always 2000;
BA_REL_ "GenSigTimeoutTime" BU_SG_REL_ vBDM SG_ 1495 CF_Bms_BulkRemTime_Always 2000;
BA_REL_ "GenSigTimeoutTime" BU_SG_REL_ TMU SG_ 1495 CR_Bms_PLCChgFaultSubCode 0;
BA_REL_ "GenSigTimeoutTime" BU_SG_REL_ TMU SG_ 1495 CR_Bms_Chg_Curr_Req_Cha 0;
BA_REL_ "GenSigTimeoutTime" BU_SG_REL_ DATC SG_ 1492 IBOX_IVRActivity 5000;
BA_REL_ "GenSigTimeoutTime" BU_SG_REL_ DATC SG_ 1492 IBOX_PhoneActivity 5000;
BA_REL_ "GenSigTimeoutTime" BU_SG_REL_ BCF SG_ 1493 CR_Bms_PwmDutyCmd 2000;
BA_REL_ "GenSigTimeoutTime" BU_SG_REL_ BCF SG_ 1493 CR_Bms_FanFeedbackFreqbyCan 2000;
BA_REL_ "GenSigTimeoutTime" BU_SG_REL_ BCF SG_ 1493 CR_Bms_FanFeedbackFreqbyWire 2000;
BA_REL_ "GenSigTimeoutTime" BU_SG_REL_ CLU SG_ 1493 CF_Bms_FstEvseFltAlram 0;
BA_REL_ "GenSigTimeoutTime" BU_SG_REL_ CCM SG_ 1493 CF_Bms_WeldDctFinish 1000;
BA_REL_ "GenSigTimeoutTime" BU_SG_REL_ Dummy SG_ 1493 CR_Bms_CoolantLeakage_V 2000;
BA_REL_ "GenSigTimeoutTime" BU_SG_REL_ CGW SG_ 1493 CR_Bms_ScChgTargetSOC_SYNC 2000;
BA_REL_ "GenSigTimeoutTime" BU_SG_REL_ TMU SG_ 1493 CR_Bms_ScChgTargetSOC_SYNC 2000;
BA_REL_ "GenSigTimeoutTime" BU_SG_REL_ VCU SG_ 1493 CR_Bms_ScChgTargetSOC_SYNC 2000;
BA_REL_ "GenSigTimeoutTime" BU_SG_REL_ CGW SG_ 1493 CR_Bms_QcChgTargetSOC_SYNC 2000;
BA_REL_ "GenSigTimeoutTime" BU_SG_REL_ TMU SG_ 1493 CR_Bms_QcChgTargetSOC_SYNC 2000;
BA_REL_ "GenSigTimeoutTime" BU_SG_REL_ CGW SG_ 1493 CF_Bms_BatEvtAlarm 2000;
BA_REL_ "GenSigTimeoutTime" BU_SG_REL_ H_U SG_ 1493 CF_Bms_BatEvtAlarm 2000;
BA_REL_ "GenSigTimeoutTime" BU_SG_REL_ MCU SG_ 1493 CF_Bms_BatEvtAlarm 2000;
BA_REL_ "GenSigTimeoutTime" BU_SG_REL_ VCU SG_ 1493 CF_Bms_BatEvtAlarm 2000;
BA_REL_ "GenSigTimeoutTime" BU_SG_REL_ CGW SG_ 1493 CR_Bms_PRATemp_C 2000;
BA_REL_ "GenSigTimeoutTime" BU_SG_REL_ Dummy SG_ 1493 CR_Bms_PRATemp_C 2000;
BA_REL_ "GenSigTimeoutTime" BU_SG_REL_ vBDM SG_ 1493 CR_Bms_PRATemp_C 2000;
BA_REL_ "GenSigTimeoutTime" BU_SG_REL_ DATC SG_ 1491 HU_VRActivity 5000;
BA_REL_ "GenSigTimeoutTime" BU_SG_REL_ DATC SG_ 1491 HU_PhoneActivity 5000;
BA_REL_ "GenSigTimeoutTime" BU_SG_REL_ DATC SG_ 1491 HU_DATC_AirQuality_Info 5000;
BA_REL_ "GenSigTimeoutTime" BU_SG_REL_ AAF SG_ 1488 CF_Clu_Odometer 5000;
BA_REL_ "GenSigTimeoutTime" BU_SG_REL_ BMS SG_ 1488 CF_Clu_Odometer 5000;
BA_REL_ "GenSigTimeoutTime" BU_SG_REL_ H_U SG_ 1488 CF_Clu_Odometer 5000;
BA_REL_ "GenSigTimeoutTime" BU_SG_REL_ IBU SG_ 1488 CF_Clu_Odometer 5000;
BA_REL_ "GenSigTimeoutTime" BU_SG_REL_ LDC SG_ 1488 CF_Clu_Odometer 5000;
BA_REL_ "GenSigTimeoutTime" BU_SG_REL_ MCU SG_ 1488 CF_Clu_Odometer 5000;
BA_REL_ "GenSigTimeoutTime" BU_SG_REL_ NEMS SG_ 1488 CF_Clu_Odometer 5000;
BA_REL_ "GenSigTimeoutTime" BU_SG_REL_ OBC SG_ 1488 CF_Clu_Odometer 5000;
BA_REL_ "GenSigTimeoutTime" BU_SG_REL_ TMU SG_ 1488 CF_Clu_Odometer 5000;
BA_REL_ "GenSigTimeoutTime" BU_SG_REL_ VCU SG_ 1488 CF_Clu_Odometer 5000;
BA_REL_ "GenSigTimeoutTime" BU_SG_REL_ eCall SG_ 1488 CF_Clu_Odometer 5000;
BA_REL_ "GenSigTimeoutTime" BU_SG_REL_ DATC SG_ 1488 CF_LKA_Opt_USM 5000;
BA_REL_ "GenSigTimeoutTime" BU_SG_REL_ TMU SG_ 1502 CF_Mcu_VCRM_Infocode 2000;
BA_REL_ "GenSigTimeoutTime" BU_SG_REL_ TMU SG_ 1502 CR_Mcu_VCRM_MotTemp_C 0;
BA_REL_ "GenSigTimeoutTime" BU_SG_REL_ TMU SG_ 1502 CR_Mcu_VCRM_InvIptVol_V 5000;
BA_REL_ "GenSigTimeoutTime" BU_SG_REL_ TMU SG_ 1502 CR_Mcu_VCRM_HeatsinkTemp_C 5000;
BA_REL_ "GenSigTimeoutTime" BU_SG_REL_ TMU SG_ 1502 CR_Mcu_VCRM_InvTemp_C 5000;
BA_REL_ "GenSigTimeoutTime" BU_SG_REL_ TMU SG_ 1502 CR_Mcu_VCRM_IgbtTemp_C 5000;
BA_REL_ "GenSigTimeoutTime" BU_SG_REL_ CGW SG_ 1502 CF_Mcu_VCRM_Req 5000;
BA_REL_ "GenSigTimeoutTime" BU_SG_REL_ H_U SG_ 1502 CF_Mcu_VCRM_Req 5000;
BA_REL_ "GenSigTimeoutTime" BU_SG_REL_ TMU SG_ 1502 CF_Mcu_VCRM_Req 5000;
BA_REL_ "GenSigTimeoutTime" BU_SG_REL_ vBDM SG_ 1502 CF_Mcu_VCRM_Req 5000;
BA_REL_ "GenSigTimeoutTime" BU_SG_REL_ CGW SG_ 1502 CF_Mcu_Lamp_Req 5000;
BA_REL_ "GenSigTimeoutTime" BU_SG_REL_ H_U SG_ 1502 CF_Mcu_Lamp_Req 5000;
BA_REL_ "GenSigTimeoutTime" BU_SG_REL_ TMU SG_ 1502 CF_Mcu_Lamp_Req 5000;
BA_REL_ "GenSigTimeoutTime" BU_SG_REL_ VCU SG_ 1503 HU_AliveStatus 700;
BA_REL_ "GenSigTimeoutTime" BU_SG_REL_ VCU SG_ 1503 HU_NaviStatus 3500;
BA_REL_ "GenSigTimeoutTime" BU_SG_REL_ VCU SG_ 1503 HU_Navigation_On_Off 3500;
BA_REL_ "GenSigTimeoutTime" BU_SG_REL_ OBC SG_ 1503 HU_Type 3500;
BA_REL_ "GenSigTimeoutTime" BU_SG_REL_ VCU SG_ 1503 HU_Type 3500;
BA_REL_ "GenSigTimeoutTime" BU_SG_REL_ VCU SG_ 1503 HU_DistributeInfo 3500;
BA_REL_ "GenSigTimeoutTime" BU_SG_REL_ VCU SG_ 1503 HU_AdasSupport 3500;
BA_REL_ "GenSigTimeoutTime" BU_SG_REL_ CGW SG_ 1500 CR_Mcu_VCRM_MotActRotSpd_rpm 5000;
BA_REL_ "GenSigTimeoutTime" BU_SG_REL_ TMU SG_ 1500 CR_Mcu_VCRM_MotActRotSpd_rpm 5000;
BA_REL_ "GenSigTimeoutTime" BU_SG_REL_ vBDM SG_ 1500 CR_Mcu_VCRM_MotActRotSpd_rpm 5000;
BA_REL_ "GenSigTimeoutTime" BU_SG_REL_ TMU SG_ 1500 CR_Mcu_VCRM_EwpSpdReq_rpm 5000;
BA_REL_ "GenSigTimeoutTime" BU_SG_REL_ TMU SG_ 1500 CR_Mcu_VCRM_MotEstTq_Pc 5000;
BA_REL_ "GenSigTimeoutTime" BU_SG_REL_ TMU SG_ 1500 CR_Mcu_VCRM_MotDeFact_Pc 5000;
BA_REL_ "GenSigTimeoutTime" BU_SG_REL_ CGW SG_ 1500 CR_Mcu_Gen_Power_wh 5000;
BA_REL_ "GenSigTimeoutTime" BU_SG_REL_ CGW SG_ 673 CR_Mcu_InfoCodeL1 2000;
BA_REL_ "GenSigTimeoutTime" BU_SG_REL_ VCU SG_ 673 CR_Mcu_InfoCodeL1 2000;
BA_REL_ "GenSigTimeoutTime" BU_SG_REL_ vBDM SG_ 673 CR_Mcu_InfoCodeL1 2000;
BA_REL_ "GenSigTimeoutTime" BU_SG_REL_ VCU SG_ 673 CR_Mcu_InfoCodeL2 2000;
BA_REL_ "GenSigTimeoutTime" BU_SG_REL_ VCU SG_ 673 CR_Mcu_InfoCodeL3 2000;
BA_REL_ "GenSigTimeoutTime" BU_SG_REL_ VCU SG_ 673 CR_Mcu_InfoCodeL4 2000;
BA_REL_ "GenSigTimeoutTime" BU_SG_REL_ VCU SG_ 673 CR_Mcu_InfoCodeL5 2000;
BA_REL_ "GenSigTimeoutTime" BU_SG_REL_ VCU SG_ 673 CR_Mcu_InfoCodeL6 2000;
BA_REL_ "GenSigTimeoutTime" BU_SG_REL_ VCU SG_ 673 CR_Mcu_InfoCodeLU 2000;
BA_REL_ "GenSigTimeoutTime" BU_SG_REL_ CGW SG_ 673 CF_Mcu_RsvSnslessStatForClu 2000;
BA_REL_ "GenSigTimeoutTime" BU_SG_REL_ VCU SG_ 673 CF_Mcu_PgmRun4 2000;
BA_REL_ "GenSigTimeoutTime" BU_SG_REL_ TMU SG_ 1496 CF_Bms_ServiceLamp 2000;
BA_REL_ "GenSigTimeoutTime" BU_SG_REL_ CGW SG_ 1496 CF_Bms_Flt 2000;
BA_REL_ "GenSigTimeoutTime" BU_SG_REL_ H_U SG_ 1496 CF_Bms_Flt 2000;
BA_REL_ "GenSigTimeoutTime" BU_SG_REL_ TMU SG_ 1496 CF_Bms_Flt 2000;
BA_REL_ "GenSigTimeoutTime" BU_SG_REL_ vBDM SG_ 1496 CF_Bms_Flt 2000;
BA_REL_ "GenSigTimeoutTime" BU_SG_REL_ CGW SG_ 1496 CF_Bms_StdCha_120V 2000;
BA_REL_ "GenSigTimeoutTime" BU_SG_REL_ H_U SG_ 1496 CF_Bms_StdCha_120V 2000;
BA_REL_ "GenSigTimeoutTime" BU_SG_REL_ TMU SG_ 1496 CF_Bms_StdCha_120V 2000;
BA_REL_ "GenSigTimeoutTime" BU_SG_REL_ CGW SG_ 1496 CF_Bms_StdCha 2000;
BA_REL_ "GenSigTimeoutTime" BU_SG_REL_ H_U SG_ 1496 CF_Bms_StdCha 2000;
BA_REL_ "GenSigTimeoutTime" BU_SG_REL_ TMU SG_ 1496 CF_Bms_StdCha 2000;
BA_REL_ "GenSigTimeoutTime" BU_SG_REL_ CDM SG_ 1496 CF_Bms_ChgSts 2000;
BA_REL_ "GenSigTimeoutTime" BU_SG_REL_ CGW SG_ 1496 CF_Bms_ChgSts 2000;
BA_REL_ "GenSigTimeoutTime" BU_SG_REL_ DATC SG_ 1496 CF_Bms_ChgSts 2000;
BA_REL_ "GenSigTimeoutTime" BU_SG_REL_ H_U SG_ 1496 CF_Bms_ChgSts 2000;
BA_REL_ "GenSigTimeoutTime" BU_SG_REL_ TMU SG_ 1496 CF_Bms_ChgSts 2000;
BA_REL_ "GenSigTimeoutTime" BU_SG_REL_ CGW SG_ 1496 CF_BMS_ChgFinishedForOBC 2000;
BA_REL_ "GenSigTimeoutTime" BU_SG_REL_ H_U SG_ 1496 CF_BMS_ChgFinishedForOBC 2000;
BA_REL_ "GenSigTimeoutTime" BU_SG_REL_ TMU SG_ 1496 CF_BMS_ChgFinishedForOBC 2000;
BA_REL_ "GenSigTimeoutTime" BU_SG_REL_ TMU SG_ 1496 CF_Bms_MainRlyOnStat 2000;
BA_REL_ "GenSigTimeoutTime" BU_SG_REL_ TMU SG_ 1496 CF_Bms_LdcInh 2000;
BA_REL_ "GenSigTimeoutTime" BU_SG_REL_ CDM SG_ 1496 CR_BMS_DisplaySOC 2000;
BA_REL_ "GenSigTimeoutTime" BU_SG_REL_ CGW SG_ 1496 CR_BMS_DisplaySOC 2000;
BA_REL_ "GenSigTimeoutTime" BU_SG_REL_ H_U SG_ 1496 CR_BMS_DisplaySOC 2000;
BA_REL_ "GenSigTimeoutTime" BU_SG_REL_ TMU SG_ 1496 CR_BMS_DisplaySOC 2000;
BA_REL_ "GenSigTimeoutTime" BU_SG_REL_ TMU SG_ 1496 CR_Bms_Inlet_C 2000;
BA_REL_ "GenSigTimeoutTime" BU_SG_REL_ TMU SG_ 1496 CR_Bms_ObcCmdCurrt_A 2000;
BA_REL_ "GenSigTimeoutTime" BU_SG_REL_ CGW SG_ 1496 CR_Bms_ScChgRemainedTime_min 2000;
BA_REL_ "GenSigTimeoutTime" BU_SG_REL_ H_U SG_ 1496 CR_Bms_ScChgRemainedTime_min 2000;
BA_REL_ "GenSigTimeoutTime" BU_SG_REL_ TMU SG_ 1496 CR_Bms_ScChgRemainedTime_min 2000;
BA_REL_ "GenSigTimeoutTime" BU_SG_REL_ TMU SG_ 1496 CR_Bms_BatTotV_V 2000;
BA_REL_ "GenSigTimeoutTime" BU_SG_REL_ CGW SG_ 1497 CF_Vcu_SmartEcoDisp 2000;
BA_REL_ "GenSigTimeoutTime" BU_SG_REL_ vBDM SG_ 1497 CF_Vcu_SmartEcoDisp 2000;
BA_REL_ "GenSigTimeoutTime" BU_SG_REL_ CGW SG_ 1497 CR_Vcu_RegenRangeAddSet 2000;
BA_REL_ "GenSigTimeoutTime" BU_SG_REL_ CGW SG_ 1497 CR_Vcu_SmartEcoRng 2000;
BA_REL_ "GenSigTimeoutTime" BU_SG_REL_ CGW SG_ 1497 CR_Vcu_SmartEcoLvl 2000;
BA_REL_ "GenSigTimeoutTime" BU_SG_REL_ CGW SG_ 1497 CR_Vcu_RegenRangeAdd 2000;
BA_REL_ "GenSigTimeoutTime" BU_SG_REL_ CGW SG_ 1497 CF_Vcu_WarnMsg 2000;
BA_REL_ "GenSigTimeoutTime" BU_SG_REL_ CGW SG_ 1497 CF_Vcu_FueEffStat 2000;
BA_REL_ "GenSigTimeoutTime" BU_SG_REL_ CGW SG_ 1497 CF_Vcu_FueEffStatBox 2000;
BA_REL_ "GenSigTimeoutTime" BU_SG_REL_ CGW SG_ 1497 CR_Vcu_HighFueEff_Pc 2000;
BA_REL_ "GenSigTimeoutTime" BU_SG_REL_ CGW SG_ 1497 CR_Vcu_NorFueEff_Pc 2000;
BA_REL_ "GenSigTimeoutTime" BU_SG_REL_ CGW SG_ 1497 CR_Vcu_LowFueEff_Pc 2000;
BA_REL_ "GenSigTimeoutTime" BU_SG_REL_ CGW SG_ 1497 CF_Vcu_StartKeyWarnMsg 0;
BA_REL_ "GenSigTimeoutTime" BU_SG_REL_ OLDC SG_ 1497 CR_Vcu_LdcVolCmd_Ls_V 2000;
BA_REL_ "GenSigTimeoutTime" BU_SG_REL_ BMS SG_ 1477 CF_Bcf_PwmErr_flag 2000;
BA_REL_ "GenSigTimeoutTime" BU_SG_REL_ BMS SG_ 1477 CF_Bcf_GateErr_flag 2000;
BA_REL_ "GenSigTimeoutTime" BU_SG_REL_ BMS SG_ 1477 CF_Bcf_LowCurr_flag 2000;
BA_REL_ "GenSigTimeoutTime" BU_SG_REL_ BMS SG_ 1477 CF_Bcf_MotStalled_flag 2000;
BA_REL_ "GenSigTimeoutTime" BU_SG_REL_ BMS SG_ 1477 CF_Bcf_OverCurr_flag 2000;
BA_REL_ "GenSigTimeoutTime" BU_SG_REL_ BMS SG_ 1477 CF_Bcf_UnderVolt_flag 2000;
BA_REL_ "GenSigTimeoutTime" BU_SG_REL_ BMS SG_ 1477 CF_Bcf_OverVolt_flag 2000;
BA_REL_ "GenSigTimeoutTime" BU_SG_REL_ BMS SG_ 1477 CR_Bcf_FanFeedbackFreq 2000;
BA_REL_ "GenSigTimeoutTime" BU_SG_REL_ BMS SG_ 1477 CR_Bcf_AuxVolt 2000;
BA_REL_ "GenSigTimeoutTime" BU_SG_REL_ BMS SG_ 1477 CR_Bcf_CurrRms 2000;
BA_REL_ "GenSigTimeoutTime" BU_SG_REL_ BMS SG_ 1477 CR_Bcf_MotRpm 2000;
BA_REL_ "GenSigTimeoutTime" BU_SG_REL_ BMS SG_ 1477 CR_Bcf_ProgVer 2000;
BA_REL_ "GenSigTimeoutTime" BU_SG_REL_ BMS SG_ 1477 CR_Bcf_AliveCnt 2000;
BA_REL_ "GenSigTimeoutTime" BU_SG_REL_ BMS SG_ 1477 CR_Bcf_CheckSum 2000;
BA_REL_ "GenSigTimeoutTime" BU_SG_REL_ OBC SG_ 1474 CF_Clu_InletAutoLockNValueSet 0;
BA_REL_ "GenSigTimeoutTime" BU_SG_REL_ CGW SG_ 1245 CR_Bms_RadFanOperReq_rpm 2000;
BA_REL_ "GenSigTimeoutTime" BU_SG_REL_ MCU SG_ 1245 CR_Bms_RadFanOperReq_rpm 2000;
BA_REL_ "GenSigTimeoutTime" BU_SG_REL_ vBDM SG_ 1245 CR_Bms_RadFanOperReq_rpm 2000;
BA_REL_ "GenSigTimeoutTime" BU_SG_REL_ AAF SG_ 1245 CR_Bms_ChiOperReq_level 2000;
BA_REL_ "GenSigTimeoutTime" BU_SG_REL_ DATC SG_ 1245 CR_Bms_ChiOperReq_level 2000;
BA_REL_ "GenSigTimeoutTime" BU_SG_REL_ Dummy SG_ 1245 CR_Bms_3wayVav1_CtrlPWM 2000;
BA_REL_ "GenSigTimeoutTime" BU_SG_REL_ Dummy SG_ 1245 CR_Bms_3wayVav2_CtrlPWM 2000;
BA_REL_ "GenSigTimeoutTime" BU_SG_REL_ Dummy SG_ 1245 CR_Bms_3wayVav1_Feedback 2000;
BA_REL_ "GenSigTimeoutTime" BU_SG_REL_ Dummy SG_ 1245 CR_Bms_3wayVav2_Feedback 2000;
BA_REL_ "GenSigTimeoutTime" BU_SG_REL_ AAF SG_ 1245 CR_Bms_3wayVav_CtrlMode 2000;
BA_REL_ "GenSigTimeoutTime" BU_SG_REL_ DATC SG_ 1245 CR_Bms_3wayVav_CtrlMode 2000;
BA_REL_ "GenSigTimeoutTime" BU_SG_REL_ Dummy SG_ 1245 CR_Bms_3wayVav_CtrlMode 2000;
BA_REL_ "GenSigTimeoutTime" BU_SG_REL_ CGW SG_ 1245 CF_Bms_WCS_HeaterRlyOnStat 2000;
BA_REL_ "GenSigTimeoutTime" BU_SG_REL_ Dummy SG_ 1245 CF_Bms_WCS_HeaterRlyOnStat 2000;
BA_REL_ "GenSigTimeoutTime" BU_SG_REL_ CGW SG_ 1245 CF_Bms_CoolantShortage 2000;
BA_REL_ "GenSigTimeoutTime" BU_SG_REL_ Dummy SG_ 1245 CF_Bms_EwpDiagModeEna 2000;
BA_REL_ "GenSigTimeoutTime" BU_SG_REL_ EWP2 SG_ 1245 CF_Bms_EwpDiagModeEna 2000;
BA_REL_ "GenSigTimeoutTime" BU_SG_REL_ MCU SG_ 1245 CR_Bms_EWPOperRpmforMCU 2000;
BA_REL_ "GenSigTimeoutTime" BU_SG_REL_ VCU SG_ 1245 CR_Bms_EWPOperRpmforMCU 2000;
BA_REL_ "GenSigTimeoutTime" BU_SG_REL_ EWP2 SG_ 1246 CR_Bms_EwpOperReq_rpm 2000;
BA_REL_ "GenSigTimeoutTime" BU_SG_REL_ Dummy SG_ 1246 CR_Bms_WCS_HeaterTemp_C 2000;
BA_REL_ "GenSigTimeoutTime" BU_SG_REL_ CGW SG_ 1246 CR_Bms_WCS_InletTemp_C 2000;
BA_REL_ "GenSigTimeoutTime" BU_SG_REL_ Dummy SG_ 1246 CR_Bms_WCS_InletTemp_C 2000;
BA_REL_ "GenSigTimeoutTime" BU_SG_REL_ vBDM SG_ 1246 CR_Bms_WCS_InletTemp_C 2000;
BA_REL_ "GenSigTimeoutTime" BU_SG_REL_ Dummy SG_ 1246 CR_Bms_PRATemp2_C 2000;
BA_REL_ "GenSigTimeoutTime" BU_SG_REL_ DATC SG_ 1246 CR_Bms_RadiOutTemp_C 2000;
BA_REL_ "GenSigTimeoutTime" BU_SG_REL_ Dummy SG_ 1246 CR_Bms_RadiOutTemp_C 2000;
BA_REL_ "GenSigTimeoutTime" BU_SG_REL_ DATC SG_ 1246 CF_Bms_FatcWHRLoopInh 2000;
BA_REL_ "GenSigTimeoutTime" BU_SG_REL_ Dummy SG_ 1246 CR_Bms_3WayVav_CtrlMode2 2000;
BA_REL_ "GenSigTimeoutTime" BU_SG_REL_ MCU SG_ 1246 CR_Bms_3WayVav_CtrlMode2 2000;
BA_REL_ "GenSigTimeoutTime" BU_SG_REL_ OBC SG_ 1246 CR_Bms_3WayVav_CtrlMode2 2000;
BA_REL_ "GenSigTimeoutTime" BU_SG_REL_ MCU SG_ 1246 CF_Bms_BTMSdiag_flag 2000;
BA_REL_ "GenSigTimeoutTime" BU_SG_REL_ VCU SG_ 1246 CF_Bms_BTMSdiag_flag 2000;
BA_REL_ "GenSigTimeoutTime" BU_SG_REL_ Dummy SG_ 1246 CR_Bms_BTMS_SubCode1 2000;
BA_REL_ "GenSigTimeoutTime" BU_SG_REL_ Dummy SG_ 1246 CR_Bms_BTMS_Subcode2 2000;
BA_REL_ "GenSigTimeoutTime" BU_SG_REL_ Dummy SG_ 1246 CR_Bms_BTMS_Subcode3 2000;
BA_REL_ "GenSigTimeoutTime" BU_SG_REL_ MCU SG_ 1246 CR_Bms_RadFanOperReq_duty 2000;
BA_REL_ "GenSigTimeoutTime" BU_SG_REL_ VCU SG_ 1246 CR_Bms_RadFanOperReq_duty 2000;
BA_REL_ "GenSigTimeoutTime" BU_SG_REL_ CGW SG_ 1484 DATC_ModeDisp 5000;
BA_REL_ "GenSigTimeoutTime" BU_SG_REL_ TMU SG_ 1484 DATC_ModeDisp 5000;
BA_REL_ "GenSigTimeoutTime" BU_SG_REL_ CGW SG_ 1484 DATC_TempUnit 5000;
BA_REL_ "GenSigTimeoutTime" BU_SG_REL_ H_U SG_ 1484 DATC_TempUnit 5000;
BA_REL_ "GenSigTimeoutTime" BU_SG_REL_ TMU SG_ 1484 DATC_TempUnit 5000;
BA_REL_ "GenSigTimeoutTime" BU_SG_REL_ VCU SG_ 1484 DATC_TempUnit 5000;
BA_REL_ "GenSigTimeoutTime" BU_SG_REL_ CGW SG_ 1484 DATC_SepzoneDisp 5000;
BA_REL_ "GenSigTimeoutTime" BU_SG_REL_ TMU SG_ 1484 DATC_SepzoneDisp 5000;
BA_REL_ "GenSigTimeoutTime" BU_SG_REL_ CGW SG_ 1484 DATC_AutoDisp 5000;
BA_REL_ "GenSigTimeoutTime" BU_SG_REL_ TMU SG_ 1484 DATC_AutoDisp 5000;
BA_REL_ "GenSigTimeoutTime" BU_SG_REL_ VCU SG_ 1484 DATC_AutoDisp 5000;
BA_REL_ "GenSigTimeoutTime" BU_SG_REL_ CGW SG_ 1484 DATC_IntakeDisp 5000;
BA_REL_ "GenSigTimeoutTime" BU_SG_REL_ TMU SG_ 1484 DATC_IntakeDisp 5000;
BA_REL_ "GenSigTimeoutTime" BU_SG_REL_ CGW SG_ 1484 DATC_ChangeReqDisp 5000;
BA_REL_ "GenSigTimeoutTime" BU_SG_REL_ TMU SG_ 1484 DATC_ChangeReqDisp 5000;
BA_REL_ "GenSigTimeoutTime" BU_SG_REL_ CGW SG_ 1484 CF_Datc_Text_PopupReq 1500;
BA_REL_ "GenSigTimeoutTime" BU_SG_REL_ CGW SG_ 1484 DATC_AcDisp 5000;
BA_REL_ "GenSigTimeoutTime" BU_SG_REL_ TMU SG_ 1484 DATC_AcDisp 5000;
BA_REL_ "GenSigTimeoutTime" BU_SG_REL_ VCU SG_ 1484 DATC_AcDisp 5000;
BA_REL_ "GenSigTimeoutTime" BU_SG_REL_ CGW SG_ 1484 DATC_AqsDisp 5000;
BA_REL_ "GenSigTimeoutTime" BU_SG_REL_ TMU SG_ 1484 DATC_AqsDisp 5000;
BA_REL_ "GenSigTimeoutTime" BU_SG_REL_ CGW SG_ 1484 DATC_ClimateScnDisp 5000;
BA_REL_ "GenSigTimeoutTime" BU_SG_REL_ TMU SG_ 1484 DATC_ClimateScnDisp 5000;
BA_REL_ "GenSigTimeoutTime" BU_SG_REL_ CGW SG_ 1484 DATC_AirCleaningSystemStatus 5000;
BA_REL_ "GenSigTimeoutTime" BU_SG_REL_ CGW SG_ 1484 DATC_SyncDisp 5000;
BA_REL_ "GenSigTimeoutTime" BU_SG_REL_ TMU SG_ 1484 DATC_SyncDisp 5000;
BA_REL_ "GenSigTimeoutTime" BU_SG_REL_ CGW SG_ 1484 CF_Datc_BlowerAutoDisp 5000;
BA_REL_ "GenSigTimeoutTime" BU_SG_REL_ CGW SG_ 1484 DATC_OpSts 5000;
BA_REL_ "GenSigTimeoutTime" BU_SG_REL_ TMU SG_ 1484 DATC_OpSts 5000;
BA_REL_ "GenSigTimeoutTime" BU_SG_REL_ CGW SG_ 1484 DATC_RearManual 5000;
BA_REL_ "GenSigTimeoutTime" BU_SG_REL_ TMU SG_ 1484 DATC_RearManual 5000;
BA_REL_ "GenSigTimeoutTime" BU_SG_REL_ CGW SG_ 1484 DATC_HeatDisp 5000;
BA_REL_ "GenSigTimeoutTime" BU_SG_REL_ TMU SG_ 1484 DATC_HeatDisp 5000;
BA_REL_ "GenSigTimeoutTime" BU_SG_REL_ VCU SG_ 1484 DATC_HeatDisp 5000;
BA_REL_ "GenSigTimeoutTime" BU_SG_REL_ CGW SG_ 1484 DATC_FrDefLed 5000;
BA_REL_ "GenSigTimeoutTime" BU_SG_REL_ H_U SG_ 1484 DATC_FrDefLed 5000;
BA_REL_ "GenSigTimeoutTime" BU_SG_REL_ TMU SG_ 1484 DATC_FrDefLed 5000;
BA_REL_ "GenSigTimeoutTime" BU_SG_REL_ VCU SG_ 1484 DATC_FrDefLed 5000;
BA_REL_ "GenSigTimeoutTime" BU_SG_REL_ CGW SG_ 1484 CF_Datc_ModAutoDisp 5000;
BA_REL_ "GenSigTimeoutTime" BU_SG_REL_ CGW SG_ 1484 DATC_AutoDefogBlink 5000;
BA_REL_ "GenSigTimeoutTime" BU_SG_REL_ TMU SG_ 1484 DATC_AutoDefogBlink 5000;
BA_REL_ "GenSigTimeoutTime" BU_SG_REL_ CGW SG_ 1484 CF_Datc_IntakeStatus 1500;
BA_REL_ "GenSigTimeoutTime" BU_SG_REL_ CGW SG_ 1484 DATC_IonClean 5000;
BA_REL_ "GenSigTimeoutTime" BU_SG_REL_ TMU SG_ 1484 DATC_IonClean 5000;
BA_REL_ "GenSigTimeoutTime" BU_SG_REL_ CGW SG_ 1484 DATC_CO2Warning 5000;
BA_REL_ "GenSigTimeoutTime" BU_SG_REL_ TMU SG_ 1484 DATC_CO2Warning 5000;
BA_REL_ "GenSigTimeoutTime" BU_SG_REL_ CGW SG_ 1484 DATC_SubBlowerDisp 5000;
BA_REL_ "GenSigTimeoutTime" BU_SG_REL_ TMU SG_ 1484 DATC_SubBlowerDisp 5000;
BA_REL_ "GenSigTimeoutTime" BU_SG_REL_ CGW SG_ 1484 DATC_BeepReq 5000;
BA_REL_ "GenSigTimeoutTime" BU_SG_REL_ TMU SG_ 1484 DATC_BeepReq 5000;
BA_REL_ "GenSigTimeoutTime" BU_SG_REL_ CGW SG_ 1484 DATC_MainBlowerDisp 5000;
BA_REL_ "GenSigTimeoutTime" BU_SG_REL_ H_U SG_ 1484 DATC_MainBlowerDisp 5000;
BA_REL_ "GenSigTimeoutTime" BU_SG_REL_ TMU SG_ 1484 DATC_MainBlowerDisp 5000;
BA_REL_ "GenSigTimeoutTime" BU_SG_REL_ VCU SG_ 1484 DATC_MainBlowerDisp 5000;
BA_REL_ "GenSigTimeoutTime" BU_SG_REL_ CGW SG_ 1484 DATC_PsModeDisp 5000;
BA_REL_ "GenSigTimeoutTime" BU_SG_REL_ TMU SG_ 1484 DATC_PsModeDisp 5000;
BA_REL_ "GenSigTimeoutTime" BU_SG_REL_ CGW SG_ 1483 CR_Datc_DrTempDispC 5000;
BA_REL_ "GenSigTimeoutTime" BU_SG_REL_ H_U SG_ 1483 CR_Datc_DrTempDispC 5000;
BA_REL_ "GenSigTimeoutTime" BU_SG_REL_ TMU SG_ 1483 CR_Datc_DrTempDispC 5000;
BA_REL_ "GenSigTimeoutTime" BU_SG_REL_ VCU SG_ 1483 CR_Datc_DrTempDispC 5000;
BA_REL_ "GenSigTimeoutTime" BU_SG_REL_ vBDM SG_ 1483 CR_Datc_DrTempDispC 5000;
BA_REL_ "GenSigTimeoutTime" BU_SG_REL_ CGW SG_ 1483 CR_Datc_DrTempDispF 5000;
BA_REL_ "GenSigTimeoutTime" BU_SG_REL_ H_U SG_ 1483 CR_Datc_DrTempDispF 5000;
BA_REL_ "GenSigTimeoutTime" BU_SG_REL_ TMU SG_ 1483 CR_Datc_DrTempDispF 5000;
BA_REL_ "GenSigTimeoutTime" BU_SG_REL_ VCU SG_ 1483 CR_Datc_DrTempDispF 5000;
BA_REL_ "GenSigTimeoutTime" BU_SG_REL_ CGW SG_ 1483 CR_Datc_PsTempDispC 5000;
BA_REL_ "GenSigTimeoutTime" BU_SG_REL_ TMU SG_ 1483 CR_Datc_PsTempDispC 5000;
BA_REL_ "GenSigTimeoutTime" BU_SG_REL_ CGW SG_ 1483 CR_Datc_PsTempDispF 5000;
BA_REL_ "GenSigTimeoutTime" BU_SG_REL_ TMU SG_ 1483 CR_Datc_PsTempDispF 5000;
BA_REL_ "GenSigTimeoutTime" BU_SG_REL_ CGW SG_ 1483 CF_DATC_TempDisp_Sts 5000;
BA_REL_ "GenSigTimeoutTime" BU_SG_REL_ H_U SG_ 1483 CF_DATC_TempDisp_Sts 5000;
BA_REL_ "GenSigTimeoutTime" BU_SG_REL_ TMU SG_ 1483 CF_DATC_TempDisp_Sts 5000;
BA_REL_ "GenSigTimeoutTime" BU_SG_REL_ CGW SG_ 1483 CF_Datc_DefLogic_USM_State 5000;
BA_REL_ "GenSigTimeoutTime" BU_SG_REL_ CGW SG_ 1483 CF_Datc_AutoFresh_USM_State 5000;
BA_REL_ "GenSigTimeoutTime" BU_SG_REL_ CGW SG_ 1483 DATC_AutoArClnUSMState 5000;
BA_REL_ "GenSigTimeoutTime" BU_SG_REL_ CGW SG_ 1483 CR_Datc_RearDrTempDispC 5000;
BA_REL_ "GenSigTimeoutTime" BU_SG_REL_ TMU SG_ 1483 CR_Datc_RearDrTempDispC 5000;
BA_REL_ "GenSigTimeoutTime" BU_SG_REL_ CGW SG_ 1483 CR_Datc_RearDrTempDispF 5000;
BA_REL_ "GenSigTimeoutTime" BU_SG_REL_ TMU SG_ 1483 CR_Datc_RearDrTempDispF 5000;
BA_REL_ "GenSigTimeoutTime" BU_SG_REL_ CGW SG_ 1483 CF_Datc_Option3 5000;
BA_REL_ "GenSigTimeoutTime" BU_SG_REL_ CGW SG_ 1482 CF_Datc_Type 5000;
BA_REL_ "GenSigTimeoutTime" BU_SG_REL_ TMU SG_ 1482 CF_Datc_Type 5000;
BA_REL_ "GenSigTimeoutTime" BU_SG_REL_ CGW SG_ 1482 CF_Datc_Option5 5000;
BA_REL_ "GenSigTimeoutTime" BU_SG_REL_ CGW SG_ 1482 CR_Datc_OutTempC 5000;
BA_REL_ "GenSigTimeoutTime" BU_SG_REL_ TMU SG_ 1482 CR_Datc_OutTempC 5000;
BA_REL_ "GenSigTimeoutTime" BU_SG_REL_ CGW SG_ 1482 CR_Datc_OutTempF 5000;
BA_REL_ "GenSigTimeoutTime" BU_SG_REL_ TMU SG_ 1482 CR_Datc_OutTempF 5000;
BA_REL_ "GenSigTimeoutTime" BU_SG_REL_ CGW SG_ 1482 CR_NomalClimateLimitStatus 5000;
BA_REL_ "GenSigTimeoutTime" BU_SG_REL_ VCU SG_ 1482 CR_NomalClimateLimitStatus 5000;
BA_REL_ "GenSigTimeoutTime" BU_SG_REL_ CGW SG_ 1482 CR_SportClimateLimitStatus 5000;
BA_REL_ "GenSigTimeoutTime" BU_SG_REL_ VCU SG_ 1482 CR_SportClimateLimitStatus 5000;
BA_REL_ "GenSigTimeoutTime" BU_SG_REL_ CGW SG_ 1482 CR_EcoClimateLimitStatus 5000;
BA_REL_ "GenSigTimeoutTime" BU_SG_REL_ VCU SG_ 1482 CR_EcoClimateLimitStatus 5000;
BA_REL_ "GenSigTimeoutTime" BU_SG_REL_ CGW SG_ 1482 CR_Datc_ClimateLimit_OpSts 5000;
BA_REL_ "GenSigTimeoutTime" BU_SG_REL_ VCU SG_ 1482 CR_Datc_ClimateLimit_OpSts 5000;
BA_REL_ "GenSigTimeoutTime" BU_SG_REL_ CGW SG_ 1482 CF_Datc_Option1 5000;
BA_REL_ "GenSigTimeoutTime" BU_SG_REL_ TMU SG_ 1482 CF_Datc_Option1 5000;
BA_REL_ "GenSigTimeoutTime" BU_SG_REL_ CGW SG_ 1482 CF_Datc_Option2 5000;
BA_REL_ "GenSigTimeoutTime" BU_SG_REL_ TMU SG_ 1482 CF_Datc_Option2 5000;
BA_REL_ "GenSigTimeoutTime" BU_SG_REL_ CGW SG_ 1482 CF_Datc_Option4 0;
BA_REL_ "GenSigTimeoutTime" BU_SG_REL_ BMS SG_ 1481 CF_Bcf_BmsCanTimeOut_flag 2000;
BA_REL_ "GenSigTimeoutTime" BU_SG_REL_ BMS SG_ 1481 CF_Bcf_CanBusOff_flag 2000;
BA_REL_ "GenSigTimeoutTime" BU_SG_REL_ BMS SG_ 1481 CF_Bcf_OverTemp_flag 2000;
BA_REL_ "GenSigTimeoutTime" BU_SG_REL_ BMS SG_ 1481 CF_Bcf_HallSensorErr_Flag 2000;
BA_REL_ "GenSigTimeoutTime" BU_SG_REL_ BMS SG_ 1481 CF_Bcf_RpmErr_Flag 2000;
BA_REL_ "GenSigTimeoutTime" BU_SG_REL_ BMS SG_ 1481 CF_Bcf_CurrLimit_Flag 2000;
BA_REL_ "GenSigTimeoutTime" BU_SG_REL_ BMS SG_ 1481 CF_Bcf_CurrSensorErr_Flag 2000;
BA_REL_ "GenSigTimeoutTime" BU_SG_REL_ BMS SG_ 1481 CF_Bcf_MotStalledRetry_Flag 2000;
BA_REL_ "GenSigTimeoutTime" BU_SG_REL_ BMS SG_ 1481 CR_Bcf_PwmDutybyCan 2000;
BA_REL_ "GenSigTimeoutTime" BU_SG_REL_ BMS SG_ 1481 CR_Bcf_PwmDutybyWire 2000;
BA_REL_ "GenSigTimeoutTime" BU_SG_REL_ BMS SG_ 1481 CR_Bcf_MotStatus 0;
BA_REL_ "GenSigTimeoutTime" BU_SG_REL_ AAF SG_ 1525 CF_Datc_AcnReqSwi 2000;
BA_REL_ "GenSigTimeoutTime" BU_SG_REL_ TMU SG_ 1525 CF_Datc_AcnReqSwi 2000;
BA_REL_ "GenSigTimeoutTime" BU_SG_REL_ VCU SG_ 1525 CF_Datc_AcnReqSwi 2000;
BA_REL_ "GenSigTimeoutTime" BU_SG_REL_ BMS SG_ 1525 CF_Datc_BlrOn 2000;
BA_REL_ "GenSigTimeoutTime" BU_SG_REL_ CGW SG_ 1525 CF_Datc_BlrOn 2000;
BA_REL_ "GenSigTimeoutTime" BU_SG_REL_ LDC SG_ 1525 CF_Datc_BlrOn 2000;
BA_REL_ "GenSigTimeoutTime" BU_SG_REL_ TMU SG_ 1525 CF_Datc_BlrOn 2000;
BA_REL_ "GenSigTimeoutTime" BU_SG_REL_ VCU SG_ 1525 CF_Datc_BlrOn 2000;
BA_REL_ "GenSigTimeoutTime" BU_SG_REL_ vBDM SG_ 1525 CF_Datc_BlrOn 2000;
BA_REL_ "GenSigTimeoutTime" BU_SG_REL_ TMU SG_ 1525 CF_Datc_PtcOnReq 2000;
BA_REL_ "GenSigTimeoutTime" BU_SG_REL_ VCU SG_ 1525 CF_Datc_PtcOnReq 2000;
BA_REL_ "GenSigTimeoutTime" BU_SG_REL_ LDC SG_ 1525 CF_Datc_AcnCompOperStat 2000;
BA_REL_ "GenSigTimeoutTime" BU_SG_REL_ MCU SG_ 1525 CF_Datc_AcnCompOperStat 2000;
BA_REL_ "GenSigTimeoutTime" BU_SG_REL_ TMU SG_ 1525 CF_Datc_AcnCompOperStat 2000;
BA_REL_ "GenSigTimeoutTime" BU_SG_REL_ VCU SG_ 1525 CF_Datc_AcnCompOperStat 2000;
BA_REL_ "GenSigTimeoutTime" BU_SG_REL_ LDC SG_ 1525 CF_Datc_PTCOperStat 2000;
BA_REL_ "GenSigTimeoutTime" BU_SG_REL_ TMU SG_ 1525 CF_Datc_PTCOperStat 2000;
BA_REL_ "GenSigTimeoutTime" BU_SG_REL_ VCU SG_ 1525 CF_Datc_PTCOperStat 2000;
BA_REL_ "GenSigTimeoutTime" BU_SG_REL_ LDC SG_ 1525 CF_Datc_BlwrMax 2000;
BA_REL_ "GenSigTimeoutTime" BU_SG_REL_ TMU SG_ 1525 CF_Datc_BlwrMax 2000;
BA_REL_ "GenSigTimeoutTime" BU_SG_REL_ TMU SG_ 1525 CR_Datc_AcnComMaxReq_W 2000;
BA_REL_ "GenSigTimeoutTime" BU_SG_REL_ VCU SG_ 1525 CR_Datc_AcnComMaxReq_W 2000;
BA_REL_ "GenSigTimeoutTime" BU_SG_REL_ AAF SG_ 1525 CR_Datc_AcnCompPwrCon_W 2000;
BA_REL_ "GenSigTimeoutTime" BU_SG_REL_ CGW SG_ 1525 CR_Datc_AcnCompPwrCon_W 2000;
BA_REL_ "GenSigTimeoutTime" BU_SG_REL_ TMU SG_ 1525 CR_Datc_AcnCompPwrCon_W 2000;
BA_REL_ "GenSigTimeoutTime" BU_SG_REL_ VCU SG_ 1525 CR_Datc_AcnCompPwrCon_W 2000;
BA_REL_ "GenSigTimeoutTime" BU_SG_REL_ AAF SG_ 1525 CR_Datc_AptVal_PSI 2000;
BA_REL_ "GenSigTimeoutTime" BU_SG_REL_ MCU SG_ 1525 CR_Datc_AptVal_PSI 2000;
BA_REL_ "GenSigTimeoutTime" BU_SG_REL_ TMU SG_ 1525 CR_Datc_AptVal_PSI 2000;
BA_REL_ "GenSigTimeoutTime" BU_SG_REL_ TMU SG_ 1525 CF_Datc_MsgCnt 2000;
BA_REL_ "GenSigTimeoutTime" BU_SG_REL_ VCU SG_ 1525 CF_Datc_MsgCnt 2000;
BA_REL_ "GenSigTimeoutTime" BU_SG_REL_ CGW SG_ 1525 CF_Datc_AcnCompFlt 2000;
BA_REL_ "GenSigTimeoutTime" BU_SG_REL_ H_U SG_ 1525 CF_Datc_AcnCompFlt 2000;
BA_REL_ "GenSigTimeoutTime" BU_SG_REL_ TMU SG_ 1525 CF_Datc_AcnCompFlt 2000;
BA_REL_ "GenSigTimeoutTime" BU_SG_REL_ VCU SG_ 1525 CF_Datc_AcnCompFlt 2000;
BA_REL_ "GenSigTimeoutTime" BU_SG_REL_ CGW SG_ 1525 CF_Datc_PTCFlt 2000;
BA_REL_ "GenSigTimeoutTime" BU_SG_REL_ H_U SG_ 1525 CF_Datc_PTCFlt 2000;
BA_REL_ "GenSigTimeoutTime" BU_SG_REL_ TMU SG_ 1525 CF_Datc_PTCFlt 2000;
BA_REL_ "GenSigTimeoutTime" BU_SG_REL_ VCU SG_ 1525 CF_Datc_PTCFlt 2000;
BA_REL_ "GenSigTimeoutTime" BU_SG_REL_ MCU SG_ 1525 CF_Datc_WaterValve_Status 2000;
BA_REL_ "GenSigTimeoutTime" BU_SG_REL_ TMU SG_ 1525 CF_Datc_WaterValve_Status 2000;
BA_REL_ "GenSigTimeoutTime" BU_SG_REL_ TMU SG_ 1525 CF_Datc_CompType 2000;
BA_REL_ "GenSigTimeoutTime" BU_SG_REL_ VCU SG_ 1525 CF_Datc_CompType 2000;
BA_REL_ "GenSigTimeoutTime" BU_SG_REL_ BMS SG_ 1525 CF_Datc_HvIntlockReq 2000;
BA_REL_ "GenSigTimeoutTime" BU_SG_REL_ LDC SG_ 1525 CF_Datc_HvIntlockReq 2000;
BA_REL_ "GenSigTimeoutTime" BU_SG_REL_ MCU SG_ 1525 CF_Datc_HvIntlockReq 2000;
BA_REL_ "GenSigTimeoutTime" BU_SG_REL_ OBC SG_ 1525 CF_Datc_HvIntlockReq 2000;
BA_REL_ "GenSigTimeoutTime" BU_SG_REL_ TMU SG_ 1525 CF_Datc_HvIntlockReq 2000;
BA_REL_ "GenSigTimeoutTime" BU_SG_REL_ TMU SG_ 1525 CF_Datc_HeatPumpType 2000;
BA_REL_ "GenSigTimeoutTime" BU_SG_REL_ VCU SG_ 1525 CF_Datc_HeatPumpType 2000;
BA_REL_ "GenSigTimeoutTime" BU_SG_REL_ TMU SG_ 1525 CF_Datc_PTCType 2000;
BA_REL_ "GenSigTimeoutTime" BU_SG_REL_ VCU SG_ 1525 CF_Datc_PTCType 2000;
BA_REL_ "GenSigTimeoutTime" BU_SG_REL_ MCU SG_ 1525 CF_Datc_HVCompInterlock 2000;
BA_REL_ "GenSigTimeoutTime" BU_SG_REL_ TMU SG_ 1525 CF_Datc_HVCompInterlock 2000;
BA_REL_ "GenSigTimeoutTime" BU_SG_REL_ VCU SG_ 1525 CF_Datc_HVCompInterlock 2000;
BA_REL_ "GenSigTimeoutTime" BU_SG_REL_ MCU SG_ 1525 CF_Datc_HVPtcInterlock 2000;
BA_REL_ "GenSigTimeoutTime" BU_SG_REL_ TMU SG_ 1525 CF_Datc_HVPtcInterlock 2000;
BA_REL_ "GenSigTimeoutTime" BU_SG_REL_ VCU SG_ 1525 CF_Datc_HVPtcInterlock 2000;
BA_REL_ "GenSigTimeoutTime" BU_SG_REL_ BMS SG_ 1525 CR_Datc_OutTempSnr_C 2000;
BA_REL_ "GenSigTimeoutTime" BU_SG_REL_ CGW SG_ 1525 CR_Datc_OutTempSnr_C 2000;
BA_REL_ "GenSigTimeoutTime" BU_SG_REL_ LDC SG_ 1525 CR_Datc_OutTempSnr_C 2000;
BA_REL_ "GenSigTimeoutTime" BU_SG_REL_ OBC SG_ 1525 CR_Datc_OutTempSnr_C 2000;
BA_REL_ "GenSigTimeoutTime" BU_SG_REL_ TMU SG_ 1525 CR_Datc_OutTempSnr_C 2000;
BA_REL_ "GenSigTimeoutTime" BU_SG_REL_ iBAU SG_ 1525 CR_Datc_OutTempSnr_C 2000;
BA_REL_ "GenSigTimeoutTime" BU_SG_REL_ TMU SG_ 1525 CF_Datc_ChkSum 2000;
BA_REL_ "GenSigTimeoutTime" BU_SG_REL_ VCU SG_ 1525 CF_Datc_ChkSum 2000;
BA_REL_ "GenSigTimeoutTime" BU_SG_REL_ BMS SG_ 1526 CR_Datc_AcnCompSpdFB_rpm 2000;
BA_REL_ "GenSigTimeoutTime" BU_SG_REL_ CGW SG_ 1526 CR_Datc_AcnCompSpdFB_rpm 2000;
BA_REL_ "GenSigTimeoutTime" BU_SG_REL_ VCU SG_ 1526 CR_Datc_AcnCompSpdFB_rpm 2000;
BA_REL_ "GenSigTimeoutTime" BU_SG_REL_ vBDM SG_ 1526 CR_Datc_AcnCompSpdFB_rpm 2000;
BA_REL_ "GenSigTimeoutTime" BU_SG_REL_ VCU SG_ 1526 CF_Datc_AcnCompWaitCode 2000;
BA_REL_ "GenSigTimeoutTime" BU_SG_REL_ VCU SG_ 1526 CF_Datc_AcnCompSleepCode 2000;
BA_REL_ "GenSigTimeoutTime" BU_SG_REL_ VCU SG_ 1526 CF_Datc_AcnCompFaultCode 2000;
BA_REL_ "GenSigTimeoutTime" BU_SG_REL_ VCU SG_ 1526 CF_Datc_AcnCompLmtOperCode 2000;
BA_REL_ "GenSigTimeoutTime" BU_SG_REL_ VCU SG_ 1526 CF_Datc_PTCFltCode 2000;
BA_REL_ "GenSigTimeoutTime" BU_SG_REL_ VCU SG_ 1526 CR_Datc_PTCMaxReq_W 2000;
BA_REL_ "GenSigTimeoutTime" BU_SG_REL_ CGW SG_ 1526 CR_Datc_PTCPwrCon_W 2000;
BA_REL_ "GenSigTimeoutTime" BU_SG_REL_ TMU SG_ 1526 CR_Datc_PTCPwrCon_W 2000;
BA_REL_ "GenSigTimeoutTime" BU_SG_REL_ VCU SG_ 1526 CR_Datc_PTCPwrCon_W 2000;
BA_REL_ "GenSigTimeoutTime" BU_SG_REL_ BMS SG_ 1252 CF_Ewp_FltStatus 2000;
BA_REL_ "GenSigTimeoutTime" BU_SG_REL_ MCU SG_ 1252 CF_Ewp_FltStatus 2000;
BA_REL_ "GenSigTimeoutTime" BU_SG_REL_ VCU SG_ 1252 CF_Ewp_FltStatus 2000;
BA_REL_ "GenSigTimeoutTime" BU_SG_REL_ BMS SG_ 1252 CF_Ewp_ProtectMode 2000;
BA_REL_ "GenSigTimeoutTime" BU_SG_REL_ BMS SG_ 1252 CR_Ewp_ActRotSpd_rpm 2000;
BA_REL_ "GenSigTimeoutTime" BU_SG_REL_ MCU SG_ 1252 CR_Ewp_ActRotSpd_rpm 2000;
BA_REL_ "GenSigTimeoutTime" BU_SG_REL_ VCU SG_ 1252 CR_Ewp_ActRotSpd_rpm 2000;
BA_REL_ "GenSigTimeoutTime" BU_SG_REL_ BMS SG_ 1252 CF_EWP_Version 2000;
BA_REL_ "GenSigTimeoutTime" BU_SG_REL_ CGW SG_ 1252 CF_EWP_Version 2000;
BA_REL_ "GenSigTimeoutTime" BU_SG_REL_ vBDM SG_ 1252 CF_EWP_Version 2000;
BA_REL_ "GenSigTimeoutTime" BU_SG_REL_ BMS SG_ 1252 Eeprom_Pop_Up_Short 2000;
BA_REL_ "GenSigTimeoutTime" BU_SG_REL_ BMS SG_ 1252 Eeprom_Pop_Up_Gduv 2000;
BA_REL_ "GenSigTimeoutTime" BU_SG_REL_ BMS SG_ 1252 Eeprom_Pop_Up_Phase_Open 2000;
BA_REL_ "GenSigTimeoutTime" BU_SG_REL_ BMS SG_ 1252 Eeprom_Pop_Up_Stalled 2000;
BA_REL_ "GenSigTimeoutTime" BU_SG_REL_ BMS SG_ 1252 Eeprom_Pop_Up_Lc 2000;
BA_REL_ "GenSigTimeoutTime" BU_SG_REL_ BMS SG_ 1252 Eeprom_Pop_Up_Oc 2000;
BA_REL_ "GenSigTimeoutTime" BU_SG_REL_ BMS SG_ 1252 Eeprom_Pop_Up_Lv 2000;
BA_REL_ "GenSigTimeoutTime" BU_SG_REL_ BMS SG_ 1252 Eeprom_Pop_Up_Hv 2000;
BA_REL_ "GenSigTimeoutTime" BU_SG_REL_ BMS SG_ 1252 CF_PWM_Duty_Ratio 2000;
BA_REL_ "GenSigTimeoutTime" BU_SG_REL_ BMS SG_ 1252 CF_Current_RMS 2000;
BA_REL_ "GenSigTimeoutTime" BU_SG_REL_ BMS SG_ 1252 CF_Short_Ouput_Circuit 2000;
BA_REL_ "GenSigTimeoutTime" BU_SG_REL_ BMS SG_ 1252 CF_Gduv 2000;
BA_REL_ "GenSigTimeoutTime" BU_SG_REL_ BMS SG_ 1252 CF_Low_Current 2000;
BA_REL_ "GenSigTimeoutTime" BU_SG_REL_ BMS SG_ 1252 CF_Over_Current 2000;
BA_REL_ "GenSigTimeoutTime" BU_SG_REL_ BMS SG_ 1252 CF_Low_Voltage 2000;
BA_REL_ "GenSigTimeoutTime" BU_SG_REL_ BMS SG_ 1252 CF_High_Voltage 2000;
BA_REL_ "GenSigTimeoutTime" BU_SG_REL_ BMS SG_ 1252 CF_Speed_Error 2000;
BA_REL_ "GenSigTimeoutTime" BU_SG_REL_ EWP SG_ 1527 CR_Datc_ReqEWPSpd_rpm 2000;
BA_REL_ "GenSigTimeoutTime" BU_SG_REL_ MCU SG_ 1527 CR_Datc_ReqEWPSpd_rpm 2000;
BA_REL_ "GenSigTimeoutTime" BU_SG_REL_ TMU SG_ 1527 CR_Datc_ReqEWPSpd_rpm 2000;
BA_REL_ "GenSigTimeoutTime" BU_SG_REL_ VCU SG_ 1527 CR_Datc_ReqEWPSpd_rpm 2000;
BA_REL_ "GenSigTimeoutTime" BU_SG_REL_ CGW SG_ 1527 CF_Datc_ServiceLamp 2000;
BA_REL_ "GenSigTimeoutTime" BU_SG_REL_ TMU SG_ 1527 CF_Datc_ServiceLamp 2000;
BA_REL_ "GenSigTimeoutTime" BU_SG_REL_ CGW SG_ 1527 CF_Datc_Controllable 2000;
BA_REL_ "GenSigTimeoutTime" BU_SG_REL_ TMU SG_ 1527 CF_Datc_Controllable 2000;
BA_REL_ "GenSigTimeoutTime" BU_SG_REL_ VCU SG_ 1527 CF_Datc_Controllable 2000;
BA_REL_ "GenSigTimeoutTime" BU_SG_REL_ AAF SG_ 1527 CF_Datc_Heatpump_Mode 2000;
BA_REL_ "GenSigTimeoutTime" BU_SG_REL_ TMU SG_ 1527 CF_Datc_Heatpump_Mode 2000;
BA_REL_ "GenSigTimeoutTime" BU_SG_REL_ VCU SG_ 1527 CF_Datc_Heatpump_Mode 2000;
BA_REL_ "GenSigTimeoutTime" BU_SG_REL_ TMU SG_ 1527 CF_Datc_PTCFailureCode 2000;
BA_REL_ "GenSigTimeoutTime" BU_SG_REL_ VCU SG_ 1527 CF_Datc_PTCFailureCode 2000;
BA_REL_ "GenSigTimeoutTime" BU_SG_REL_ BMS SG_ 1527 CF_Datc_CoolantValve_FltCode 2000;
BA_REL_ "GenSigTimeoutTime" BU_SG_REL_ MCU SG_ 1527 CF_Datc_CoolantValve_FltCode 2000;
BA_REL_ "GenSigTimeoutTime" BU_SG_REL_ TMU SG_ 1527 CF_Datc_CoolantValve_FltCode 2000;
BA_REL_ "GenSigTimeoutTime" BU_SG_REL_ VCU SG_ 1527 CF_Datc_CoolantValve_FltCode 2000;
BA_REL_ "GenSigTimeoutTime" BU_SG_REL_ TMU SG_ 1527 CF_Datc_RefValve_FltCode 2000;
BA_REL_ "GenSigTimeoutTime" BU_SG_REL_ VCU SG_ 1527 CF_Datc_RefValve_FltCode 2000;
BA_REL_ "GenSigTimeoutTime" BU_SG_REL_ AAF SG_ 1527 CR_Datc_OutTemp_C 2000;
BA_REL_ "GenSigTimeoutTime" BU_SG_REL_ CGW SG_ 1527 CR_Datc_OutTemp_C 2000;
BA_REL_ "GenSigTimeoutTime" BU_SG_REL_ EWP SG_ 1527 CR_Datc_OutTemp_C 2000;
BA_REL_ "GenSigTimeoutTime" BU_SG_REL_ MCU SG_ 1527 CR_Datc_OutTemp_C 2000;
BA_REL_ "GenSigTimeoutTime" BU_SG_REL_ TMU SG_ 1527 CR_Datc_OutTemp_C 2000;
BA_REL_ "GenSigTimeoutTime" BU_SG_REL_ VCU SG_ 1527 CR_Datc_OutTemp_C 2000;
BA_REL_ "GenSigTimeoutTime" BU_SG_REL_ iBAU SG_ 1527 CR_Datc_OutTemp_C 2000;
BA_REL_ "GenSigTimeoutTime" BU_SG_REL_ vBDM SG_ 1527 CR_Datc_OutTemp_C 2000;
BA_REL_ "GenSigTimeoutTime" BU_SG_REL_ BMS SG_ 1527 CR_Fatc_BatChiValve_Status 0;
BA_REL_ "GenSigTimeoutTime" BU_SG_REL_ BMS SG_ 1527 CR_Fatc_BatChiValve_FltCode 0;
BA_REL_ "GenSigTimeoutTime" BU_SG_REL_ BMS SG_ 1527 CR_Fatc_BatEvapValve_Status 0;
BA_REL_ "GenSigTimeoutTime" BU_SG_REL_ BMS SG_ 1527 CR_Fatc_BatEvapValve_FltCode 0;
BA_REL_ "GenSigTimeoutTime" BU_SG_REL_ MCU SG_ 1527 CR_Fatc_RadFanReq_Duty 0;
BA_REL_ "GenSigTimeoutTime" BU_SG_REL_ TMU SG_ 1527 CR_Fatc_RadFanReq_Duty 0;
BA_REL_ "GenSigTimeoutTime" BU_SG_REL_ VCU SG_ 1527 CR_Fatc_RadFanReq_Duty 0;
VAL_ 1301 CF_Clu_ADrUNValueSet 0 "Default" 1 "Off" 2 "Key Out On" 3 "Shift Lever On" 4 "Override" 5 "Invalid" ;
VAL_ 1301 CF_Clu_ADrLNValueSet 0 "Default" 1 "Off" 2 "Vehicle Speed On (15Km)" 3 "Shift Lever On" 4 "Invalid" ;
VAL_ 1301 CF_Clu_EscortHLNValueSet 0 "Default Value" 1 "Escort Off" 2 "Escort On" 3 "Invalid" ;
VAL_ 1301 CF_Clu_DoorLSNValueSet 0 "Off" 1 "Disable" 2 "Enable" 3 "Invalid" ;
VAL_ 1301 CF_Clu_PSMNValueSet 0 "Default Value" 1 "Off (Disable)" 2 "50mmOn (Enable)" 3 "75mmOn (Enable)" 4 "Reserved" 5 "Reserved" 6 "Reserved" 7 "Invalid" ;
VAL_ 1301 CF_Clu_TTUnlockNValueSet 0 "Default" 1 "Off" 2 "On" 3 "Invalid" ;
VAL_ 1301 CF_Clu_ATTurnNValueSet 0 "Default Value" 1 "Auto Triple Turn Off" 2 "Auto Triple Turn On" 3 "Invalid" ;
VAL_ 1301 CF_Clu_SCMNValueSet 0 "Default" 1 "Steering Off" 2 "Steering On" 3 "Invalid" ;
VAL_ 1301 CF_Clu_WlightNValueSet 0 "Default Value" 1 "Welcome Light Off" 2 "Welcome Light On" 3 "Invalid" ;
VAL_ 1301 CF_Clu_TempUnitNValueSet 0 "Off" 1 "Centigrade(¡É)" 2 "Fahrenheit(¢µ)" 3 "Invalid" ;
VAL_ 1301 CF_Clu_TrfChgSet 0 "Off" 1 "On" 2 "Invalid" 3 "Invalid" ;
VAL_ 1301 CF_Clu_OTTurnNValueSet 0 "Default" 1 "One Touch Turn Off" 2 "3 Flashing" 3 "5 Flashing" 4 "7 Flashing" 5 "Invalid" 6 "Reserved" 7 "Reserved" ;
VAL_ 1301 CF_Clu_LcaNValueSet 0 "Off" 1 "Disable" 2 "Enable" 3 "Invalid" ;
VAL_ 1301 CF_Clu_RctaNValueSet 0 "Off" 1 "Disable" 2 "Enable" 3 "Invalid" ;
VAL_ 1301 CF_Clu_RcwNValueSet 0 "Off" 1 "Disable" 2 "Enable" 3 "Invalid" ;
VAL_ 1301 CF_Clu_EcsOffNValueSet 0 "Off" 1 "Disable" 2 "Enable" 3 "Invalid" ;
VAL_ 1301 CF_Clu_SccNaviCrvNValueSet 0 "Default" 1 "Disable" 2 "Enable" 3 "Invalid" ;
VAL_ 1301 CF_Clu_SccNaviCamNValueSet 0 "Default" 1 "Disable" 2 "Enable" 3 "Invalid" ;
VAL_ 1301 CF_Clu_SccAebNValueSet 0 "Default" 1 "Disable" 2 "Enable" 3 "Invalid" ;
VAL_ 1301 CF_Clu_LkasModeNValueSet 0 "Default Value" 1 "LDW Mode" 2 "LKA Mode(Pre_Departure)" 3 "LKA Mode(Post_Departure)" ;
VAL_ 1301 CF_Clu_FcwNValueSet 0 "Default" 1 "Disable" 2 "Enable" 3 "Invalid" ;
VAL_ 1301 CF_Clu_PasSpkrLvNValueSet 0 "Default" 1 "Level 1" 2 "Level 2" 3 "Level 3" 4 "Reserved" 5 "Reserved" 6 "Reserved" 7 "Invalid (Error Value)" ;
VAL_ 1301 CF_Clu_SccDrvModeNValueSet 0 "Default" 1 "Slow" 2 "Normal" 3 "Fast" 4 "Reserved" 5 "Reserved" 6 "Reserved" 7 "Invalid" ;
VAL_ 1301 CF_Clu_HAnBNValueSet 0 "Default" 1 "Arm Disarm Buzzer Off" 2 "Arm Disarm Buzzer On" 3 "Invalid" ;
VAL_ 1301 CF_Clu_HfreeTrunkTgNValueSet 0 "Default" 1 "HandsFree Off" 2 "HandsFree On" 3 "Reserved" 4 "Invalid" ;
VAL_ 1049 PROLONG_Update 0 "False" 1 "True" ;
VAL_ 1049 PROLONG_Retransmission 0 "False" 1 "True" ;
VAL_ 1049 PROLONG_CountrolPoint 0 "False" 1 "True" ;
VAL_ 1049 PROLONG_ProfileType 0 "Invalid" 1 "Longitude" 2 "Latitude" 3 "Altitude" 4 "Control Point Longitude(Bezier)" 5 "Control Point Latitude(Bezier)" 6 "Control Point Altitude(Bezier)" 7 "Link Identifier" 8 "Traffic Sign" 9 "Reserved for standard type" 10 "Reserved for standard type" 11 "Reserved for standard type" 12 "Reserved for standard type" 13 "Reserved for standard type" 14 "Reserved for standard type" 15 "Reserved for standard type" 16 "Alert Information Spot" 17 "Reserved for system specific" 18 "Reserved for system specific" 19 "Reserved for system specific" 20 "Reserved for system specific" 21 "Reserved for system specific" 22 "Reserved for system specific" 23 "Reserved for system specific" 24 "Reserved for system specific" 25 "Reserved for system specific" 26 "Reserved for system specific" 27 "Reserved for system specific" 28 "Reserved for system specific" 29 "Reserved for system specific" 30 "Reserved for system specific" 31 "Reserved for system specific" ;
VAL_ 1049 PROLONG_PathIndex 0 "Unknown" 1 "Reserved" 2 "Reserved" 3 "Reserved" 4 "Reserved" 5 "Reserved" 6 "Reserved" 7 "Reserved" 8 "General Path Index" 9 "General Path Index" 10 "General Path Index" 11 "General Path Index" 12 "General Path Index" 13 "General Path Index" 14 "General Path Index" 15 "General Path Index" 16 "General Path Index" 17 "General Path Index" 18 "General Path Index" 19 "General Path Index" 20 "General Path Index" 21 "General Path Index" 22 "General Path Index" 23 "General Path Index" 24 "General Path Index" 25 "General Path Index" 26 "General Path Index" 27 "General Path Index" 28 "General Path Index" 29 "General Path Index" 30 "General Path Index" 31 "General Path Index" 32 "General Path Index" 33 "General Path Index" 34 "General Path Index" 35 "General Path Index" 36 "General Path Index" 37 "General Path Index" 38 "General Path Index" 39 "General Path Index" 40 "General Path Index" 41 "General Path Index" 42 "General Path Index" 43 "General Path Index" 44 "General Path Index" 45 "General Path Index" 46 "General Path Index" 47 "General Path Index" 48 "General Path Index" 49 "General Path Index" 50 "General Path Index" 51 "General Path Index" 52 "General Path Index" 53 "General Path Index" 54 "General Path Index" 55 "General Path Index" 56 "General Path Index" 57 "General Path Index" 58 "General Path Index" 59 "General Path Index" 60 "General Path Index" 61 "General Path Index" 62 "General Path Index" 63 "General Path Index" ;
VAL_ 1049 PROLONG_CyclicCounter 0 "Cyclic Counter" 1 "Cyclic Counter" 2 "Cyclic Counter" 3 "Cyclic Counter" ;
VAL_ 1049 PROLONG_Offset 0 "0x0~0x1FFE:Distance" 8190 "0x0~0x1FFE:Distance" 8191 "Invalid" ;
VAL_ 1049 PROLONG_MessageType 0 "Reserved" 1 "Position" 2 "Segment" 3 "Stub" 4 "Profile Short" 5 "Profile Long" 6 "Meta Data" 7 "Invalid" ;
VAL_ 1049 PROLONG_Value 0 "0x0~0xFFFFFFFE:Profile value at Offset" 2147483647 "0x0~0xFFFFFFFE:Profile value at Offset" 2147483647 "Invalid" ;
VAL_ 1048 META_MinorProtocolVersion 0 "Minor version value" 1 "Minor version value" 2 "Minor version value" 3 "Minor version value" 4 "Minor version value" 5 "Minor version value" 6 "Minor version value" 7 "Minor version value" 8 "Minor version value" 9 "Minor version value" 10 "Minor version value" 11 "Minor version value" 12 "Minor version value" 13 "Minor version value" 14 "Minor version value" 15 "Minor version value" ;
VAL_ 1048 META_SpeedUnit 0 "Kilometers per hour" 1 "Mile per hour" ;
VAL_ 1048 META_MapVersionYear 0 "Year" 1 "Year" 2 "Year" 3 "Year" 4 "Year" 5 "Year" 6 "Year" 7 "Year" 8 "Year" 9 "Year" 10 "Year" 11 "Year" 12 "Year" 13 "Year" 14 "Year" 15 "Year" 16 "Year" 17 "Year" 18 "Year" 19 "Year" 20 "Year" 21 "Year" 22 "Year" 23 "Year" 24 "Year" 25 "Year" 26 "Year" 27 "Year" 28 "Year" 29 "Year" 30 "Year" 31 "Year" 32 "Year" 33 "Year" 34 "Year" 35 "Year" 36 "Year" 37 "Year" 38 "Year" 39 "Year" 40 "Year" 41 "Year" 42 "Year" 43 "Year" 44 "Year" 45 "Year" 46 "Year" 47 "Year" 48 "Year" 49 "Year" 50 "Year" 51 "Year" 52 "Year" 53 "Year" 54 "Year" 55 "Year" 56 "Year" 57 "Year" 58 "Year" 59 "Year" 60 "Year" 61 "Year" 62 "Year" 63 "Invalid" ;
VAL_ 1048 META_MapVersionQuarter 0 "Q1" 1 "Q2" 2 "Q3" 3 "Q4" ;
VAL_ 1048 META_RegionCode 0 "Unknown" 1 "0x1~0x7FFE:ISO 3166-2 values" 32766 "0x1~0x7FFE:ISO 3166-2 values" 32767 "Invalid" ;
VAL_ 1048 META_DrivingSide 0 "Driving Side Left" 1 "Driving Side Right" ;
VAL_ 1048 META_HardwareVersion 0 "Unknown" 1 "0x1~0x1FE:Hardware version value" 510 "0x1~0x1FE:Hardware version value" 511 "Invalid" ;
VAL_ 1048 META_MinorProtocolSubVer 0 "Minor sub-version value" 1 "Minor sub-version value" 2 "Minor sub-version value" 3 "Minor sub-version value" 4 "Minor sub-version value" 5 "Minor sub-version value" 6 "Minor sub-version value" 7 "Minor sub-version value" ;
VAL_ 1048 META_MajorProtocolVersion 0 "Major version value" 1 "Major version value" 2 "Major version value" 3 "Major version value" ;
VAL_ 1048 META_CyclicCounter 0 "Cyclic Counter" 1 "Cyclic Counter" 2 "Cyclic Counter" 3 "Cyclic Counter" ;
VAL_ 1048 META_CountryCode 0 "Unknown" 1 "0x1~0x3FE:ISO 3166-1 numeric values" 1022 "0x1~0x3FE:ISO 3166-1 numeric values" 1023 "Invalid" ;
VAL_ 1048 META_MapProvider 0 "Unknown" 1 "NAVTEQ" 2 "TeleAtlas" 3 "Zenrin" 4 "HMNS" 5 "Reserved" 6 "Reserved" 7 "Invalid" ;
VAL_ 1048 META_MessageType 0 "Reserved" 1 "Position" 2 "Segment" 3 "Stub" 4 "Profile Short" 5 "Profile Long" 6 "Meta Data" 7 "Invalid" ;
VAL_ 1051 SEG_DirectionLanes 0 "Unknown" 1 "Lane count" 2 "Lane count" 3 "Lane count" 4 "Lane count" 5 "Lane count" 6 "6 or more lanes" 7 "Invalid" ;
VAL_ 1051 SEG_OppositeLanes 0 "Unknown" 1 "one lane only" 2 "or more lanes" 3 "Invalid" ;
VAL_ 1051 SEG_DividedRoad 0 "Not part of a divided road" 1 "Part of a divided road" 2 "Unknown" 3 "Invalid" ;
VAL_ 1051 SEG_SpeedLimitType 0 "Implicit(default)" 1 "Explicit(on traffic sign)" 2 "Explicit(by night)" 3 "Explicit(by day)" 4 "Explicit(time of day)" 5 "Explicit(rain)" 6 "Explicit(snow)" 7 "Unknown" ;
VAL_ 1051 SEG_SpeedLimit 0 "Unknown" 1 "Under 5kph(mph)" 2 "7" 3 "10" 4 "15" 5 "20" 6 "25" 7 "30" 8 "35" 9 "40" 10 "45" 11 "50" 12 "55" 13 "60" 14 "65" 15 "70" 16 "75" 17 "80" 18 "85" 19 "90" 20 "95" 21 "100" 22 "105" 23 "110" 24 "115" 25 "120" 26 "130" 27 "140" 28 "150" 29 "160" 30 "Unlimited" 31 "Invalid" ;
VAL_ 1051 SEG_FormOfWay 0 "Unkonwn" 1 "Main road(nondisjunction)" 2 "Main road(disjunction)" 3 "JC" 4 "Plural Junction M" 5 "IC" 6 "Reserved" 7 "Service Area" 8 "Reserved" 9 "Roundabout" 10 "P turn" 11 "U trun" 12 "Pedestrian" 13 "Frontage Road" 14 "Intersection internal" 15 "Invalid" ;
VAL_ 1051 SEG_ComplexIntersection 0 "Not part of complex intersection" 1 "Part of of complex intersection" 2 "Unknown" 3 "Invalid" ;
VAL_ 1051 SEG_CalculatedRoute 0 "Not Calculated Route(MPP)" 1 "Part of Calculated Route" 2 "Off Route or Recalculating" 3 "Invalid" ;
VAL_ 1051 SEG_FunctionalRoadClass 0 "Unknown" 1 "Freeway" 2 "Arterial(City freeway" 3 "County" 4 "Collector" 5 "Loca" 6 "Etc(ferry, unpaved)" 7 "Invalid" ;
VAL_ 1051 SEG_Update 0 "False" 1 "True" ;
VAL_ 1051 SEG_Retransmission 0 "false" 1 "true" ;
VAL_ 1051 SEG_BuiltUpArea 0 "Not part of built-up area" 1 "Part of built-up area" 2 "Unknown" 3 "Invalid" ;
VAL_ 1051 SEG_Bridge 0 "Not part of a bridge" 1 "Part of a bridge" 2 "Unknown" 3 "Invalid" ;
VAL_ 1051 SEG_Tunnel 0 "Not part of a tunnel" 1 "Part of a tunnel" 2 "Unknown" 3 "Invalid" ;
VAL_ 1051 SEG_PathIndex 0 "Unknown" 1 "Reserved" 2 "Reserved" 3 "Reserved" 4 "Reserved" 5 "Reserved" 6 "Reserved" 7 "Reserved" 8 "General path index" 9 "General path index" 10 "General path index" 11 "General path index" 12 "General path index" 13 "General path index" 14 "General path index" 15 "General path index" 16 "General path index" 17 "General path index" 18 "General path index" 19 "General path index" 20 "General path index" 21 "General path index" 22 "General path index" 23 "General path index" 24 "General path index" 25 "General path index" 26 "General path index" 27 "General path index" 28 "General path index" 29 "General path index" 30 "General path index" 31 "General path index" 32 "General path index" 33 "General path index" 34 "General path index" 35 "General path index" 36 "General path index" 37 "General path index" 38 "General path index" 39 "General path index" 40 "General path index" 41 "General path index" 42 "General path index" 43 "General path index" 44 "General path index" 45 "General path index" 46 "General path index" 47 "General path index" 48 "General path index" 49 "General path index" 50 "General path index" 51 "General path index" 52 "General path index" 53 "General path index" 54 "General path index" 55 "General path index" 56 "General path index" 57 "General path index" 58 "General path index" 59 "General path index" 60 "General path index" 61 "General path index" 62 "General path index" 63 "General path index" ;
VAL_ 1051 SEG_CyclicCounter 0 "Cyclic counter" 1 "Cyclic counter" 2 "Cyclic counter" 3 "Cyclic counter" ;
VAL_ 1051 SEG_Offset 0 "0x0~0x1FFE:Distance" 8190 "0x0~0x1FFE:Distance" 8191 "Invalid" ;
VAL_ 1051 SEG_MessageType 0 "Reserved" 1 "Position" 2 "Segment" 3 "Stub" 4 "Profile short" 5 "Profile long" 6 "Meta data" 7 "Invalid" ;
VAL_ 1289 HU_DATC_PasModeSet 0 "Reserved" 1 "Vent" 2 "BL" 3 "Floor" 4 "Reserved" 5 "Reserved" 6 "Reserved" 7 "Reserved" 8 "Reserved" 9 "Reserved" 10 "Reserved" 11 "Reserved" 12 "Reserved" 13 "Reserved" 14 "Reserved" 15 "Invalid" ;
VAL_ 1289 HU_DATC_WshFldUSMSet 0 "Default" 1 "Washer fluid USM OFF" 2 "Washer fluid USM ON" 3 "Invalid" ;
VAL_ 1289 HU_DATC_DrvOnlySet 0 "Driver Only Off" 1 "Driver Only On" 2 "Reserved" 3 "Invalid" ;
VAL_ 1289 HU_DATC_HeatSet 0 "Heat Off" 1 "Heat On" 2 "Reserved" 3 "Invalid" ;
VAL_ 1050 PROSHORT_Update 0 "False" 1 "True" ;
VAL_ 1050 PROSHORT_Retransmission 0 "False" 1 "True" ;
VAL_ 1050 PROSHORT_ControlPoint 0 "False" 1 "True" ;
VAL_ 1050 PROSHORT_ProfileType 0 "Invalid" 1 "Curvature" 2 "Route Number types" 3 "Slope(step)" 4 "Slope(Linear)" 5 "Road Accessibility" 6 "Road condition" 7 "Variable Speed Sign Position" 8 "Heading Change" 9 "Reserved for standard type" 10 "Reserved for standard type" 11 "Reserved for standard type" 12 "Reserved for standard type" 13 "Reserved for standard type" 14 "Reserved for standard type" 15 "Reserved for standard type" 16 "Alert Information Section" 17 "Curvature Average Speed" 18 "Reserved for system specific types" 19 "Reserved for system specific types" 20 "Reserved for system specific types" 21 "Reserved for system specific types" 22 "Reserved for system specific types" 23 "Reserved for system specific types" 24 "Reserved for system specific types" 25 "Reserved for system specific types" 26 "Reserved for system specific types" 27 "Reserved for system specific types" 28 "Reserved for system specific types" 29 "Reserved for system specific types" 30 "Reserved for system specific types" 31 "Reserved for system specific types" ;
VAL_ 1050 PROSHORT_Value1 0 "0x0~0x3FE:Profile value at Offset+Distance1" 1022 "0x0~0x3FE:Profile value at Offset+Distance1" 1023 "Invalid" ;
VAL_ 1050 PROSHORT_Value0 0 "0x0~0x3FE:Profile Vaue at Offset" 1022 "0x0~0x3FE:Profile Vaue at Offset" 1023 "Invalid" ;
VAL_ 1050 PROSHORT_Distance 0 "0x0~0x3FE:Distance" 1022 "0x0~0x3FE:Distance" 1023 "Invalid" ;
VAL_ 1050 PROSHORT_Accuracy 0 "High Accuracy" 1 "Middle Accuracy" 2 "Low Accuracy" 3 "Unknown" ;
VAL_ 1050 PROSHORT_PathIndex 0 "Unknown" 1 "Reserved" 2 "Reserved" 3 "Reserved" 4 "Reserved" 5 "Reserved" 6 "Reserved" 7 "Reserved" 8 "General Path Index" 9 "General Path Index" 10 "General Path Index" 11 "General Path Index" 12 "General Path Index" 13 "General Path Index" 14 "General Path Index" 15 "General Path Index" 16 "General Path Index" 17 "General Path Index" 18 "General Path Index" 19 "General Path Index" 20 "General Path Index" 21 "General Path Index" 22 "General Path Index" 23 "General Path Index" 24 "General Path Index" 25 "General Path Index" 26 "General Path Index" 27 "General Path Index" 28 "General Path Index" 29 "General Path Index" 30 "General Path Index" 31 "General Path Index" 32 "General Path Index" 33 "General Path Index" 34 "General Path Index" 35 "General Path Index" 36 "General Path Index" 37 "General Path Index" 38 "General Path Index" 39 "General Path Index" 40 "General Path Index" 41 "General Path Index" 42 "General Path Index" 43 "General Path Index" 44 "General Path Index" 45 "General Path Index" 46 "General Path Index" 47 "General Path Index" 48 "General Path Index" 49 "General Path Index" 50 "General Path Index" 51 "General Path Index" 52 "General Path Index" 53 "General Path Index" 54 "General Path Index" 55 "General Path Index" 56 "General Path Index" 57 "General Path Index" 58 "General Path Index" 59 "General Path Index" 60 "General Path Index" 61 "General Path Index" 62 "General Path Index" 63 "General Path Index" ;
VAL_ 1050 PROSHORT_CyclicCounter 0 "Cyclic Counter" 1 "Cyclic Counter" 2 "Cyclic Counter" 3 "Cyclic Counter" ;
VAL_ 1050 PROSHORT_Offset 0 "0x0~0x1FFE:Distance" 8190 "0x0~0x1FFE:Distance" 8191 "Invalid" ;
VAL_ 1050 PROSHORT_MessageType 0 "Reserved" 1 "Position" 2 "Segment" 3 "Stub" 4 "Profile Short" 5 "Profile Long" 6 "Meta Data" 7 "Invalid" ;
VAL_ 1294 CF_Gway_WasherFluidSw 0 "Off" 1 "On" ;
VAL_ 1294 CR_Datc_DRSeatWheel_USM_Set 0 "Default" 1 "Off" 2 "On" 3 "Invalid" ;
VAL_ 1294 DATC_TunnelIND 0 "off (outside tunnel)" 1 "on (inside tunnel)" ;
VAL_ 1294 DATC_TunnelState 0 "off (outside tunnel)" 1 "on (inside tunnel)" ;
VAL_ 1294 C_MFSW_WasherSw 0 "OFF" 1 "ON" ;
VAL_ 1294 C_IBU_WasherSw 0 "OFF" 1 "ON" ;
VAL_ 1052 STUB_DirectionLanes 0 "Unknown" 1 "Lane count" 2 "Lane count" 3 "Lane count" 4 "Lane count" 5 "Lane count" 6 "6 or more lanes" 7 "Invalid" ;
VAL_ 1052 STUB_OppositeLanes 0 "Unknown" 1 "One lane only" 2 "2 or more lanes" 3 "Invalid" ;
VAL_ 1052 STUB_RightOfWay 0 "Parent path has right of way" 1 "Sub-path has right of way" 2 "Unknown" 3 "Invalid" ;
VAL_ 1052 STUB_LastStubAtOffset 0 "more STUB messages will be sent" 1 "last one of given parent" ;
VAL_ 1052 STUB_FormOfWay 0 "Unknown" 1 "Main path(nondisjunction)" 2 "Main path(disjunction)" 3 "JC" 4 "Plural Junction M" 5 "IC" 6 "Reserved" 7 "Service Area" 8 "Reserved" 9 "Roundabout" 10 "P turn" 11 "U trun" 12 "Pedestrian" 13 "Frontage Road" 14 "Intersection internal" 15 "Invalid" ;
VAL_ 1052 STUB_ComplexIntersection 0 "Not part of complex intersection" 1 "Part of of complex intersection" 2 "Unknown" 3 "Invalid" ;
VAL_ 1052 STUB_CalculatedRoute 0 "Not Calculated Route(MPP)" 1 "Part of Calculated Route" 2 "Off Route or Recalculating Route" 3 "Invalid" ;
VAL_ 1052 STUB_FunctionalRoadClass 0 "Unknown" 1 "Freeway" 2 "Arterial(City freeway)" 3 "County" 4 "Collector" 5 "Local" 6 "Etc(ferry, unpaved)" 7 "Invalid" ;
VAL_ 1052 STUB_Update 0 "False" 1 "True" ;
VAL_ 1052 STUB_Retransmission 0 "False" 1 "True" ;
VAL_ 1052 STUB_SubPathIndex 0 "Unknown" 1 "Reserved" 2 "Reserved" 3 "Reserved" 4 "Reserved" 5 "Reserved" 6 "Reserved" 7 "Reserved" 8 "General Path Index" 9 "General Path Index" 10 "General Path Index" 11 "General Path Index" 12 "General Path Index" 13 "General Path Index" 14 "General Path Index" 15 "General Path Index" 16 "General Path Index" 17 "General Path Index" 18 "General Path Index" 19 "General Path Index" 20 "General Path Index" 21 "General Path Index" 22 "General Path Index" 23 "General Path Index" 24 "General Path Index" 25 "General Path Index" 26 "General Path Index" 27 "General Path Index" 28 "General Path Index" 29 "General Path Index" 30 "General Path Index" 31 "General Path Index" 32 "General Path Index" 33 "General Path Index" 34 "General Path Index" 35 "General Path Index" 36 "General Path Index" 37 "General Path Index" 38 "General Path Index" 39 "General Path Index" 40 "General Path Index" 41 "General Path Index" 42 "General Path Index" 43 "General Path Index" 44 "General Path Index" 45 "General Path Index" 46 "General Path Index" 47 "General Path Index" 48 "General Path Index" 49 "General Path Index" 50 "General Path Index" 51 "General Path Index" 52 "General Path Index" 53 "General Path Index" 54 "General Path Index" 55 "General Path Index" 56 "General Path Index" 57 "General Path Index" 58 "General Path Index" 59 "General Path Index" 60 "General Path Index" 61 "General Path Index" 62 "General Path Index" 63 "General Path Index" ;
VAL_ 1052 STUB_PathIndex 0 "first path in the Horizon" 1 "Reserved" 2 "Reserved" 3 "Reserved" 4 "Reserved" 5 "Reserved" 6 "Reserved" 7 "Reserved" 8 "General Path Index" 9 "General Path Index" 10 "General Path Index" 11 "General Path Index" 12 "General Path Index" 13 "General Path Index" 14 "General Path Index" 15 "General Path Index" 16 "General Path Index" 17 "General Path Index" 18 "General Path Index" 19 "General Path Index" 20 "General Path Index" 21 "General Path Index" 22 "General Path Index" 23 "General Path Index" 24 "General Path Index" 25 "General Path Index" 26 "General Path Index" 27 "General Path Index" 28 "General Path Index" 29 "General Path Index" 30 "General Path Index" 31 "General Path Index" 32 "General Path Index" 33 "General Path Index" 34 "General Path Index" 35 "General Path Index" 36 "General Path Index" 37 "General Path Index" 38 "General Path Index" 39 "General Path Index" 40 "General Path Index" 41 "General Path Index" 42 "General Path Index" 43 "General Path Index" 44 "General Path Index" 45 "General Path Index" 46 "General Path Index" 47 "General Path Index" 48 "General Path Index" 49 "General Path Index" 50 "General Path Index" 51 "General Path Index" 52 "General Path Index" 53 "General Path Index" 54 "General Path Index" 55 "General Path Index" 56 "General Path Index" 57 "General Path Index" 58 "General Path Index" 59 "General Path Index" 60 "General Path Index" 61 "General Path Index" 62 "General Path Index" 63 "General Path Index" ;
VAL_ 1052 STUB_CyclicCounter 0 "Cyclic counter" 1 "Cyclic counter" 2 "Cyclic counter" 3 "Cyclic counter" ;
VAL_ 1052 STUB_Offset 0 "0x0~0x1FFE:Distance" 8190 "0x0~0x1FFE:Distance" 8191 "Invalid" ;
VAL_ 1052 STUB_MessageType 0 "Reserved" 1 "Position" 2 "Segment" 3 "Stub" 4 "Profile Short" 5 "Profile Long" 6 "Meta Data" 7 "Invalid" ;
VAL_ 1293 DATC_DiagMode 0 "Off" 1 "Diagnosis Code Display" 2 "Not used" 3 "Invalid" ;
VAL_ 1293 DATC_Rear_ChangeReqDisp 0 "OFF" 1 "USER INPUT" 2 "Not Used" 3 "Invalid" ;
VAL_ 1293 DATC_Rear_ClimateScnDisp 0 "Deactived" 1 "Actived" 2 "Not Used" 3 "Invalid" ;
VAL_ 1293 DATC_AutoArClnSysSta 0 "Auto Air Cleaning System Off" 1 "AutoAir Cleaning System On" 2 "Reserved" 3 "Invalid" ;
VAL_ 1293 DATC_SelfDiagDisp 0 "Blank Display" 255 "Invalid" ;
VAL_ 1293 DATC_AqsLevelOut 0 "OFF" 1 "1 LEVEL" 2 "2 LEVEL" 3 "3 LEVEL" 4 "4 LEVEL" 5 "5 LEVEL" 6 "Not Used" 7 "Not Used" 8 "Not Used" 9 "Not Used" 10 "Not Used" 11 "Not Used" 12 "Not Used" 13 "Not Used" 14 "Not Used" 15 "Invalid" ;
VAL_ 1293 CR_Fatc_PreConSwi 0 "Deactivated" 1 "activated" 3 "Invalid" ;
VAL_ 1293 DATC_EV_ScnDisp 0 "Deactivated" 1 "Activated" 2 "Not Used" 3 "Invalid" ;
VAL_ 1293 DATC_AutoDefogSysOff_Disp 0 "ADS SYSTEM OFF" 1 "ADS SYSTEM ON" 2 "Not used" 3 "Invalid" ;
VAL_ 1293 DATC_WshFldUSMState 0 "Default" 1 "OFF" 2 "ON" 3 "Invalid" ;
VAL_ 1280 CF_SWL_Ind 0 "Warning Lamp on" 1 "Warning Lamp off" 2 "Warning Lamp flash" 3 "Not used" ;
VAL_ 1280 CF_TTL_Ind 0 "Telltale Lamp on" 1 "Telltale Lamp off" 2 "Telltale Lamp flash" 3 "Not used" ;
VAL_ 1280 CF_SBR_Ind 0 "SBR Lamp on" 1 "SBR Lamp off" 2 "SBR Lamp flash" 3 "Not used" ;
VAL_ 1042 CF_Gway_DigitalKeyOption 0 "not applied(time out)" 1 "applied" 2 "Reserved" 3 "Invalid" ;
VAL_ 1042 CF_Gway_ProfileIDRValue 0 "Default" 15 "Invalid" 1 "Guest" 2 "Profile 1" 3 "Profile 2" 4 "Reserved" 5 "Reserved" 6 "Reserved" 7 "Reserved" 8 "Reserved" 9 "Reserved" 10 "Reserved" 11 "Reserved" 12 "Reserved" 13 "Reserved" 14 "Reserved" ;
VAL_ 1042 CF_Datc_DefLogic_USM_Set 0 "Default" 1 "Def Logic USM OFF" 2 "Def Logic USM ON" 3 "Invalid" ;
VAL_ 1042 CF_Datc_AutoFresh_USM_Set 0 "Default" 1 "Auto Ventilation USM OFF" 2 "Auto Ventilation USM ON" 3 "Invalid" ;
VAL_ 1287 ABS_W_LAMP 0 "ABS Warning lamp OFF" 1 "ABS Warning lamp ON" ;
VAL_ 1287 TCS_OFF_LAMP 0 "TCS/ESC OFF SW Lamp OFF" 1 "TCS/ESC OFF SW Lamp ON" ;
VAL_ 1287 TCS_LAMP 0 "TCS/ESC Function/Warning Lamp OFF" 1 "TCS/ESC Function/Warning Lamp ON" 2 "TCS/ESC Function/Warning Lamp BLINKING(2Hz)" 3 "Reserved" ;
VAL_ 1287 DBC_W_LAMP 0 "DBC Warning lamp OFF" 1 "DBC Warning lamp ON" ;
VAL_ 1287 DBC_F_LAMP 0 "DBC Function lamp OFF" 1 "DBC Function lamp ON" 2 "DBC Function lamp BLINKING(2Hz)" 3 "Reserved" ;
VAL_ 1287 ESC_Off_Step 0 "Normal Mode" 1 "Sports Mode" 2 "Off Mode" 3 "ESC OFF SW is defective (failed)" ;
VAL_ 1287 DBC_CLU 0 "DBC Enabled" 1 "DBC Disabled by system fault" 2 "Reserved" 3 "Reserved" ;
VAL_ 1287 AVH_CLU 0 "AVH is off" 1 "AUTO HOLD to be deactivated Press Brake Pedal" 2 "Press Brake Pedal to Release AUTO HOLD" 3 "AUTO HOLD cannot be activated Close Seat Belt, Door, Hood, Trunk" 4 "AUTO HOLD cannot be activated, Close Seat Belt, Door, Hood" 5 "AUTO HOLD cannot be deactivated. Close Door" ;
VAL_ 1287 AVH_I_LAMP 0 "Lamp On" 1 "Lamp Off" 2 "Reserved" 3 "Reserved" ;
VAL_ 1287 EBD_W_LAMP 0 "EBD Warning lamp OFF" 1 "EBD Warning lamp ON" ;
VAL_ 1287 AVH_ALARM 0 "No alarm" 1 "On AVH Activation, Vehicle is not secured and driver is still inside = comfortable tone" ;
VAL_ 1287 AVH_LAMP 0 "AVH Off (Lamp Status" 1 "AVH failure (Lamp Status" 2 "AVH ACTIVE (Lamp Status" 3 "AVH READY (Lamp Status" 4 "Lamp Status" 5 "Lamp Status" 6 "Lamp Status" ;
VAL_ 1044 CF_TMU_ICCB_InCurModeState 0 "Max" 1 "Decreasing" 2 "Min" 3 "Invalid" ;
VAL_ 1044 CF_TMU_EVSE_InCurModeState 0 "Max" 1 "Decreasing" 2 "Min" 3 "Invalid" ;
VAL_ 852 CF_Lvr_PButtonStatus 0 "Initial" 1 "Button ON" 2 "Button OFF" 3 "Fault" ;
VAL_ 852 CF_Lvr_RButtonStatus 0 "Initial" 1 "Button ON" 2 "Button OFF" 3 "Fault" ;
VAL_ 852 CF_Lvr_NButtonStatus 0 "Initial" 1 "Button ON" 2 "Button OFF" 3 "Fault" ;
VAL_ 852 CF_Lvr_DButtonStatus 0 "Initial" 1 "Button ON" 2 "Button OFF" 3 "Fault" ;
VAL_ 852 CF_Lvr_UnLockButtonStatus 0 "Initial" 1 "Button ON" 2 "Button OFF" 3 "Fault" ;
VAL_ 852 CF_Lvr_PRelStat 0 "Initial value" 1 "Button ON" 2 "Button OFF" 3 "Fault" ;
VAL_ 852 CF_Lvr_PosInf 0 "Initial value" 1 "Gear lever position P" 2 "Intermediate position P-R" 3 "Gear lever position R" 4 "Intermediate position R-N" 5 "Gear lever position N" 6 "Intermediate position N-D" 7 "Gear lever position D" 8 "Nr" 9 "Nd" 10 "Gear lever position M(Ds)" 11 "Gear lever position 'M+'" 12 "Gear lever position 'M-'" 15 "Fault" ;
VAL_ 852 CF_Lvr_PButtonStatus_Reversed 0 "Fault" 1 "Button OFF" 2 "Button ON" 3 "Initial" ;
VAL_ 852 CF_Lvr_RButtonStatus_Reversed 0 "Fault" 1 "Button OFF" 2 "Button ON" 3 "Initial" ;
VAL_ 852 CF_Lvr_NButtonStatus_Reversed 0 "Fault" 1 "Button OFF" 2 "Button ON" 3 "Initial" ;
VAL_ 852 CF_Lvr_DButtonStatus_Reversed 0 "Fault" 1 "Button OFF" 2 "Button ON" 3 "Initial" ;
VAL_ 852 CF_Lvr_UnLkButStatus_Reversed 0 "Fault" 1 "Button OFF" 2 "Button ON" 3 "Initial" ;
VAL_ 852 CF_Lvr_PRelButStatus_Reversed 0 "Fault" 1 "Button OFF" 2 "Button ON" 3 "Initial" ;
VAL_ 852 CF_Lvr_UnitStatus 0 "Normal" 1 "CF_LEVER Fault without function degration" 2 "CF_Lvr fault with function degrade" 3 "Reserved" 4 "Reserved" 5 "Reserved" 6 "Reserved" 7 "Reserved" ;
VAL_ 852 CF_MoodLpColorRValue 0 "Defult Value" 1 "color 1" 2 "color 2" 3 "color 3" 4 "color 4" 5 "color 5" 6 "color 6" 7 "color 7" 15 "Invalid" ;
VAL_ 852 CF_Lvr_IndicatorStatus 0 "ALL Light OFF" 1 "P lighted" 2 "R lighted" 3 "N Lighted" 4 "D lighted" 5 "B lighted" 6 "reserved" 7 "reserved" 255 "lighting Fault" ;
VAL_ 852 CF_Lvr_Wrn 0 "Warning OFF" 1 "Gear Button Failure" 2 "P Pelease Button Failure" 3 "P Button Failure" 4 "D Button Failure" 5 "Reserved" 6 "Button Stuck Failure" 7 "Reserved" 8 "P button on & R/N/D signal on(Dial type)" 9 "Dial Stuck" 10 "Lever Hall Sensor Failure" 11 "ECU HW Failure" 12 "Lever Hall Sensor Normal" ;
VAL_ 852 CF_MoodLpBrightValue 0 "Default value" 1 "Off" 2 "step 1" 3 "step 2" 4 "step 3" 5 "step 4" 6 "reserved" 7 "Invalid" ;
VAL_ 1062 HU_VIN_Index 0 "reserved" 1 "Index 1" 2 "Index 2" 3 "Index 3" 4 "reserved" 5 "reserved" 6 "reserved" 7 "invalid" ;
VAL_ 1062 HU_VINStatus 0 "None" 1 "VIN ready" 2 "reserved" 3 "invalid" ;
VAL_ 1062 HU_TeleOption 0 "None" 1 "AVNT" 2 "reserved" 3 "invalid" ;
VAL_ 1062 HU_VIN_56 0 "Invalid VIN" ;
VAL_ 1321 CF_Vcu_fWinterSchedBand 0 "None" 1 "Set" ;
VAL_ 1323 CF_Vcu_CruOnLamp 0 "Lamp Off" 1 "Lamp On" ;
VAL_ 1323 CF_Vcu_CruSetLamp 0 "Lamp Off" 1 "Lamp On" ;
VAL_ 1323 CF_Vcu_Ovrride 0 "Override clear" 1 "Override set" ;
VAL_ 1323 CF_Vcu_CrzDrvAlertDisp 0 "default" 1 "CC Disengaged" 2 "No CC Engage Condition" 3 "reserved" ;
VAL_ 1323 CF_Vcu_SldAct 0 "Speed Limiter Lamp Off" 1 "Speed Limiter Lamp On" ;
VAL_ 1323 CF_Vcu_SldSet 0 "Lamp Off" 1 "Lamp On" ;
VAL_ 1323 CF_Vcu_SldDrvAlertDisp 0 "Default" 1 "SLD Disengaged" 2 "No SLD Engage Condition" 3 "Reserved" ;
VAL_ 1085 CF_Clu_CurMon 0 "None" 1 "Set" ;
VAL_ 1085 CF_Clu_CurTue 0 "None" 1 "Set" ;
VAL_ 1085 CF_Clu_CurWed 0 "None" 1 "Set" ;
VAL_ 1085 CF_Clu_CurThu 0 "None" 1 "Set" ;
VAL_ 1085 CF_Clu_CurFri 0 "None" 1 "Set" ;
VAL_ 1085 CF_Clu_CurSat 0 "None" 1 "Set" ;
VAL_ 1085 CF_Clu_CurSun 0 "None" 1 "Set" ;
VAL_ 1085 CF_Clu_CurTime_Rdy 0 "Not Ready" 1 "Ready" ;
VAL_ 1084 CF_Clu_SchedChargNValueSet 0 "Default(¹Ì±¸¼º)" 1 "None(Off)" 2 "Set(On)" 3 "Invalid" ;
VAL_ 1084 CF_Clu_SchedClmtNValueSet 0 "Default(¹Ì±¸¼º)" 1 "None(Off)" 2 "Set(On)" 3 "Invalid" ;
VAL_ 1084 CF_Clu_SchedClmtDfrNValueSet 0 "Default(¹Ì±¸¼º)" 1 "Deactivate Defrost Mode(Off)" 2 "Activate Defrost Mode(On)" 3 "Invalid" ;
VAL_ 1084 CF_Clu_BatteryHeatNValueSet 0 "Default(¹Ì±¸¼º)" 1 "Winter Mode Off" 2 "Winter Mode On" 3 "Invalid" ;
VAL_ 1084 CF_Clu_DepartSunNValueSet 0 "Default(¹Ì±¸¼º)" 1 "None(Off)" 2 "Set(On)" 3 "Invalid" ;
VAL_ 1084 CF_Clu_DepartMonNValueSet 0 "Default(¹Ì±¸¼º)" 1 "None(Off)" 2 "Set(On)" 3 "Invalid" ;
VAL_ 1084 CF_Clu_SchedClmtTempNValueSet 0 "Default" 1 "15~32 ¡É" 2 "15~32 ¡É" 3 "15~32 ¡É" 4 "15~32 ¡É" 5 "15~32 ¡É" 6 "15~32 ¡É" 7 "15~32 ¡É" 8 "15~32 ¡É" 9 "15~32 ¡É" 10 "15~32 ¡É" 11 "15~32 ¡É" 12 "15~32 ¡É" 13 "15~32 ¡É" 14 "15~32 ¡É" 15 "15~32 ¡É" 16 "15~32 ¡É" 17 "15~32 ¡É" 18 "15~32 ¡É" 19 "15~32 ¡É" 20 "15~32 ¡É" 21 "15~32 ¡É" 22 "15~32 ¡É" 23 "15~32 ¡É" 24 "15~32 ¡É" 25 "15~32 ¡É" 26 "15~32 ¡É" 27 "15~32 ¡É" 28 "15~32 ¡É" 29 "15~32 ¡É" 30 "15~32 ¡É" 31 "15~32 ¡É" 32 "15~32 ¡É" 33 "15~32 ¡É" 34 "15~32 ¡É" 35 "15~32 ¡É" 36 "Reserved" ;
VAL_ 1084 CF_Clu_DepartTueNValueSet 0 "Default(¹Ì±¸¼º)" 1 "None(Off)" 2 "Set(On)" 3 "Invalid" ;
VAL_ 1084 CF_Clu_DepartWedNValueSet 0 "Default(¹Ì±¸¼º)" 1 "None(Off)" 2 "Set(On)" 3 "Invalid" ;
VAL_ 1084 CF_Clu_DepartThuNValueSet 0 "Default(¹Ì±¸¼º)" 1 "None(Off)" 2 "Set(On)" 3 "Invalid" ;
VAL_ 1084 CF_Clu_DepartFriNValueSet 0 "Default(¹Ì±¸¼º)" 1 "None(Off)" 2 "Set(On)" 3 "Invalid" ;
VAL_ 1084 CF_Clu_DepartSatNValueSet 0 "Default(¹Ì±¸¼º)" 1 "None(Off)" 2 "Set(On)" 3 "Invalid" ;
VAL_ 1084 CF_Clu_DepartHourNValueSet 0 "Default" 1 "0~23 Hour" 2 "0~23 Hour" 3 "0~23 Hour" 4 "0~23 Hour" 5 "0~23 Hour" 6 "0~23 Hour" 7 "0~23 Hour" 8 "0~23 Hour" 9 "0~23 Hour" 10 "0~23 Hour" 11 "0~23 Hour" 12 "0~23 Hour" 13 "0~23 Hour" 14 "0~23 Hour" 15 "0~23 Hour" 16 "0~23 Hour" 17 "0~23 Hour" 18 "0~23 Hour" 19 "0~23 Hour" 20 "0~23 Hour" 21 "0~23 Hour" 22 "0~23 Hour" 23 "0~23 Hour" 24 "0~23 Hour" 25 "Reserved" 26 "Reserved" 27 "Reserved" 28 "Reserved" 29 "Reserved" 30 "Reserved" 31 "Reserved" ;
VAL_ 1084 CF_Clu_DepartMinNValueSet 0 "Default" 1 "0~50 Min" 2 "0~50 Min" 3 "0~50 Min" 4 "0~50 Min" 5 "0~50 Min" 6 "0~50 Min" 7 "Reserved" ;
VAL_ 1084 CF_Clu_EVSE_InCurNValueSet 0 "Default" 1 "Max" 2 "Decreasing" 3 "Min" ;
VAL_ 1084 CF_Clu_ICCB_InCurNValueSet 0 "Default" 1 "Max" 2 "Decreasing" 3 "Min" ;
VAL_ 1084 CF_Clu_EcoRegenLvNValueSet 0 "Low" 1 "Standard" 2 "High" 3 "Invalid" ;
VAL_ 1084 CF_Clu_NormalRegenLvNValueSet 0 "Low" 1 "Standard" 2 "High" 3 "Invalid" ;
VAL_ 1084 CF_Clu_EconSTHourNValueSet 0 "Default" 1 "0~23 Hour" 2 "0~23 Hour" 3 "0~23 Hour" 4 "0~23 Hour" 5 "0~23 Hour" 6 "0~23 Hour" 7 "0~23 Hour" 8 "0~23 Hour" 9 "0~23 Hour" 10 "0~23 Hour" 11 "0~23 Hour" 12 "0~23 Hour" 13 "0~23 Hour" 14 "0~23 Hour" 15 "0~23 Hour" 16 "0~23 Hour" 17 "0~23 Hour" 18 "0~23 Hour" 19 "0~23 Hour" 20 "0~23 Hour" 21 "0~23 Hour" 22 "0~23 Hour" 23 "0~23 Hour" 24 "0~23 Hour" 25 "Reserved" 26 "Reserved" 27 "Reserved" 28 "Reserved" 29 "Reserved" 30 "Reserved" 31 "Reserved" ;
VAL_ 1084 CF_Clu_EconENDHourNValueSet 0 "Default" 1 "0~23 Hour" 2 "0~23 Hour" 3 "0~23 Hour" 4 "0~23 Hour" 5 "0~23 Hour" 6 "0~23 Hour" 7 "0~23 Hour" 8 "0~23 Hour" 9 "0~23 Hour" 10 "0~23 Hour" 11 "0~23 Hour" 12 "0~23 Hour" 13 "0~23 Hour" 14 "0~23 Hour" 15 "0~23 Hour" 16 "0~23 Hour" 17 "0~23 Hour" 18 "0~23 Hour" 19 "0~23 Hour" 20 "0~23 Hour" 21 "0~23 Hour" 22 "0~23 Hour" 23 "0~23 Hour" 24 "0~23 Hour" 25 "Reserved" 26 "Reserved" 27 "Reserved" 28 "Reserved" 29 "Reserved" 30 "Reserved" 31 "Reserved" ;
VAL_ 127 C_StopLampLhOpenSts 0 "Normal" 1 "Open Status" ;
VAL_ 127 C_StopLampRhOpenSts 0 "Normal" 1 "Open Status" ;
VAL_ 127 C_HLampLowLhOpenSts 0 "Normal" 1 "Open Status" ;
VAL_ 127 C_HLampLowRhOpenSts 0 "Normal" 1 "Open Status" ;
VAL_ 127 C_HLampHighLhOpenSts 0 "Normal" 1 "Open Status" ;
VAL_ 127 C_HLampHighRhOpenSts 0 "Normal" 1 "Open Status" ;
VAL_ 127 C_RearTSIGLhOpenSts 0 "Normal" 1 "Open Status" ;
VAL_ 127 C_RearTSIGRhOpenSts 0 "Normal" 1 "Open Status" ;
VAL_ 127 C_FrontTSIGLhOpenSts 0 "Normal" 1 "Open Status" ;
VAL_ 127 C_FrontTSIGRhOpenSts 0 "Normal" 1 "Open Status" ;
VAL_ 127 C_HLampBifuncLhOpenSts 0 "Normal" 1 "Open Status" ;
VAL_ 127 C_HLampBifuncRhOpenSts 0 "Normal" 1 "Open Status" ;
VAL_ 127 C_MoodLp 0 "0%" 1 "Fade In" 2 "Mood Bright Percent" 3 "Fade Out" 4 "100%" ;
VAL_ 127 CF_Gway_MoodLpColorRValue 0 "Default Value" 1 "color 1" 2 "color 2" 3 "color 3" 4 "color 4" 5 "color 5" 6 "color 6" 7 "color 7" 15 "Invalid" ;
VAL_ 127 CF_Gway_MoodLpBrightRValue 0 "Default Value" 1 "Off" 2 "step 1" 3 "step 2" 4 "step 3" 5 "step 4" 6 "reserved" 7 "Invalid" ;
VAL_ 1312 CF_OBCWakeupDrLock 0 "Off(Default)" 1 "On(Lock)" ;
VAL_ 1312 CF_OBCWakeupDrUnlock 0 "Off (Default)" 1 "On (Unlock)" ;
VAL_ 1312 CF_Hoodsw_memory 0 "No event" 1 "hood open->close event when ig-off" 2 "reserved" 3 "reserved" ;
VAL_ 1315 CF_Mcu_Mg1Flt 0 "No Fault" 1 "Fault" ;
VAL_ 1315 CF_Mcu_Mg1Wrm 0 "No Warning" 1 "Warning" ;
VAL_ 1315 CF_Mcu_Mg1Ctrl 0 "MCU Not Controllable" 1 "MCU Controllable" ;
VAL_ 1315 CF_Mcu_Mg1Rdy 0 "MCU Not Ready" 1 "MCU is Alive" ;
VAL_ 1315 CF_Mcu_Mg1SvcLmp 0 "ServiceLamp Off" 1 "ServiceLamp On" ;
VAL_ 1315 CF_Mcu_EwpOpReqToBMS 0 "EWP Op. Not Request" 1 "EWP Op. Request" ;
VAL_ 1315 CF_Mcu_Mg1ActTest 0 "Normal Mode" 1 "Actuation Test Mode" ;
VAL_ 1315 CF_Mcu_Mg1AjActivate 0 "Not AJ-activated" 1 "AJ-activated" ;
VAL_ 1315 CF_Mcu_Mg1RlyOffReq 0 "Relay Off Not Request" 1 "Relay Off Request" ;
VAL_ 1315 CF_Mcu_HvIntlockReq 0 "HVIL Reaction Not Request" 1 "HVIL Reaction Request" ;
VAL_ 1315 CF_Mcu_Mg1RsvCalReq 0 "Rsv cal. Not Request" 1 "Rsv cal. Request" ;
VAL_ 1315 CF_Mcu_Mg1RsvCalStat 0 "Complete" 1 "Error" 2 "Running" 3 "Ready" ;
VAL_ 1315 CF_Mcu_Mg1RsvCalNeeded 0 "Rsv is Calibrated" 1 "Rsv is Not Calibrated" ;
VAL_ 1315 CF_Mcu_FatcLpChgInh 0 "Disable" 1 "Enable" ;
VAL_ 1315 CF_Mcu_RadFanOprSts 0 "Radiator Fan Off" 1 "Radiator Fan On Low Speed" 2 "Radiator Fan On High Speed" ;
VAL_ 1315 CF_Mcu_EwpForcedOpSts 0 "OFF" 1 "EWP Forced Operating" ;
VAL_ 1315 CF_Mcu_EwpCoolantDiagEnb 0 "Disable" 1 "Enable" ;
VAL_ 1315 CF_Mcu_EwpCoolantCluDisp 0 "Normal" 1 "Insufficient" ;
VAL_ 1316 CF_Mcu_InvOvLoadWarn 0 "Not Warning" 1 "Warning" ;
VAL_ 1316 CF_Mcu_MotOvSpdWarn 0 "Not Warning" 1 "Warning" ;
VAL_ 1077 DATC_AmbSnsVal 0 "Default" 1 "Reserved" 254 "Sensor Fail" 255 "Invalid" ;
VAL_ 1077 DATC_FrIncarSnsVal 0 "Default" 255 "Invalid" ;
VAL_ 1077 DATC_RrIncarSnsVal 0 "Default" 1 "Reserved" 255 "Invalid" ;
VAL_ 1077 DATC_LhPhotoSnsVal 255 "Invalid" ;
VAL_ 1077 DATC_RhPhotoSnsVal 255 "Invalid" ;
VAL_ 1077 DATC_EvaSnsVal 255 "Invalid" ;
VAL_ 1077 DATC_AdsSnsVal 255 "Invalid" ;
VAL_ 1077 DATC_DustSnsVal 255 "Invalid" ;
VAL_ 1076 DATC_MnlBlwSta 0 "OFF" 1 "AUTO Blower" 2 "Manual 1Step" 3 "Manual 2Step" 4 "Manual 3Step" 5 "Manual 4Step" 6 "Manual 5Step" 7 "Manual 6Step" 8 "Manual 7Step" 9 "Manual 8Step" 10 "Reserved" 11 "Reserved" 12 "Reserved" 13 "Reserved" 14 "Reserved" 15 "Invalid" ;
VAL_ 1076 DATC_MnlModSta 0 "AUTO Mode" 1 "Manual Vent" 2 "Manual Bi-Level" 3 "Manual Floor" 4 "Manual Mix" 5 "Max DEF Mode" 6 "ADS Mode" 7 "Manual 7Mode Def-Vent" 8 "Reserved" 9 "Manual 7Mode Def-Vent-Floor" 10 "Manual 7Mode Def" 11 "Reserved" 12 "Reserved" 13 "Reserved" 14 "Reserved" 15 "Invalid" ;
VAL_ 1076 DATC_MnlACSta 0 "A/C OFF" 1 "A/C ON" 2 "AUTO A/C" 3 "Invalid" ;
VAL_ 1076 DATC_MnlIntakeSta 0 "Manual FRESH" 1 "Manual REC" 2 "AUTO Intake" 3 "Invalid" ;
VAL_ 1076 DATC_MnlRrBlwrSta 0 "OFF" 1 "AUTO Blower" 2 "Manual 1Step" 3 "Manual 2Step" 4 "Manual 3Step" 5 "Manual 4Step" 6 "Manual 5Step" 7 "Manual 6Step" 8 "Manual 7Step" 9 "Manual 8Step" 10 "Reserved" 11 "Reserved" 12 "Reserved" 13 "Reserved" 14 "Reserved" 15 "Invalid" ;
VAL_ 1076 DATC_MnlRrModSta 0 "AUTO Mode" 1 "Manual Vent" 2 "Manual Bi-Level" 3 "Manual Floor" 4 "Manual Mix" 5 "Max DEF Mode" 6 "ADS Mode" 7 "Manual 7Mode Def-Vent" 8 "Reserved" 9 "Manual 7Mode Def-Vent-Floor" 10 "Manual 7Mode Def" 11 "Reserved" 12 "Reserved" 13 "Reserved" 14 "Reserved" 15 "Invalid" ;
VAL_ 1076 DATC_MnlRrACSta 0 "A/C OFF" 1 "A/C ON" 2 "AUTO A/C" 3 "Invalid" ;
VAL_ 1076 DATC_StrWhlHtrSta 0 "OFF" 1 "ON (1 Step SPEC)" 2 "1 Step ON (2 Step SPEC)" 3 "1 Step & 2 Step ON (2 Step SPEC)" 4 "Reserved" 5 "Reserved" 6 "Reserved" 7 "Reserved" 8 "Reserved" 9 "Reserved" 10 "Reserved" 11 "Reserved" 12 "Reserved" 13 "Reserved" 14 "Reserved" 15 "Invalid" ;
VAL_ 1076 DATC_DrvStHtrVntSta 0 "Default" 1 "Reserved" 2 "OFF" 3 "" 4 "Driver Seat Ventilation 1st&2nd ON" 5 "Driver Seat Ventilation 1st&2nd&3rd" 6 "Driver Seat Warmer 1st ON" 7 "Driver Seat Warmer 1st&2nd ON" 8 "Driver Seat Warmer 1st&2nd&3rd ON" 9 "Reserved" 10 "Reserved" 11 "Reserved" 12 "Reserved" 13 "Reserved" 14 "Reserved" 15 "Invalid" ;
VAL_ 1076 DATC_PassStHtrVntSta 0 "Default" 1 "Reserved" 2 "OFF" 3 "Driver Seat Ventilation 1st ON" 4 "Driver Seat Ventilation 1st&2nd ON" 5 "Driver Seat Ventilation 1st&2nd&3rd" 6 "Driver Seat Warmer 1st ON" 7 "Driver Seat Warmer 1st&2nd ON" 8 "Driver Seat Warmer 1st&2nd&3rd ON" 9 "Reserved" 10 "Reserved" 11 "Reserved" 12 "Reserved" 13 "Reserved" 14 "Reserved" 15 "Invalid" ;
VAL_ 1495 CF_Bms_EvReady 0 "Not ready" 1 "Ready" ;
VAL_ 1495 CF_Bms_NoError 0 "Error" 1 "No Error" ;
VAL_ 1495 CF_Bms_Fail_Temp 0 "Normal" 1 "Fail" ;
VAL_ 1495 CF_Bms_FAILED_EVShiftPosition 0 "Normal" 1 "Fail" ;
VAL_ 1495 CF_Bms_Fail_Conlock 0 "Normal" 1 "Fail" ;
VAL_ 1495 CF_Bms_Fail_Evmalf 0 "Normal" 1 "Fail" ;
VAL_ 1495 CF_Bms_Fail_CurrDiff 0 "Normal" 1 "Fail" ;
VAL_ 1495 CF_Bms_Fail_VoltRange 0 "Normal" 1 "Fail" ;
VAL_ 1495 CF_Bms_Fail_ChgSysIncom 0 "Normal" 1 "Fail" ;
VAL_ 1495 CF_Bms_ReadyToCharge 0 "Normal" 1 "Ready To Charge" ;
VAL_ 1495 CF_Bms_ChgFinished 0 "Normal" 1 "Charge finish" ;
VAL_ 1495 CF_Bms_PreparationStatusForPLC 0 "Normal" 1 "Ready For PLC" ;
VAL_ 1495 CF_Bms_ReadyForCurDem 0 "Normal" 1 "Ready For Current Demand" ;
VAL_ 1495 CF_Bms_IG3RlyOffEnable 0 "Normal" 1 "IG3 Rly Off Enable" ;
VAL_ 1495 CF_Bms_Charging_ST 0 "Charging Cycle Start Disable" 1 "Charging Cycle Start Enable" ;
VAL_ 1495 CF_Bms_Lamp_Req 0 "Off" 1 "Lamp On" ;
VAL_ 1492 IBOX_IVRActivity 0 "Deactivated" 1 "Activated" 2 "reserved" 3 "Invalid" ;
VAL_ 1492 IBOX_PhoneActivity 0 "Deactivated" 1 "Activated" 2 "reserved" 3 "Invalid" ;
VAL_ 1493 CF_Bms_FstEvseFltAlram 0 "Normal" 1 "Alraming Evse Fault" ;
VAL_ 1493 CF_Bms_WeldDctFinish 0 "Normal" 1 "WeldDetection Finished" ;
VAL_ 1493 CF_Bms_BatEvtAlarm 0 "Normal" 1 "Level 1" 2 "Level 2" 3 "Level 3" 4 "Level 4" 15 "Invalid" ;
VAL_ 1491 HU_VRActivity 0 "Deactivated" 1 "Activated" 2 "reserved" 3 "Invalid" ;
VAL_ 1491 HU_PhoneActivity 0 "Deactivated" 1 "Activated" 2 "reserved" 3 "Invalid" ;
VAL_ 1491 HU_DATC_AirQuality_Info 0 "No information" 1 "level1" 2 "level2" 3 "level3" 4 "level4" 5 "level5" 6 "level6" 8 "reserved" 9 "reserved" 10 "reserved" 11 "reserved" 12 "reserved" 13 "reserved" 14 "reserved" 15 "invalid" ;
VAL_ 1488 CF_LKA_Opt_USM 0 "None LKA/LDW Option" 1 "LDW" 2 "LKA" 3 "ACTIVE LKA" 4 "LDW Only (None LKA)" 5 "LDW Only OFF (None LKA)" 6 "LDW/LKA OFF" 7 "Invalid" ;
VAL_ 1503 HU_AliveStatus 0 "Not Ready" 1 "On mode" 2 "Head Unit Update Mode" 3 "Invalid" ;
VAL_ 1503 HU_NaviStatus 0 "Booting" 1 "Normal Operation" 2 "No SD Card(MAP)" 3 "Invalid" ;
VAL_ 1503 HU_Navigation_On_Off 0 "Off" 1 "On" 2 "Reserved" 3 "Invalid" ;
VAL_ 1503 HU_Type 16 "AVN(Tuner DVD KOR)" 17 "AVN(Tuner DVD EUR)" 18 "AVN(Tuner DVD China)" 19 "AVN(Tuner DVD Japan)" 20 "AVN(Tuner DVD EUR)" 21 "AVN(Tuner CDP KOR)" 22 "AVN(Tuner CDP EUR)" 23 "AVN(Tuner CDP China)" 24 "AVN(Tuner CDP Japan)" 25 "AVN(Tuner CDP EUR)" 32 "AVNT (Open)" 33 "AVNT (Not open)" 48 "Economic Audio" 64 "Standard Audio (3.0 below)" 65 "Standard Audio 4.0" 66 "STD Audio-3.0Below,No interwork" 80 "AV(Tuner DVD KOR)" 81 "AV(Tuner DVD EUR)" 82 "AV(Tuner DVD China)" 83 "AV(Tuner DVD Japan)" 84 "AV(Tuner DVD EUR)" 85 "AV(Tuner CDP KOR)" 86 "AV(Tuner CDP EUR)" 87 "AV(Tuner CDP China)" 88 "AV(Tuner CDP Japan)" 89 "AV(Tuner CDP EUR)" 96 "AVN 4.0" 97 "Premium AVN2.0" 98 "EU AVN 2.0" 99 "Super Premium w Navi" 100 "Super Premium w_o Navi" 101 "Premium w Navi" 102 "Premium w_o Navi" 103 "Display Audio w_o Navi" 104 "Integrated AVN 1.0 Mobis" 105 "Gen5 Standard Nav Wide" 112 "Compact AVN & Integrated AVN 1.0 LG" 128 "Premium Navi 5th Gen(w/Navi)" 129 "Premium Navi 5th Gen(w/o Navi)" 130 "Premium Navi 6th Gen(w/Navi)" 131 "Premium Navi 6th Gen(w/o Navi)" 250 "PIO AVN" 251 "China only OEM AV" 252 "China OPIO w/o CLU interface" 253 "China OPIO w/CLU interface" 254 "Áß±¹ LOCAL OEM AVNT" 255 "Invalid" ;
VAL_ 1503 HU_DistributeInfo 0 "Default (Korea)" 1 "Korea" 2 "North America" 3 "Canada" 4 "East Europe" 5 "West Europe" 6 "China" 7 "India" 8 "Australia" 9 "Middle East" 10 "Africa" 11 "South America" 12 "Reserved" 13 "Reserved" 14 "General" 15 "0x0F~0xFE:Reserved" 254 "0x0F~0xFE:Reserved" 255 "Invalid" ;
VAL_ 1503 HU_AdasSupport 0 "Not Support" 1 "ADAS Support(General Map)" 2 "ADAS Support(Precise Map1)" 3 "ADAS Support(Precise Map2)" 4 "Reserved" 5 "Reserved" 6 "Reserved" 7 "Invalid" ;
VAL_ 674 CF_Brk_EBSStat 0 "Not Ready" 1 "Ready" ;
VAL_ 674 CF_Brk_SnsFail 0 "Normal" 1 "Fail" ;
VAL_ 674 CF_Brk_RBSWLamp 0 "RBS Warning Lamp OFF" 1 "RBS Warning Lamp ON" ;
VAL_ 674 CF_Brk_VacuumSysDef 0 "Vacuum pump NOT defective" 1 "Vacuum pump defective (failed)" ;
VAL_ 673 CF_Mcu_RsvSnslessStatForClu 0 "Normal" 1 "Sensorless" ;
VAL_ 1496 CF_Bms_ServiceLamp 0 "Off" 1 "Service Lamp On" ;
VAL_ 1496 CF_Bms_Flt 0 "Noraml" 1 "Fault" ;
VAL_ 1496 CF_Bms_StdCha_120V 0 "None" 1 "Standard Charging By 120V" ;
VAL_ 1496 CF_Bms_StdCha 0 "None" 1 "Standard Charging" ;
VAL_ 1496 CF_Bms_ChgSts 0 "None" 1 "Charging" ;
VAL_ 1496 CF_BMS_ChgFinishedForOBC 0 "Normal" 1 "Charge Finish" ;
VAL_ 1496 CF_Bms_MainRlyOnStat 0 "Off" 1 "On" ;
VAL_ 1496 CF_Bms_LdcInh 0 "Noraml" 1 "LDC Inhibit" ;
VAL_ 1497 CF_Vcu_SmartEcoDisp 0 "Smart ECO Guide Off" 1 "Smart ECO Guide On" ;
VAL_ 1497 CR_Vcu_RegenRangeAddSet 0 "Default" 1 "--Ç¥½Ã(Å¬·¯½ºÅÍ »ó --.- Ç¥½Ã)" 2 "Positive Value (+Ç¥½Ã)" 3 "Negative Value (-Ç¥½Ã)" ;
VAL_ 1497 CR_Vcu_SmartEcoRng 0 "Not Display" 1 "1~100%" 2 "1~100%" 3 "1~100%" 4 "1~100%" 5 "1~100%" 6 "1~100%" 7 "1~100%" 8 "1~100%" 9 "1~100%" 10 "1~100%" 11 "1~100%" 12 "1~100%" 13 "1~100%" 14 "1~100%" 15 "1~100%" 16 "1~100%" 17 "1~100%" 18 "1~100%" 19 "1~100%" 20 "1~100%" 21 "1~100%" 22 "1~100%" 23 "1~100%" 24 "1~100%" 25 "1~100%" 26 "1~100%" 27 "1~100%" 28 "1~100%" 29 "1~100%" 30 "1~100%" 31 "1~100%" 32 "1~100%" 33 "1~100%" 34 "1~100%" 35 "1~100%" 36 "1~100%" 37 "1~100%" 38 "1~100%" 39 "1~100%" 40 "1~100%" 41 "1~100%" 42 "1~100%" 43 "1~100%" 44 "1~100%" 45 "1~100%" 46 "1~100%" 47 "1~100%" 48 "1~100%" 49 "1~100%" 50 "1~100%" 51 "1~100%" 52 "1~100%" 53 "1~100%" 54 "1~100%" 55 "1~100%" 56 "1~100%" 57 "1~100%" 58 "1~100%" 59 "1~100%" 60 "1~100%" 61 "1~100%" 62 "1~100%" 63 "1~100%" 64 "1~100%" 65 "1~100%" 66 "1~100%" 67 "1~100%" 68 "1~100%" 69 "1~100%" 70 "1~100%" 71 "1~100%" 72 "1~100%" 73 "1~100%" 74 "1~100%" 75 "1~100%" 76 "1~100%" 77 "1~100%" 78 "1~100%" 79 "1~100%" 80 "1~100%" 81 "1~100%" 82 "1~100%" 83 "1~100%" 84 "1~100%" 85 "1~100%" 86 "1~100%" 87 "1~100%" 88 "1~100%" 89 "1~100%" 90 "1~100%" 91 "1~100%" 92 "1~100%" 93 "1~100%" 94 "1~100%" 95 "1~100%" 96 "1~100%" 97 "1~100%" 98 "1~100%" 99 "1~100%" 100 "1~100%" 101 "Reserved" 102 "Reserved" 103 "Reserved" 104 "Reserved" 105 "Reserved" 106 "Reserved" 107 "Reserved" 108 "Reserved" 109 "Reserved" 110 "Reserved" 111 "Reserved" 112 "Reserved" 113 "Reserved" 114 "Reserved" 115 "Reserved" 116 "Reserved" 117 "Reserved" 118 "Reserved" 119 "Reserved" 120 "Reserved" 121 "Reserved" 122 "Reserved" 123 "Reserved" 124 "Reserved" 125 "Reserved" 126 "Reserved" 127 "Reserved" ;
VAL_ 1497 CR_Vcu_SmartEcoLvl 0 "Not Display" 1 "1~100%" 2 "1~100%" 3 "1~100%" 4 "1~100%" 5 "1~100%" 6 "1~100%" 7 "1~100%" 8 "1~100%" 9 "1~100%" 10 "1~100%" 11 "1~100%" 12 "1~100%" 13 "1~100%" 14 "1~100%" 15 "1~100%" 16 "1~100%" 17 "1~100%" 18 "1~100%" 19 "1~100%" 20 "1~100%" 21 "1~100%" 22 "1~100%" 23 "1~100%" 24 "1~100%" 25 "1~100%" 26 "1~100%" 27 "1~100%" 28 "1~100%" 29 "1~100%" 30 "1~100%" 31 "1~100%" 32 "1~100%" 33 "1~100%" 34 "1~100%" 35 "1~100%" 36 "1~100%" 37 "1~100%" 38 "1~100%" 39 "1~100%" 40 "1~100%" 41 "1~100%" 42 "1~100%" 43 "1~100%" 44 "1~100%" 45 "1~100%" 46 "1~100%" 47 "1~100%" 48 "1~100%" 49 "1~100%" 50 "1~100%" 51 "1~100%" 52 "1~100%" 53 "1~100%" 54 "1~100%" 55 "1~100%" 56 "1~100%" 57 "1~100%" 58 "1~100%" 59 "1~100%" 60 "1~100%" 61 "1~100%" 62 "1~100%" 63 "1~100%" 64 "1~100%" 65 "1~100%" 66 "1~100%" 67 "1~100%" 68 "1~100%" 69 "1~100%" 70 "1~100%" 71 "1~100%" 72 "1~100%" 73 "1~100%" 74 "1~100%" 75 "1~100%" 76 "1~100%" 77 "1~100%" 78 "1~100%" 79 "1~100%" 80 "1~100%" 81 "1~100%" 82 "1~100%" 83 "1~100%" 84 "1~100%" 85 "1~100%" 86 "1~100%" 87 "1~100%" 88 "1~100%" 89 "1~100%" 90 "1~100%" 91 "1~100%" 92 "1~100%" 93 "1~100%" 94 "1~100%" 95 "1~100%" 96 "1~100%" 97 "1~100%" 98 "1~100%" 99 "1~100%" 100 "1~100%" 101 "Reserved" 102 "Reserved" 103 "Reserved" 104 "Reserved" 105 "Reserved" 106 "Reserved" 107 "Reserved" 108 "Reserved" 109 "Reserved" 110 "Reserved" 111 "Reserved" 112 "Reserved" 113 "Reserved" 114 "Reserved" 115 "Reserved" 116 "Reserved" 117 "Reserved" 118 "Reserved" 119 "Reserved" 120 "Reserved" 121 "Reserved" 122 "Reserved" 123 "Reserved" 124 "Reserved" 125 "Reserved" 126 "Reserved" 127 "Reserved" ;
VAL_ 1497 CR_Vcu_RegenRangeAdd 0 "0x0~0x3FF: 0~10230" 1023 "0x0~0x3FF: 0~10230" ;
VAL_ 1497 CF_Vcu_WarnMsg 0 "None (Default)" 1 "Regenerative Braking System Operating Stop" 2 "AC,PTC Controllable when EV_Ready is OFF" 3 "Max Motor RPM Warning (only HR/PU EV)" 4 "Gear P Change Impossible (VB 10.5V)" 5 "Gear P Change Impossible (VB 9.5V)" 6 "-" 7 "-" 8 "" 9 "" 10 "" 11 "" 12 "" 13 "" 14 "" 15 "" ;
VAL_ 1497 CF_Vcu_FueEffStat 0 "Invalid" 1 "Valid" ;
VAL_ 1497 CF_Vcu_FueEffStatBox 0 "None" 1 "High fuel efficiency" 2 "Normal fuel efficiency" 3 "Low fuel efficiency" ;
VAL_ 1497 CR_Vcu_HighFueEff_Pc 0 "0x0~0x64:0~100%" 100 "0x0~0x64:0~100%" 101 "Reserved" 102 "Reserved" 103 "Reserved" 104 "Reserved" 105 "Reserved" 106 "Reserved" 107 "Reserved" 108 "Reserved" 109 "Reserved" 110 "Reserved" 111 "Reserved" 112 "Reserved" 113 "Reserved" 114 "Reserved" 115 "Reserved" 116 "Reserved" 117 "Reserved" 118 "Reserved" 119 "Reserved" 120 "Reserved" 121 "Reserved" 122 "Reserved" 123 "Reserved" 124 "Reserved" 125 "Reserved" 126 "Reserved" 127 "Reserved" ;
VAL_ 1497 CR_Vcu_NorFueEff_Pc 0 "0x0~0x64:0~100%" 100 "0x0~0x64:0~100%" 101 "Reserved" 102 "Reserved" 103 "Reserved" 104 "Reserved" 105 "Reserved" 106 "Reserved" 107 "Reserved" 108 "Reserved" 109 "Reserved" 110 "Reserved" 111 "Reserved" 112 "Reserved" 113 "Reserved" 114 "Reserved" 115 "Reserved" 116 "Reserved" 117 "Reserved" 118 "Reserved" 119 "Reserved" 120 "Reserved" 121 "Reserved" 122 "Reserved" 123 "Reserved" 124 "Reserved" 125 "Reserved" 126 "Reserved" 127 "Reserved" ;
VAL_ 1497 CR_Vcu_LowFueEff_Pc 0 "0x0~0x64:0~100%" 100 "0x0~0x64:0~100%" 101 "Reserved" 102 "Reserved" 103 "Reserved" 104 "Reserved" 105 "Reserved" 106 "Reserved" 107 "Reserved" 108 "Reserved" 109 "Reserved" 110 "Reserved" 111 "Reserved" 112 "Reserved" 113 "Reserved" 114 "Reserved" 115 "Reserved" 116 "Reserved" 117 "Reserved" 118 "Reserved" 119 "Reserved" 120 "Reserved" 121 "Reserved" 122 "Reserved" 123 "Reserved" 124 "Reserved" 125 "Reserved" 126 "Reserved" 127 "Reserved" ;
VAL_ 1497 CF_Vcu_StartKeyWarnMsg 0 "Off" 1 "Warning Status" ;
VAL_ 1474 CF_Clu_InletAutoLockNValueSet 0 "Default" 1 "Auto mode" 2 "Lcok mode" 3 "Unlock mode" 7 "Invalid" ;
VAL_ 1245 CR_Bms_3wayVav_CtrlMode 0 "Separate mode" 1 "Series mode" ;
VAL_ 1245 CF_Bms_WCS_HeaterRlyOnStat 0 "Relay Off" 1 "Relay On" ;
VAL_ 1245 CF_Bms_CoolantShortage 0 "None" 1 "Coolant Shortage" ;
VAL_ 1245 CF_Bms_EwpDiagModeEna 0 "None" 1 "EWP diagnostic mode request" ;
VAL_ 1246 CF_Bms_FatcWHRLoopInh 0 "None" 1 "Inhibition request" ;
VAL_ 1246 CR_Bms_3WayVav_CtrlMode2 0 "Control mode 1" 1 "Control mode 2" ;
VAL_ 1246 CF_Bms_BTMSdiag_flag 0 "normal state" 1 "abnormal  state" ;
VAL_ 1484 DATC_ModeDisp 0 "(Blank)" 1 "VENT" 2 "B/L" 3 "FLOOR" 4 "MIX" 5 "DEF" 6 "AUTO DEFOG" 7 "7MODE DEF VENT" 8 "MODE AUTO" 9 "7MODE DEF VENT FLOOR" 10 "7MODE DEF" 11 "DEF VENT (Arrow)" 12 "DEF FLOOR (Arrow)" 13 "DEF VENT FLOOR (Arrow)" 14 "DEF (Arrow)" 15 "Invalid" ;
VAL_ 1484 DATC_TempUnit 0 "Centigrade" 1 "Fahrenheit" 2 "Not Used" 3 "Invalid" ;
VAL_ 1484 DATC_SepzoneDisp 0 "Off" 1 "Separte zone ON" 2 "reserved" 3 "Invalid" ;
VAL_ 1484 DATC_AutoDisp 0 "Auto OFF" 1 "AUTO ON" 2 "not used" 3 "invalid" ;
VAL_ 1484 DATC_IntakeDisp 0 "REC OFF(FRE ON)" 1 "REC ON" 2 "not used" 3 "invalid" ;
VAL_ 1484 DATC_ChangeReqDisp 0 "Off" 1 "User Input" 2 "Not Used" 3 "Invalid" ;
VAL_ 1484 CF_Datc_Text_PopupReq 0 "Off" 1 "TEXT POP-UP Request On" 2 "reserverd" 3 "Invalid" ;
VAL_ 1484 DATC_AcDisp 0 "A_C OFF" 1 "A_C ON" 2 "not used" 3 "invalid" ;
VAL_ 1484 DATC_AqsDisp 0 "AQS OFF" 1 "AQS ON" 2 "not used" 3 "invalid" ;
VAL_ 1484 DATC_ClimateScnDisp 0 "Deactivated" 1 "Activated" 2 "Not Used" 3 "Invalid" ;
VAL_ 1484 DATC_AirCleaningSystemStatus 0 "Air Cleaning System Off" 1 "Air Cleaning System On" 2 "Air Cleaning System Not Support" 3 "Invalid" ;
VAL_ 1484 DATC_SyncDisp 0 "Sync OFF" 1 "Sync ON" 2 "not used" 3 "invalid" ;
VAL_ 1484 CF_Datc_BlowerAutoDisp 0 "Default" 1 "Blank" 2 "Auto" 3 "Invalid" ;
VAL_ 1484 DATC_OpSts 0 "DATC Off (Power Down)" 1 "DATC Normal" 2 "DATC System Off (Blower Off)" 3 "DATC Self Diagnosis" 4 "Not Used" 5 "Not Used" 6 "Not Used" 7 "Inavalid" ;
VAL_ 1484 DATC_RearManual 0 "Null" 1 "Enable" 2 "Disable" 3 "(Invalid)" ;
VAL_ 1484 DATC_HeatDisp 0 "Heat OFF" 1 "Heat ON" 2 "not used" 3 "invalid" ;
VAL_ 1484 DATC_FrDefLed 0 "Off" 1 "On" 2 "Not Used" 3 "Invalid" ;
VAL_ 1484 CF_Datc_ModAutoDisp 0 "Default" 1 "Blank" 2 "Auto" 3 "Invalid" ;
VAL_ 1484 DATC_AutoDefogBlink 0 "Not Active" 1 "ADS Blink Active" 2 "Not used" 3 "Invalid" ;
VAL_ 1484 CF_Datc_IntakeStatus 0 "Not used" 1 "REC (Fresh off)" 2 "FRE (REC off)" 3 "Invalid" ;
VAL_ 1484 DATC_IonClean 0 "Off" 1 "Clean" 2 "Ion" 3 "Inavalid" ;
VAL_ 1484 DATC_CO2Warning 0 "Off" 1 "CO2 Warning" 2 "reserved" 3 "Invalid" ;
VAL_ 1484 DATC_SubBlowerDisp 0 "Off" 1 "(Blank)" 2 "1 level" 3 "2 level" 4 "3 level" 5 "4 level" 6 "5 level" 7 "6 level" 8 "7 level" 9 "8 level" 10 "BLOWER AUTO" 11 "not used" 12 "not used" 13 "not used" 14 "not used" 15 "invalid" ;
VAL_ 1484 DATC_BeepReq 0 "beep off" 1 "beep1 on" 2 "beep2 on" 3 "Beep1 Off" 4 "Beep2 Off" 15 "Invalid" ;
VAL_ 1484 DATC_MainBlowerDisp 0 "Off" 1 "Blank Display(Blower ´Ü¼ö ¹ÌÇ¥½Ã, ¿¹)Auto ½Ã)" 2 "1 level" 3 "2 level" 4 "3 level" 5 "4 level" 6 "5 level" 7 "6 level" 8 "7 level" 9 "8 level" 10 "BLOWER AUTO" 11 "not used" 12 "not used" 13 "not used" 14 "not used" 15 "invalid" ;
VAL_ 1484 DATC_PsModeDisp 0 "(Blank)" 1 "VENT" 2 "B/L" 3 "FLOOR" 4 "MIX" 5 "DEF" 6 "AUTO DEFOG" 7 "7MODE DEF VENT" 8 "MODE AUTO" 9 "7MODE DEF VENT FLOOR" 10 "7MODE DEF" 11 "DEF VENT (Arrow)" 12 "DEF FLOOR (Arrow)" 13 "DEF VENT FLOOR (Arrow)" 14 "DEF (Arrow)" 15 "invalid" ;
VAL_ 1483 CR_Datc_DrTempDispC 0 "Blank Display" 1 "'LO' Display" 254 "'HI' Display" 255 "Invalid" ;
VAL_ 1483 CR_Datc_DrTempDispF 0 "Blank Display" 1 "'LO' Display" 254 "'HI' Display" 255 "Invalid" ;
VAL_ 1483 CR_Datc_PsTempDispC 0 "Blank Display" 1 "'LO' Display" 254 "'HI' Display" 255 "Invalid" ;
VAL_ 1483 CR_Datc_PsTempDispF 0 "Blank Display" 1 "'LO' Display" 254 "'HI' Display" 255 "Invalid" ;
VAL_ 1483 CF_DATC_TempDisp_Sts 0 "OLD Set Temp Display range" 1 "NEW Set Temp Display Range" 2 "Not used" 3 "Invalid" ;
VAL_ 1483 CF_Datc_DefLogic_USM_State 0 "Default" 1 "OFF" 2 "ON" 3 "Invalid" ;
VAL_ 1483 CF_Datc_AutoFresh_USM_State 0 "Default" 1 "OFF" 2 "ON" 3 "Invalid" ;
VAL_ 1483 DATC_AutoArClnUSMState 0 "Default" 1 "Auto AirCleaning USM OFF" 2 "Auto AirCleaning USM ON" 3 "Invalid" ;
VAL_ 1483 CR_Datc_RearDrTempDispC 0 "Blank Display" 1 "'LO' Display" 254 "'HI' Display" 255 "Invalid" ;
VAL_ 1483 CR_Datc_RearDrTempDispF 0 "Blank Display" 1 "'LO' Display" 254 "'HI' Display" 255 "Invalid" ;
VAL_ 1482 CR_Datc_OutTempC 0 "Blank Display" 1 "Blank Display" 254 "Sensor Fail ( - - Display )" 255 "Invalid" ;
VAL_ 1482 CR_Datc_OutTempF 0 "Blank Display" 1 "Blank Display" 254 "Sensor Fail ( - - Display )" 255 "Invalid" ;
VAL_ 1482 CR_NomalClimateLimitStatus 0 "Off(Default)" 1 "ClimateLimit Setting On" 2 "rserved" 3 "invalid" ;
VAL_ 1482 CR_SportClimateLimitStatus 0 "Off(Default)" 1 "ClimateLimit  Setting On" 2 "rserved" 3 "invalid" ;
VAL_ 1482 CR_EcoClimateLimitStatus 0 "Off" 1 "ClimateLimit Setting On" 2 "rserved" 3 "invalid" ;
VAL_ 1482 CR_Datc_ClimateLimit_OpSts 0 "Off" 1 "Operating ClimateLimit" 2 "rserved" 3 "invalid" ;
VAL_ 1481 CR_Bcf_MotStatus 0 "Ready" 1 "Initial" 2 "Running" 3 "Fault Stop" ;
VAL_ 1525 CF_Datc_AcnReqSwi 0 "A/C Non-Request" 1 "A/C Request" ;
VAL_ 1525 CF_Datc_BlrOn 0 "Blower Off" 1 "Blower On" ;
VAL_ 1525 CF_Datc_PtcOnReq 0 "PTC Non_Request" 1 "PTC Request" ;
VAL_ 1525 CF_Datc_AcnCompOperStat 0 "A/C Compressor Off" 1 "A/C Compressor On" ;
VAL_ 1525 CF_Datc_PTCOperStat 0 "PTC Off" 1 "PTC On" ;
VAL_ 1525 CF_Datc_BlwrMax 0 "Max Blower Speed is not selected" 1 "Max Blower Speed is selected" ;
VAL_ 1525 CF_Datc_AcnCompFlt 0 "A/C Compressor Normal" 1 "A/C Compressor Fail" ;
VAL_ 1525 CF_Datc_PTCFlt 0 "PTC Normal" 1 "PTC Fail" ;
VAL_ 1525 CF_Datc_WaterValve_Status 0 "Coolant to Radiator" 1 "Coolant to Chiller" ;
VAL_ 1525 CF_Datc_CompType 0 "Mechanical Compressor" 1 "Electronic Compressor" 2 "Non-A/C" 3 "Not Used" ;
VAL_ 1525 CF_Datc_HvIntlockReq 1 "Not Request" 1 "Request" ;
VAL_ 1525 CF_Datc_HeatPumpType 0 "Non-HeatPump System" 1 "HeatPump System" ;
VAL_ 1525 CF_Datc_PTCType 0 "High Voltage PTC" 1 "Low Voltage PTC" 2 "Non-PTC" 3 "Not Used" ;
VAL_ 1525 CF_Datc_HVCompInterlock 0 "Open" 1 "Close" ;
VAL_ 1525 CF_Datc_HVPtcInterlock 0 "Open" 1 "Close" ;
VAL_ 1252 CF_Ewp_FltStatus 0 "Normal" 1 "Fault" ;
VAL_ 1252 CF_Ewp_ProtectMode 0 "Normal" 1 "EWP Protection Mode" ;
VAL_ 1252 Eeprom_Pop_Up_Short 0 "Normal" 1 "EWP Protection Mode" ;
VAL_ 1252 Eeprom_Pop_Up_Gduv 0 "Normal" 1 "EWP Protection Mode" ;
VAL_ 1252 Eeprom_Pop_Up_Phase_Open 0 "Normal" 1 "EWP Protection Mode" ;
VAL_ 1252 Eeprom_Pop_Up_Stalled 0 "Normal" 1 "EWP Protection Mode" ;
VAL_ 1252 Eeprom_Pop_Up_Lc 0 "Normal" 1 "EWP Protection Mode" ;
VAL_ 1252 Eeprom_Pop_Up_Oc 0 "Normal" 1 "EWP Protection Mode" ;
VAL_ 1252 Eeprom_Pop_Up_Lv 0 "Normal" 1 "EWP Protection Mode" ;
VAL_ 1252 Eeprom_Pop_Up_Hv 0 "Normal" 1 "EWP Protection Mode" ;
VAL_ 1252 CF_Short_Ouput_Circuit 0 "Normal" 1 "EWP Protection Mode" ;
VAL_ 1252 CF_Gduv 0 "Normal" 1 "EWP Protection Mode" ;
VAL_ 1252 CF_Low_Current 0 "Normal" 1 "EWP Protection Mode" ;
VAL_ 1252 CF_Over_Current 0 "Normal" 1 "EWP Protection Mode" ;
VAL_ 1252 CF_Low_Voltage 0 "Normal" 1 "EWP Protection Mode" ;
VAL_ 1252 CF_High_Voltage 0 "Normal" 1 "EWP Protection Mode" ;
VAL_ 1252 CF_Speed_Error 0 "Normal" 1 "EWP Protection Mode" ;
VAL_ 1527 CF_Datc_ServiceLamp 0 "Service Lamp(for FATC) Off" 1 "Service Lamp(for FATC) On" ;
VAL_ 1527 CF_Datc_Controllable 0 "Not Controllable" 1 "Controllable" ;
VAL_ 1527 CF_Datc_Heatpump_Mode 0 "A/C" 1 "H/P A" 2 "H/P A-1" 3 "H/P B" 4 "H/P B-1" 5 "PTC Only" 6 "FAN Only" 7 "OFF" 8 "Else" 9 "Reserved" 10 "Reserved" 11 "Reserved" 12 "Reserved" 13 "Reserved" 14 "Reserved" 15 "Invalid" ;
VAL_ 1527 CR_Fatc_BatChiValve_Status 0 "OPEN" 1 "CLOSE" 2 "reserved" 3 "Invalid" ;
VAL_ 1527 CR_Fatc_BatChiValve_FltCode 0 "no error" 1 "error" 2 "reserved" 3 "Invalid" ;
VAL_ 1527 CR_Fatc_BatEvapValve_Status 0 "Valve Off (OPEN)" 1 "Valve On (CLOSE)" 2 "reserved" 3 "Invalid" ;
VAL_ 1527 CR_Fatc_BatEvapValve_FltCode 0 "no error" 1 "error" 2 "reserved" 3 "Invalid" ;
